[part 1 of 3: package /STLASWCs]
AUTOSAR XML (schema 4-3-0)
package /STLASWCs
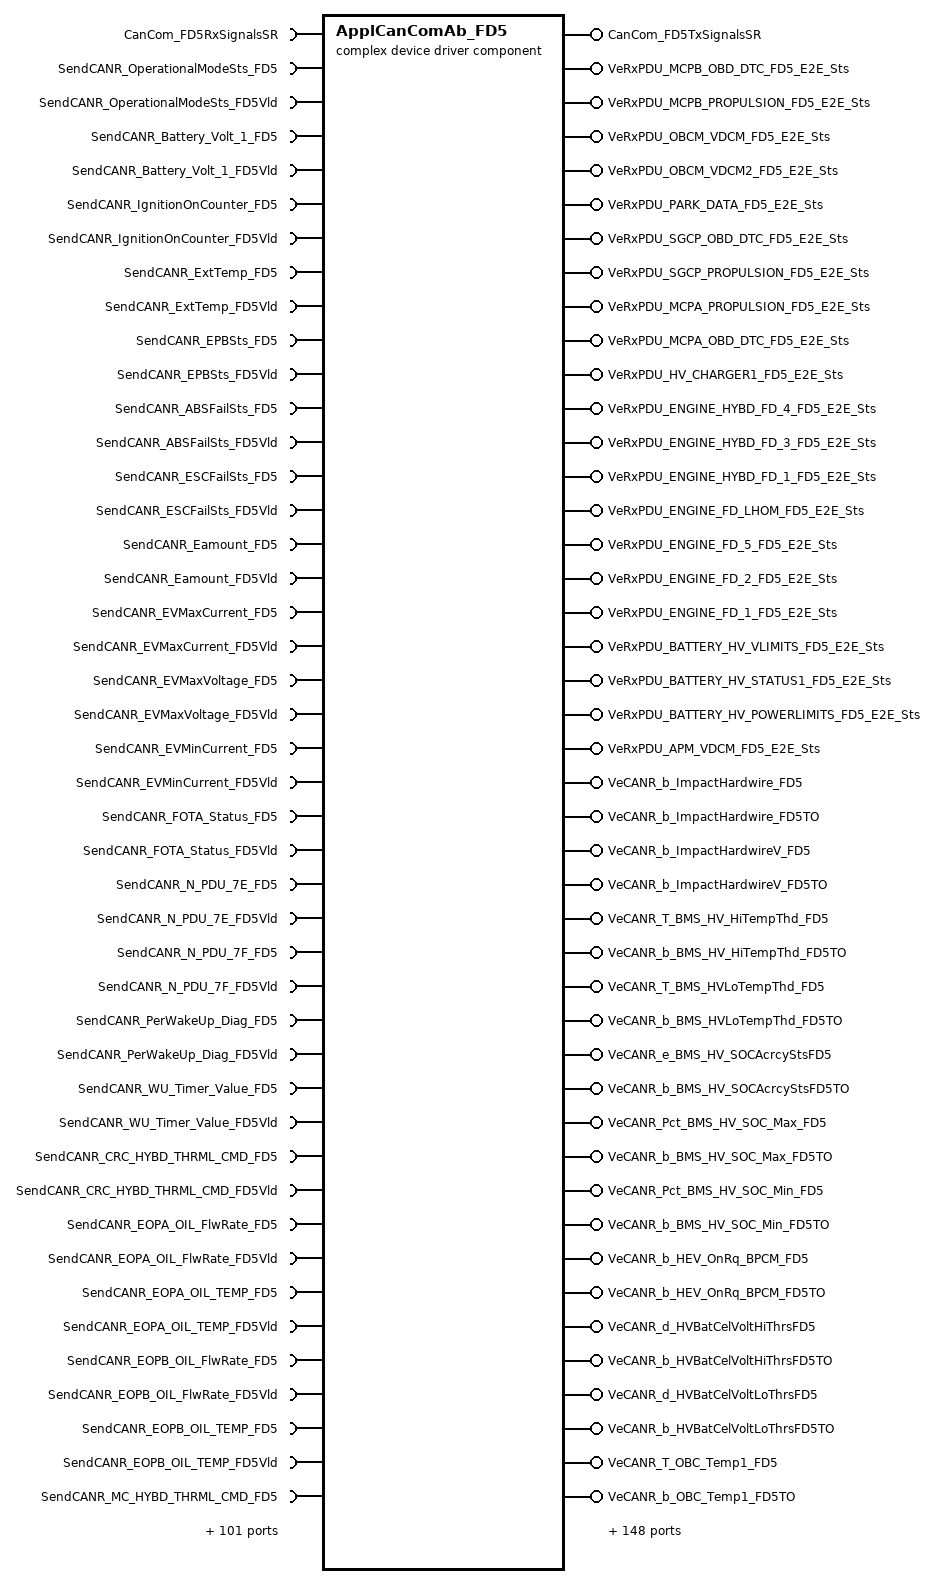
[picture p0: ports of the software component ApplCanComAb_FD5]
  complex device driver sw component type ApplCanComAb_FD5  # Application CAN Communication Abstraction Component - is responsible with receiving and sending CAN data from/to the lower BSW COM layers
    22 x provide port:
      CanCom_FD5TxSignalsSR: provided-interface=CanCom_FD5TxSignalsSR
        provided-com-specs:
          data-element=COMTX_OperationalModeSts_BCM_FD_2_FD5, init-value=constant-reference=COMTX_OperationalModeSts_BCM_FD_2_FD5_Init
          data-element=COMTX_Battery_Volt_1_BCM_FD_3_FD5, init-value=constant-reference=COMTX_Battery_Volt_1_BCM_FD_3_FD5_Init
          data-element=COMTX_IgnitionOnCounter_BCM_FD_7_FD5, init-value=constant-reference=COMTX_IgnitionOnCounter_BCM_FD_7_FD5_Init
          data-element=COMTX_ExternalTemperature_BCM_FD_9_FD5, init-value=constant-reference=COMTX_ExternalTemperature_BCM_FD_9_FD5_Init
          data-element=COMTX_EPBSts_BRAKE_FD_4_FD5, init-value=constant-reference=COMTX_EPBSts_BRAKE_FD_4_FD5_Init
          data-element=COMTX_ABSFailSts_BRAKE_FD_5_FD5, init-value=constant-reference=COMTX_ABSFailSts_BRAKE_FD_5_FD5_Init
          data-element=COMTX_ESCFailSts_BRAKE_FD_5_FD5, init-value=constant-reference=COMTX_ESCFailSts_BRAKE_FD_5_FD5_Init
          data-element=COMTX_Eamount_EVCU_ISO15118_STATUS1_FD5, init-value=constant-reference=COMTX_Eamount_EVCU_ISO15118_STATUS1_FD5_Init
          data-element=COMTX_EVMaxCurrent_EVCU_ISO15118_STATUS1_FD5, init-value=constant-reference=COMTX_EVMaxCurrent_EVCU_ISO15118_STATUS1_FD5_Init
          data-element=COMTX_EVMaxVoltage_EVCU_ISO15118_STATUS1_FD5, init-value=constant-reference=COMTX_EVMaxVoltage_EVCU_ISO15118_STATUS1_FD5_Init
          data-element=COMTX_EVMinCurrent_EVCU_ISO15118_STATUS1_FD5, init-value=constant-reference=COMTX_EVMinCurrent_EVCU_ISO15118_STATUS1_FD5_Init
          data-element=COMTX_FOTA_Status_FOTA_MASTER_FD5, init-value=constant-reference=COMTX_FOTA_Status_FOTA_MASTER_FD5_Init
          data-element=COMTX_N_PDU_7E_GLIWA_MCPA_RX_FD5, init-value=constant-reference=COMTX_N_PDU_7E_GLIWA_MCPA_RX_FD5_Init
          data-element=COMTX_N_PDU_7F_GLIWA_MCPB_RX_FD5, init-value=constant-reference=COMTX_N_PDU_7F_GLIWA_MCPB_RX_FD5_Init
          data-element=COMTX_PerWakeUp_Diag_HYBRID_SYSTEM_EPT1_FD5, init-value=constant-reference=COMTX_PerWakeUp_Diag_HYBRID_SYSTEM_EPT1_FD5_Init
          data-element=COMTX_WU_Timer_Value_HYBRID_SYSTEM_EPT1_FD5, init-value=constant-reference=COMTX_WU_Timer_Value_HYBRID_SYSTEM_EPT1_FD5_Init
          data-element=COMTX_CRC_HYBRID_THERMAL_COMMAND_HYBRID_THERMAL_COMMAND_FD5, init-value=constant-reference=COMTX_CRC_HYBRID_THERMAL_COMMAND_HYBRID_THERMAL_COMMAND_FD5_Init
          data-element=COMTX_EOPA_OIL_FlwRate_HYBRID_THERMAL_COMMAND_FD5, init-value=constant-reference=COMTX_EOPA_OIL_FlwRate_HYBRID_THERMAL_COMMAND_FD5_Init
          data-element=COMTX_EOPA_OIL_TEMP_HYBRID_THERMAL_COMMAND_FD5, init-value=constant-reference=COMTX_EOPA_OIL_TEMP_HYBRID_THERMAL_COMMAND_FD5_Init
          data-element=COMTX_EOPB_OIL_FlwRate_HYBRID_THERMAL_COMMAND_FD5, init-value=constant-reference=COMTX_EOPB_OIL_FlwRate_HYBRID_THERMAL_COMMAND_FD5_Init
          data-element=COMTX_EOPB_OIL_TEMP_HYBRID_THERMAL_COMMAND_FD5, init-value=constant-reference=COMTX_EOPB_OIL_TEMP_HYBRID_THERMAL_COMMAND_FD5_Init
          data-element=COMTX_MessageCounter_HYBRID_THERMAL_COMMAND_HYBRID_THERMAL_COMMAND_FD5, init-value=constant-reference=COMTX_MessageCounter_HYBRID_THERMAL_COMMAND_HYBRID_THERMAL_COMMAND_FD5_Init
          data-element=COMTX_SGCP_OIL_FlwRate_HYBRID_THERMAL_COMMAND_FD5, init-value=constant-reference=COMTX_SGCP_OIL_FlwRate_HYBRID_THERMAL_COMMAND_FD5_Init
          data-element=COMTX_SGCP_OIL_TEMP_HYBRID_THERMAL_COMMAND_FD5, init-value=constant-reference=COMTX_SGCP_OIL_TEMP_HYBRID_THERMAL_COMMAND_FD5_Init
          data-element=COMTX_IMPACTCommand_IMPACT_INFO_FD5, init-value=constant-reference=COMTX_IMPACTCommand_IMPACT_INFO_FD5_Init
          data-element=COMTX_IMPACTConfirm_IMPACT_INFO_FD5, init-value=constant-reference=COMTX_IMPACTConfirm_IMPACT_INFO_FD5_Init
          data-element=COMTX_TotalOdometer_IPC_FD_1_FD5, init-value=constant-reference=COMTX_TotalOdometer_IPC_FD_1_FD5_Init
          data-element=COMTX_Real_Time_Clock_REAL_TIME_CLOCK_FD5, init-value=constant-reference=COMTX_Real_Time_Clock_REAL_TIME_CLOCK_FD5_Init
          data-element=COMTX_Real_Time_Validity_REAL_TIME_CLOCK_FD5, init-value=constant-reference=COMTX_Real_Time_Validity_REAL_TIME_CLOCK_FD5_Init
          data-element=COMTX_V2H_HVCMS_EVMax_P_Limit_RPF_FD_3_FD5, init-value=constant-reference=COMTX_V2H_HVCMS_EVMax_P_Limit_RPF_FD_3_FD5_Init
          data-element=COMTX_GPS_Date_Day_TELEMATIC_FD_1_FD5, init-value=constant-reference=COMTX_GPS_Date_Day_TELEMATIC_FD_1_FD5_Init
          data-element=COMTX_GPS_Date_Month_TELEMATIC_FD_1_FD5, init-value=constant-reference=COMTX_GPS_Date_Month_TELEMATIC_FD_1_FD5_Init
          data-element=COMTX_GPS_Date_Year_TELEMATIC_FD_1_FD5, init-value=constant-reference=COMTX_GPS_Date_Year_TELEMATIC_FD_1_FD5_Init
          data-element=COMTX_GPS_UTC_Hour_TELEMATIC_FD_1_FD5, init-value=constant-reference=COMTX_GPS_UTC_Hour_TELEMATIC_FD_1_FD5_Init
          data-element=COMTX_GPS_UTC_Minute_TELEMATIC_FD_1_FD5, init-value=constant-reference=COMTX_GPS_UTC_Minute_TELEMATIC_FD_1_FD5_Init
          data-element=COMTX_GPS_UTC_Second_TELEMATIC_FD_1_FD5, init-value=constant-reference=COMTX_GPS_UTC_Second_TELEMATIC_FD_1_FD5_Init
          data-element=COMTX_HVCMS_BulkChargingComplete_VDCM_OBCM_FD5, init-value=constant-reference=COMTX_HVCMS_BulkChargingComplete_VDCM_OBCM_FD5_Init
          data-element=COMTX_HVCMS_ChargingComplete_VDCM_OBCM_FD5, init-value=constant-reference=COMTX_HVCMS_ChargingComplete_VDCM_OBCM_FD5_Init
          data-element=COMTX_HVCMS_EVEnergyCapacity_VDCM_OBCM_FD5, init-value=constant-reference=COMTX_HVCMS_EVEnergyCapacity_VDCM_OBCM_FD5_Init
          data-element=COMTX_HVCMS_EVEnergyRequest_VDCM_OBCM_FD5, init-value=constant-reference=COMTX_HVCMS_EVEnergyRequest_VDCM_OBCM_FD5_Init
          data-element=COMTX_HVCMS_EVErrorCode_VDCM_OBCM_FD5, init-value=constant-reference=COMTX_HVCMS_EVErrorCode_VDCM_OBCM_FD5_Init
          data-element=COMTX_HVCMS_EVMax_I_Limit_VDCM_OBCM_FD5, init-value=constant-reference=COMTX_HVCMS_EVMax_I_Limit_VDCM_OBCM_FD5_Init
          data-element=COMTX_HVCMS_EVMax_P_Limit_VDCM_OBCM_FD5, init-value=constant-reference=COMTX_HVCMS_EVMax_P_Limit_VDCM_OBCM_FD5_Init
          data-element=COMTX_HVCMS_EVMax_V_Limit_VDCM_OBCM_FD5, init-value=constant-reference=COMTX_HVCMS_EVMax_V_Limit_VDCM_OBCM_FD5_Init
          data-element=COMTX_HVCMS_EVReady_VDCM_OBCM_FD5, init-value=constant-reference=COMTX_HVCMS_EVReady_VDCM_OBCM_FD5_Init
          data-element=COMTX_HVCMS_EVRESS_SOC_VDCM_OBCM_FD5, init-value=constant-reference=COMTX_HVCMS_EVRESS_SOC_VDCM_OBCM_FD5_Init
          data-element=COMTX_HVCMS_EVRESSConditioning_VDCM_OBCM_FD5, init-value=constant-reference=COMTX_HVCMS_EVRESSConditioning_VDCM_OBCM_FD5_Init
          data-element=COMTX_HVCMS_EVTargetCurrent_VDCM_OBCM_FD5, init-value=constant-reference=COMTX_HVCMS_EVTargetCurrent_VDCM_OBCM_FD5_Init
          data-element=COMTX_HVCMS_EVTargetVoltage_VDCM_OBCM_FD5, init-value=constant-reference=COMTX_HVCMS_EVTargetVoltage_VDCM_OBCM_FD5_Init
          data-element=COMTX_HVCMS_Protocol_Entry{1..3}_VDCM_OBCM_FD5, init-value=constant-reference=COMTX_HVCMS_Protocol_Entry{1..3}_VDCM_OBCM_FD5_Init
          data-element=COMTX_HVCMS_ReadyToChargeState_VDCM_OBCM_FD5, init-value=constant-reference=COMTX_HVCMS_ReadyToChargeState_VDCM_OBCM_FD5_Init
          data-element=COMTX_HVCMS_RemaningTimeToBulkSOC_VDCM_OBCM_FD5, init-value=constant-reference=COMTX_HVCMS_RemaningTimeToBulkSOC_VDCM_OBCM_FD5_Init
          data-element=COMTX_HVCMS_RemaningTimeToFullSOC_VDCM_OBCM_FD5, init-value=constant-reference=COMTX_HVCMS_RemaningTimeToFullSOC_VDCM_OBCM_FD5_Init
          data-element=COMTX_HVCMS_SelectedEnergyTransferType_VDCM_OBCM_FD5, init-value=constant-reference=COMTX_HVCMS_SelectedEnergyTransferType_VDCM_OBCM_FD5_Init
          data-element=COMTX_HVCMS_SelectedPaymentOptn_VDCM_OBCM_FD5, init-value=constant-reference=COMTX_HVCMS_SelectedPaymentOptn_VDCM_OBCM_FD5_Init
          data-element=COMTX_HVCMS_SelectedServiceId_VDCM_OBCM_FD5, init-value=constant-reference=COMTX_HVCMS_SelectedServiceId_VDCM_OBCM_FD5_Init
          data-element=COMTX_HVCMS_ServiceCategory_VDCM_OBCM_FD5, init-value=constant-reference=COMTX_HVCMS_ServiceCategory_VDCM_OBCM_FD5_Init
          data-element=COMTX_HVCMS_ServiceScope_VDCM_OBCM_FD5, init-value=constant-reference=COMTX_HVCMS_ServiceScope_VDCM_OBCM_FD5_Init
          data-element=COMTX_OBCM_OutVoltageSyncTgt_VDCM_OBCM_FD5, init-value=constant-reference=COMTX_OBCM_OutVoltageSyncTgt_VDCM_OBCM_FD5_Init
          data-element=COMTX_VDCM_BattBulkSOC_VDCM_OBCM_FD5, init-value=constant-reference=COMTX_VDCM_BattBulkSOC_VDCM_OBCM_FD5_Init
          data-element=COMTX_VDCM_ContractAuthenticationID_VDCM_OBCM_FD5, init-value=constant-reference=COMTX_VDCM_ContractAuthenticationID_VDCM_OBCM_FD5_Init
          data-element=COMTX_VDCM_GenChallenge_VDCM_OBCM_FD5, init-value=constant-reference=COMTX_VDCM_GenChallenge_VDCM_OBCM_FD5_Init
          data-element=COMTX_VDCM_OBCDischCurrentLim_VDCM_OBCM_FD5, init-value=constant-reference=COMTX_VDCM_OBCDischCurrentLim_VDCM_OBCM_FD5_Init
          data-element=COMTX_VDCM_TypeCNegotiationSts_VDCM_OBCM_FD5, init-value=constant-reference=COMTX_VDCM_TypeCNegotiationSts_VDCM_OBCM_FD5_Init
          data-element=COMTX_ClrLgsDiagInfo_VDCM_PWT3_FD5, init-value=constant-reference=COMTX_ClrLgsDiagInfo_VDCM_PWT3_FD5_Init
          data-element=COMTX_T4_Sensor_Temp_VDCM_PWT3_FD5, init-value=constant-reference=COMTX_T4_Sensor_Temp_VDCM_PWT3_FD5_Init
          data-element=COMTX_T7_CoolantTempVldty_VDCM_PWT3_FD5, init-value=constant-reference=COMTX_T7_CoolantTempVldty_VDCM_PWT3_FD5_Init
          data-element=COMTX_T7_Sensor_Temp_VDCM_PWT3_FD5, init-value=constant-reference=COMTX_T7_Sensor_Temp_VDCM_PWT3_FD5_Init
          data-element=COMTX_VIN_DATA_VIN_FD5, init-value=constant-reference=COMTX_VIN_DATA_VIN_FD5_Init
          data-element=COMTX_VIN_MSG_VIN_FD5, init-value=constant-reference=COMTX_VIN_MSG_VIN_FD5_Init
      VeRxPDU_MCPB_OBD_DTC_FD5_E2E_Sts: provided-com-specs=[{data-element=E2ECheckSts, init-value=0}, {data-element=OpRetVal, init-value=0}], provided-interface=VeRxPDU_MCPB_OBD_DTC_FD5_E2E_Sts
      VeRxPDU_MCPB_PROPULSION_FD5_E2E_Sts: provided-com-specs=[{data-element=E2ECheckSts, init-value=0}, {data-element=OpRetVal, init-value=0}], provided-interface=VeRxPDU_MCPB_PROPULSION_FD5_E2E_Sts
      VeRxPDU_OBCM_VDCM_FD5_E2E_Sts: provided-com-specs=[{data-element=E2ECheckSts, init-value=0}, {data-element=OpRetVal, init-value=0}], provided-interface=VeRxPDU_OBCM_VDCM_FD5_E2E_Sts
      VeRxPDU_OBCM_VDCM2_FD5_E2E_Sts: provided-com-specs=[{data-element=E2ECheckSts, init-value=0}, {data-element=OpRetVal, init-value=0}], provided-interface=VeRxPDU_OBCM_VDCM2_FD5_E2E_Sts
      VeRxPDU_PARK_DATA_FD5_E2E_Sts: provided-com-specs=[{data-element=E2ECheckSts, init-value=0}, {data-element=OpRetVal, init-value=0}], provided-interface=VeRxPDU_PARK_DATA_FD5_E2E_Sts
      VeRxPDU_SGCP_OBD_DTC_FD5_E2E_Sts: provided-com-specs=[{data-element=E2ECheckSts, init-value=0}, {data-element=OpRetVal, init-value=0}], provided-interface=VeRxPDU_SGCP_OBD_DTC_FD5_E2E_Sts
      VeRxPDU_SGCP_PROPULSION_FD5_E2E_Sts: provided-com-specs=[{data-element=E2ECheckSts, init-value=0}, {data-element=OpRetVal, init-value=0}], provided-interface=VeRxPDU_SGCP_PROPULSION_FD5_E2E_Sts
      VeRxPDU_MCPA_PROPULSION_FD5_E2E_Sts: provided-com-specs=[{data-element=E2ECheckSts, init-value=0}, {data-element=OpRetVal, init-value=0}], provided-interface=VeRxPDU_MCPA_PROPULSION_FD5_E2E_Sts
      VeRxPDU_MCPA_OBD_DTC_FD5_E2E_Sts: provided-com-specs=[{data-element=E2ECheckSts, init-value=0}, {data-element=OpRetVal, init-value=0}], provided-interface=VeRxPDU_MCPA_OBD_DTC_FD5_E2E_Sts
      VeRxPDU_HV_CHARGER1_FD5_E2E_Sts: provided-com-specs=[{data-element=E2ECheckSts, init-value=0}, {data-element=OpRetVal, init-value=0}], provided-interface=VeRxPDU_HV_CHARGER1_FD5_E2E_Sts
      VeRxPDU_ENGINE_HYBD_FD_4_FD5_E2E_Sts: provided-com-specs=[{data-element=E2ECheckSts, init-value=0}, {data-element=OpRetVal, init-value=0}], provided-interface=VeRxPDU_ENGINE_HYBD_FD_4_FD5_E2E_Sts
      VeRxPDU_ENGINE_HYBD_FD_3_FD5_E2E_Sts: provided-com-specs=[{data-element=E2ECheckSts, init-value=0}, {data-element=OpRetVal, init-value=0}], provided-interface=VeRxPDU_ENGINE_HYBD_FD_3_FD5_E2E_Sts
      VeRxPDU_ENGINE_HYBD_FD_1_FD5_E2E_Sts: provided-com-specs=[{data-element=E2ECheckSts, init-value=0}, {data-element=OpRetVal, init-value=0}], provided-interface=VeRxPDU_ENGINE_HYBD_FD_1_FD5_E2E_Sts
      VeRxPDU_ENGINE_FD_LHOM_FD5_E2E_Sts: provided-com-specs=[{data-element=E2ECheckSts, init-value=0}, {data-element=OpRetVal, init-value=0}], provided-interface=VeRxPDU_ENGINE_FD_LHOM_FD5_E2E_Sts
      VeRxPDU_ENGINE_FD_5_FD5_E2E_Sts: provided-com-specs=[{data-element=E2ECheckSts, init-value=0}, {data-element=OpRetVal, init-value=0}], provided-interface=VeRxPDU_ENGINE_FD_5_FD5_E2E_Sts
      VeRxPDU_ENGINE_FD_2_FD5_E2E_Sts: provided-com-specs=[{data-element=E2ECheckSts, init-value=0}, {data-element=OpRetVal, init-value=0}], provided-interface=VeRxPDU_ENGINE_FD_2_FD5_E2E_Sts
      VeRxPDU_ENGINE_FD_1_FD5_E2E_Sts: provided-com-specs=[{data-element=E2ECheckSts, init-value=0}, {data-element=OpRetVal, init-value=0}], provided-interface=VeRxPDU_ENGINE_FD_1_FD5_E2E_Sts
      VeRxPDU_BATTERY_HV_VLIMITS_FD5_E2E_Sts: provided-com-specs=[{data-element=E2ECheckSts, init-value=0}, {data-element=OpRetVal, init-value=0}], provided-interface=VeRxPDU_BATTERY_HV_VLIMITS_FD5_E2E_Sts
      VeRxPDU_BATTERY_HV_STATUS1_FD5_E2E_Sts: provided-com-specs=[{data-element=E2ECheckSts, init-value=0}, {data-element=OpRetVal, init-value=0}], provided-interface=VeRxPDU_BATTERY_HV_STATUS1_FD5_E2E_Sts
      VeRxPDU_BATTERY_HV_POWERLIMITS_FD5_E2E_Sts: provided-com-specs=[{data-element=E2ECheckSts, init-value=0}, {data-element=OpRetVal, init-value=0}], provided-interface=VeRxPDU_BATTERY_HV_POWERLIMITS_FD5_E2E_Sts
      VeRxPDU_APM_VDCM_FD5_E2E_Sts: provided-com-specs=[{data-element=E2ECheckSts, init-value=0}, {data-element=OpRetVal, init-value=0}], provided-interface=VeRxPDU_APM_VDCM_FD5_E2E_Sts
    require port CanCom_FD5RxSignalsSR: required-interface=CanCom_FD5RxSignalsSR
      required-com-specs:
        data-element=COMRX_ImpactHardwire_BATTERY_HV_FD5, alive-timeout=0.1, handle-never-received=true, init-value=constant-reference=COMRX_ImpactHardwire_BATTERY_HV_FD5_Init
        data-element=COMRX_ImpactHardwireV_BATTERY_HV_FD5, alive-timeout=0.1, handle-never-received=true, init-value=constant-reference=COMRX_ImpactHardwireV_BATTERY_HV_FD5_Init
        data-element=COMRX_BMS_HV_High_Temp_Thrsh_BATTERY_HV2_FD5, alive-timeout=5, handle-never-received=true, init-value=constant-reference=COMRX_BMS_HV_High_Temp_Thrsh_BATTERY_HV2_FD5_Init
        data-element=COMRX_BMS_HV_Low_Temp_Thrsh_BATTERY_HV2_FD5, alive-timeout=5, handle-never-received=true, init-value=constant-reference=COMRX_BMS_HV_Low_Temp_Thrsh_BATTERY_HV2_FD5_Init
        data-element=COMRX_BMS_HV_SOC_AccuracySts_BATTERY_HV2_FD5, alive-timeout=5, handle-never-received=true, init-value=constant-reference=COMRX_BMS_HV_SOC_AccuracySts_BATTERY_HV2_FD5_Init
        data-element=COMRX_BMS_HV_SOC_Max_BATTERY_HV2_FD5, alive-timeout=5, handle-never-received=true, init-value=constant-reference=COMRX_BMS_HV_SOC_Max_BATTERY_HV2_FD5_Init
        data-element=COMRX_BMS_HV_SOC_Min_BATTERY_HV2_FD5, alive-timeout=5, handle-never-received=true, init-value=constant-reference=COMRX_BMS_HV_SOC_Min_BATTERY_HV2_FD5_Init
        data-element=COMRX_HEV_OnRq_BPCM_BATTERY_HV2_FD5, alive-timeout=5, handle-never-received=true, init-value=constant-reference=COMRX_HEV_OnRq_BPCM_BATTERY_HV2_FD5_Init
        data-element=COMRX_HVBatCell_Voltage_High_Thrsh_BATTERY_HV2_FD5, alive-timeout=5, handle-never-received=true, init-value=constant-reference=COMRX_HVBatCell_Voltage_High_Thrsh_BATTERY_HV2_FD5_Init
        data-element=COMRX_HVBatCell_Voltage_Low_Thrsh_BATTERY_HV2_FD5, alive-timeout=5, handle-never-received=true, init-value=constant-reference=COMRX_HVBatCell_Voltage_Low_Thrsh_BATTERY_HV2_FD5_Init
        data-element=COMRX_OBC_Temp{1..4}_DUALCHARGER_THERMAL_FD5, alive-timeout=2.5, handle-never-received=true, init-value=constant-reference=COMRX_OBC_Temp{1..4}_DUALCHARGER_THERMAL_FD5_Init
        data-element=COMRX_N_PDU_7B_GLIWA_MCPA_TX_FD5, handle-never-received=true, init-value=constant-reference=COMRX_N_PDU_7B_GLIWA_MCPA_TX_FD5_Init
        data-element=COMRX_N_PDU_7C_GLIWA_MCPB_TX_FD5, handle-never-received=true, init-value=constant-reference=COMRX_N_PDU_7C_GLIWA_MCPB_TX_FD5_Init
        data-element=COMRX_HVBatSleepTime_HVBATTERY_THERMAL_FD5, alive-timeout=1, handle-never-received=true, init-value=constant-reference=COMRX_HVBatSleepTime_HVBATTERY_THERMAL_FD5_Init
        data-element=COMRX_ACplug_PwrMax_HV_CHARGER2_FD5, alive-timeout=5, handle-never-received=true, init-value=constant-reference=COMRX_ACplug_PwrMax_HV_CHARGER2_FD5_Init
        data-element=COMRX_Charging_WHr_HV_CHARGER2_FD5, alive-timeout=5, handle-never-received=true, init-value=constant-reference=COMRX_Charging_WHr_HV_CHARGER2_FD5_Init
        data-element=COMRX_ChrgFailSts_HV_CHARGER2_FD5, alive-timeout=5, handle-never-received=true, init-value=constant-reference=COMRX_ChrgFailSts_HV_CHARGER2_FD5_Init
        data-element=COMRX_OBC_CaptureEnvironmentData_HV_CHARGER2_FD5, alive-timeout=5, handle-never-received=true, init-value=constant-reference=COMRX_OBC_CaptureEnvironmentData_HV_CHARGER2_FD5_Init
        data-element=COMRX_OBC_ChargeFailure_HV_CHARGER2_FD5, alive-timeout=5, handle-never-received=true, init-value=constant-reference=COMRX_OBC_ChargeFailure_HV_CHARGER2_FD5_Init
        data-element=COMRX_OBC_ChargeTimeMin_HV_CHARGER2_FD5, alive-timeout=5, handle-never-received=true, init-value=constant-reference=COMRX_OBC_ChargeTimeMin_HV_CHARGER2_FD5_Init
        data-element=COMRX_OBC_ChargeTimeSec_HV_CHARGER2_FD5, alive-timeout=5, handle-never-received=true, init-value=constant-reference=COMRX_OBC_ChargeTimeSec_HV_CHARGER2_FD5_Init
        data-element=COMRX_OBC_ChargingFaultSts_HV_CHARGER2_FD5, alive-timeout=5, handle-never-received=true, init-value=constant-reference=COMRX_OBC_ChargingFaultSts_HV_CHARGER2_FD5_Init
        data-element=COMRX_OBC_CurrentFailureSts_HV_CHARGER2_FD5, alive-timeout=5, handle-never-received=true, init-value=constant-reference=COMRX_OBC_CurrentFailureSts_HV_CHARGER2_FD5_Init
        data-element=COMRX_OBC_EVServiceLampFlash_HV_CHARGER2_FD5, alive-timeout=5, handle-never-received=true, init-value=constant-reference=COMRX_OBC_EVServiceLampFlash_HV_CHARGER2_FD5_Init
        data-element=COMRX_OBC_EVServiceLampOn_HV_CHARGER2_FD5, alive-timeout=5, handle-never-received=true, init-value=constant-reference=COMRX_OBC_EVServiceLampOn_HV_CHARGER2_FD5_Init
        data-element=COMRX_OBC_FaultReason_HV_CHARGER2_FD5, alive-timeout=5, handle-never-received=true, init-value=constant-reference=COMRX_OBC_FaultReason_HV_CHARGER2_FD5_Init
        data-element=COMRX_OBC_GenericFailSts_HV_CHARGER2_FD5, alive-timeout=5, handle-never-received=true, init-value=constant-reference=COMRX_OBC_GenericFailSts_HV_CHARGER2_FD5_Init
        data-element=COMRX_OBC_IdleTimeMin_HV_CHARGER2_FD5, alive-timeout=5, handle-never-received=true, init-value=constant-reference=COMRX_OBC_IdleTimeMin_HV_CHARGER2_FD5_Init
        data-element=COMRX_OBC_IdleTimeSec_HV_CHARGER2_FD5, alive-timeout=5, handle-never-received=true, init-value=constant-reference=COMRX_OBC_IdleTimeSec_HV_CHARGER2_FD5_Init
        data-element=COMRX_OBC_Pilot_HV_CHARGER2_FD5, alive-timeout=5, handle-never-received=true, init-value=constant-reference=COMRX_OBC_Pilot_HV_CHARGER2_FD5_Init
        data-element=COMRX_OBC_Prox_HV_CHARGER2_FD5, alive-timeout=5, handle-never-received=true, init-value=constant-reference=COMRX_OBC_Prox_HV_CHARGER2_FD5_Init
        data-element=COMRX_OBC_WakeReason_HV_CHARGER2_FD5, alive-timeout=5, handle-never-received=true, init-value=constant-reference=COMRX_OBC_WakeReason_HV_CHARGER2_FD5_Init
        data-element=COMRX_OBCM_PrechargeSts_HV_CHARGER2_FD5, alive-timeout=5, handle-never-received=true, init-value=constant-reference=COMRX_OBCM_PrechargeSts_HV_CHARGER2_FD5_Init
        data-element=COMRX_OnboardChargerMode_HV_CHARGER2_FD5, alive-timeout=5, handle-never-received=true, init-value=constant-reference=COMRX_OnboardChargerMode_HV_CHARGER2_FD5_Init
        data-element=COMRX_OnboardChargerReady_HV_CHARGER2_FD5, alive-timeout=5, handle-never-received=true, init-value=constant-reference=COMRX_OnboardChargerReady_HV_CHARGER2_FD5_Init
        data-element=COMRX_Contract_Certificate_Present_IDCM_ISO15118_STATUS1_FD5, alive-timeout=1, handle-never-received=true, init-value=constant-reference=COMRX_Contract_Certificate_Present_IDCM_ISO15118_STATUS1_FD5_Init
        data-element=COMRX_EVSE_Offered_AC_Single_Phase_IDCM_ISO15118_STATUS1_FD5, alive-timeout=1, handle-never-received=true, init-value=constant-reference=COMRX_EVSE_Offered_AC_Single_Phase_IDCM_ISO15118_STATUS1_FD5_Init
        data-element=COMRX_EVSE_Offered_AC_Three_Phase_IDCM_ISO15118_STATUS1_FD5, alive-timeout=1, handle-never-received=true, init-value=constant-reference=COMRX_EVSE_Offered_AC_Three_Phase_IDCM_ISO15118_STATUS1_FD5_Init
        data-element=COMRX_CLrDiagInfo_MCPA_P_MCPA_STATUS_FD5, alive-timeout=0.2, handle-never-received=true, init-value=constant-reference=COMRX_CLrDiagInfo_MCPA_P_MCPA_STATUS_FD5_Init
        data-element=COMRX_CRC_MCPA_STATUS_MCPA_STATUS_FD5, alive-timeout=0.2, handle-never-received=true, init-value=constant-reference=COMRX_CRC_MCPA_STATUS_MCPA_STATUS_FD5_Init
        data-element=COMRX_MC_MCPA_STATUS_MCPA_STATUS_FD5, alive-timeout=0.2, handle-never-received=true, init-value=constant-reference=COMRX_MC_MCPA_STATUS_MCPA_STATUS_FD5_Init
        data-element=COMRX_MCPA_Control_Board_Temperature_P_MCPA_STATUS_FD5, alive-timeout=0.2, handle-never-received=true, init-value=constant-reference=COMRX_MCPA_Control_Board_Temperature_P_MCPA_STATUS_FD5_Init
        data-element=COMRX_MCPA_CoolantTemp_P_MCPA_STATUS_FD5, alive-timeout=0.2, handle-never-received=true, init-value=constant-reference=COMRX_MCPA_CoolantTemp_P_MCPA_STATUS_FD5_Init
        data-element=COMRX_MCPA_DC_Current_P_MCPA_STATUS_FD5, alive-timeout=0.2, handle-never-received=true, init-value=constant-reference=COMRX_MCPA_DC_Current_P_MCPA_STATUS_FD5_Init
        data-element=COMRX_MCPA_DC_Current_V_P_MCPA_STATUS_FD5, alive-timeout=0.2, handle-never-received=true, init-value=constant-reference=COMRX_MCPA_DC_Current_V_P_MCPA_STATUS_FD5_Init
        data-element=COMRX_MCPA_DC_Volt_V_P_MCPA_STATUS_FD5, alive-timeout=0.2, handle-never-received=true, init-value=constant-reference=COMRX_MCPA_DC_Volt_V_P_MCPA_STATUS_FD5_Init
        data-element=COMRX_MCPA_DC_Voltage_P_MCPA_STATUS_FD5, alive-timeout=0.2, handle-never-received=true, init-value=constant-reference=COMRX_MCPA_DC_Voltage_P_MCPA_STATUS_FD5_Init
        data-element=COMRX_MCPA_DerateReason_P_MCPA_STATUS_FD5, alive-timeout=0.2, handle-never-received=true, init-value=constant-reference=COMRX_MCPA_DerateReason_P_MCPA_STATUS_FD5_Init
        data-element=COMRX_MCPA_Inverter_Temp_P_MCPA_STATUS_FD5, alive-timeout=0.2, handle-never-received=true, init-value=constant-reference=COMRX_MCPA_Inverter_Temp_P_MCPA_STATUS_FD5_Init
        data-element=COMRX_MCPA_PIM_DC_Side_Busbar_Temp_P_MCPA_STATUS_FD5, alive-timeout=0.2, handle-never-received=true, init-value=constant-reference=COMRX_MCPA_PIM_DC_Side_Busbar_Temp_P_MCPA_STATUS_FD5_Init
        data-element=COMRX_MCPA_Rotor_Temperature_P_MCPA_STATUS_FD5, alive-timeout=0.2, handle-never-received=true, init-value=constant-reference=COMRX_MCPA_Rotor_Temperature_P_MCPA_STATUS_FD5_Init
        data-element=COMRX_MCPA_Service_Lamp_Request_P_MCPA_STATUS_FD5, alive-timeout=0.2, handle-never-received=true, init-value=constant-reference=COMRX_MCPA_Service_Lamp_Request_P_MCPA_STATUS_FD5_Init
        data-element=COMRX_CLrDiagInfo_MCPB_P_MCPB_STATUS_FD5, alive-timeout=0.2, handle-never-received=true, init-value=constant-reference=COMRX_CLrDiagInfo_MCPB_P_MCPB_STATUS_FD5_Init
        data-element=COMRX_CRC_MCPB_STATUS_MCPB_STATUS_FD5, alive-timeout=0.2, handle-never-received=true, init-value=constant-reference=COMRX_CRC_MCPB_STATUS_MCPB_STATUS_FD5_Init
        data-element=COMRX_MC_MCPB_STATUS_MCPB_STATUS_FD5, alive-timeout=0.2, handle-never-received=true, init-value=constant-reference=COMRX_MC_MCPB_STATUS_MCPB_STATUS_FD5_Init
        data-element=COMRX_MCPB_Control_Board_Temperature_P_MCPB_STATUS_FD5, alive-timeout=0.2, handle-never-received=true, init-value=constant-reference=COMRX_MCPB_Control_Board_Temperature_P_MCPB_STATUS_FD5_Init
        data-element=COMRX_MCPB_CoolantTemp_P_MCPB_STATUS_FD5, alive-timeout=0.2, handle-never-received=true, init-value=constant-reference=COMRX_MCPB_CoolantTemp_P_MCPB_STATUS_FD5_Init
        data-element=COMRX_MCPB_DC_Current_P_MCPB_STATUS_FD5, alive-timeout=0.2, handle-never-received=true, init-value=constant-reference=COMRX_MCPB_DC_Current_P_MCPB_STATUS_FD5_Init
        data-element=COMRX_MCPB_DC_Current_V_P_MCPB_STATUS_FD5, alive-timeout=0.2, handle-never-received=true, init-value=constant-reference=COMRX_MCPB_DC_Current_V_P_MCPB_STATUS_FD5_Init
        data-element=COMRX_MCPB_DC_Volt_V_P_MCPB_STATUS_FD5, alive-timeout=0.2, handle-never-received=true, init-value=constant-reference=COMRX_MCPB_DC_Volt_V_P_MCPB_STATUS_FD5_Init
        data-element=COMRX_MCPB_DC_Voltage_P_MCPB_STATUS_FD5, alive-timeout=0.2, handle-never-received=true, init-value=constant-reference=COMRX_MCPB_DC_Voltage_P_MCPB_STATUS_FD5_Init
        data-element=COMRX_MCPB_DerateReason_P_MCPB_STATUS_FD5, alive-timeout=0.2, handle-never-received=true, init-value=constant-reference=COMRX_MCPB_DerateReason_P_MCPB_STATUS_FD5_Init
        data-element=COMRX_MCPB_Inverter_Temp_P_MCPB_STATUS_FD5, alive-timeout=0.2, handle-never-received=true, init-value=constant-reference=COMRX_MCPB_Inverter_Temp_P_MCPB_STATUS_FD5_Init
        data-element=COMRX_MCPB_PIM_DC_Side_Busbar_Temp_P_MCPB_STATUS_FD5, alive-timeout=0.2, handle-never-received=true, init-value=constant-reference=COMRX_MCPB_PIM_DC_Side_Busbar_Temp_P_MCPB_STATUS_FD5_Init
        data-element=COMRX_MCPB_Rotor_Temperature_P_MCPB_STATUS_FD5, alive-timeout=0.2, handle-never-received=true, init-value=constant-reference=COMRX_MCPB_Rotor_Temperature_P_MCPB_STATUS_FD5_Init
        data-element=COMRX_MCPB_Service_Lamp_Request_P_MCPB_STATUS_FD5, alive-timeout=0.2, handle-never-received=true, init-value=constant-reference=COMRX_MCPB_Service_Lamp_Request_P_MCPB_STATUS_FD5_Init
        data-element=COMRX_V2H_HVCMS_EVSEMaxPowerLimit_RPF_FD_1_FD5, alive-timeout=1, handle-never-received=true, init-value=constant-reference=COMRX_V2H_HVCMS_EVSEMaxPowerLimit_RPF_FD_1_FD5_Init
        data-element=COMRX_CLrDiagInfo_SGCP_P_SGCP_STATUS_FD5, alive-timeout=0.2, handle-never-received=true, init-value=constant-reference=COMRX_CLrDiagInfo_SGCP_P_SGCP_STATUS_FD5_Init
        data-element=COMRX_CRC_SGCP_STATUS_SGCP_STATUS_FD5, alive-timeout=0.2, handle-never-received=true, init-value=constant-reference=COMRX_CRC_SGCP_STATUS_SGCP_STATUS_FD5_Init
        data-element=COMRX_MC_SGCP_STATUS_SGCP_STATUS_FD5, alive-timeout=0.2, handle-never-received=true, init-value=constant-reference=COMRX_MC_SGCP_STATUS_SGCP_STATUS_FD5_Init
        data-element=COMRX_SGCP_Control_Board_Temperature_P_SGCP_STATUS_FD5, alive-timeout=0.2, handle-never-received=true, init-value=constant-reference=COMRX_SGCP_Control_Board_Temperature_P_SGCP_STATUS_FD5_Init
        data-element=COMRX_SGCP_CoolantTemp_P_SGCP_STATUS_FD5, alive-timeout=0.2, handle-never-received=true, init-value=constant-reference=COMRX_SGCP_CoolantTemp_P_SGCP_STATUS_FD5_Init
        data-element=COMRX_SGCP_DC_Current_P_SGCP_STATUS_FD5, alive-timeout=0.2, handle-never-received=true, init-value=constant-reference=COMRX_SGCP_DC_Current_P_SGCP_STATUS_FD5_Init
        data-element=COMRX_SGCP_DC_Current_V_P_SGCP_STATUS_FD5, alive-timeout=0.2, handle-never-received=true, init-value=constant-reference=COMRX_SGCP_DC_Current_V_P_SGCP_STATUS_FD5_Init
        data-element=COMRX_SGCP_DC_Volt_V_P_SGCP_STATUS_FD5, alive-timeout=0.2, handle-never-received=true, init-value=constant-reference=COMRX_SGCP_DC_Volt_V_P_SGCP_STATUS_FD5_Init
        data-element=COMRX_SGCP_DC_Voltage_P_SGCP_STATUS_FD5, alive-timeout=0.2, handle-never-received=true, init-value=constant-reference=COMRX_SGCP_DC_Voltage_P_SGCP_STATUS_FD5_Init
        data-element=COMRX_SGCP_DerateReason_P_SGCP_STATUS_FD5, alive-timeout=0.2, handle-never-received=true, init-value=constant-reference=COMRX_SGCP_DerateReason_P_SGCP_STATUS_FD5_Init
        data-element=COMRX_SGCP_Inverter_Temp_P_SGCP_STATUS_FD5, alive-timeout=0.2, handle-never-received=true, init-value=constant-reference=COMRX_SGCP_Inverter_Temp_P_SGCP_STATUS_FD5_Init
        data-element=COMRX_SGCP_PIM_AC_Side_Busbar_Temp_P_SGCP_STATUS_FD5, alive-timeout=0.2, handle-never-received=true, init-value=constant-reference=COMRX_SGCP_PIM_AC_Side_Busbar_Temp_P_SGCP_STATUS_FD5_Init
        data-element=COMRX_SGCP_PIM_DC_Side_Busbar_Temp_P_SGCP_STATUS_FD5, alive-timeout=0.2, handle-never-received=true, init-value=constant-reference=COMRX_SGCP_PIM_DC_Side_Busbar_Temp_P_SGCP_STATUS_FD5_Init
        data-element=COMRX_SGCP_Rotor_Temperature_P_SGCP_STATUS_FD5, alive-timeout=0.2, handle-never-received=true, init-value=constant-reference=COMRX_SGCP_Rotor_Temperature_P_SGCP_STATUS_FD5_Init
        data-element=COMRX_SGCP_Service_Lamp_Request_P_SGCP_STATUS_FD5, alive-timeout=0.2, handle-never-received=true, init-value=constant-reference=COMRX_SGCP_Service_Lamp_Request_P_SGCP_STATUS_FD5_Init
    170 x provide port:
      VeCANR_b_ImpactHardwire_FD5: nonqueued-sender-com-spec{data-element=VeCANR_b_ImpactHardwire_FD5, init-value=VeCANR_b_ImpactHardwire_FD5Value:0}, provided-interface=VeCANR_b_ImpactHardwire_FD5
      VeCANR_b_ImpactHardwire_FD5TO: nonqueued-sender-com-spec{data-element=VeCANR_b_ImpactHardwire_FD5TO, init-value=VeCANR_b_ImpactHardwire_FD5TOValue:0}, provided-interface=VeCANR_b_ImpactHardwire_FD5TO
      VeCANR_b_ImpactHardwireV_FD5: nonqueued-sender-com-spec{data-element=VeCANR_b_ImpactHardwireV_FD5, init-value=VeCANR_b_ImpactHardwireV_FD5Value:0}, provided-interface=VeCANR_b_ImpactHardwireV_FD5
      VeCANR_b_ImpactHardwireV_FD5TO: nonqueued-sender-com-spec{data-element=VeCANR_b_ImpactHardwireV_FD5TO, init-value=VeCANR_b_ImpactHardwireV_FD5TOValue:0}, provided-interface=VeCANR_b_ImpactHardwireV_FD5TO
      VeCANR_T_BMS_HV_HiTempThd_FD5: nonqueued-sender-com-spec{data-element=VeCANR_T_BMS_HV_HiTempThd_FD5, init-value=VeCANR_T_BMS_HV_HiTempThd_FD5Value:-40}, provided-interface=VeCANR_T_BMS_HV_HiTempThd_FD5
      VeCANR_b_BMS_HV_HiTempThd_FD5TO: nonqueued-sender-com-spec{data-element=VeCANR_b_BMS_HV_HiTempThd_FD5TO, init-value=VeCANR_b_BMS_HV_HiTempThd_FD5TOValue:0}, provided-interface=VeCANR_b_BMS_HV_HiTempThd_FD5TO
      VeCANR_T_BMS_HVLoTempThd_FD5: nonqueued-sender-com-spec{data-element=VeCANR_T_BMS_HVLoTempThd_FD5, init-value=VeCANR_T_BMS_HVLoTempThd_FD5Value:-40}, provided-interface=VeCANR_T_BMS_HVLoTempThd_FD5
      VeCANR_b_BMS_HVLoTempThd_FD5TO: nonqueued-sender-com-spec{data-element=VeCANR_b_BMS_HVLoTempThd_FD5TO, init-value=VeCANR_b_BMS_HVLoTempThd_FD5TOValue:0}, provided-interface=VeCANR_b_BMS_HVLoTempThd_FD5TO
      VeCANR_e_BMS_HV_SOCAcrcyStsFD5: nonqueued-sender-com-spec{data-element=VeCANR_e_BMS_HV_SOCAcrcyStsFD5, init-value=VeCANR_e_BMS_HV_SOCAcrcyStsFD5Value:0}, provided-interface=VeCANR_e_BMS_HV_SOCAcrcyStsFD5
      VeCANR_b_BMS_HV_SOCAcrcyStsFD5TO: nonqueued-sender-com-spec{data-element=VeCANR_b_BMS_HV_SOCAcrcyStsFD5TO, init-value=VeCANR_b_BMS_HV_SOCAcrcyStsFD5TOValue:0}, provided-interface=VeCANR_b_BMS_HV_SOCAcrcyStsFD5TO
      VeCANR_Pct_BMS_HV_SOC_Max_FD5: nonqueued-sender-com-spec{data-element=VeCANR_Pct_BMS_HV_SOC_Max_FD5, init-value=VeCANR_Pct_BMS_HV_SOC_Max_FD5Value:19.60785}, provided-interface=VeCANR_Pct_BMS_HV_SOC_Max_FD5
      VeCANR_b_BMS_HV_SOC_Max_FD5TO: nonqueued-sender-com-spec{data-element=VeCANR_b_BMS_HV_SOC_Max_FD5TO, init-value=VeCANR_b_BMS_HV_SOC_Max_FD5TOValue:0}, provided-interface=VeCANR_b_BMS_HV_SOC_Max_FD5TO
      VeCANR_Pct_BMS_HV_SOC_Min_FD5: nonqueued-sender-com-spec{data-element=VeCANR_Pct_BMS_HV_SOC_Min_FD5, init-value=VeCANR_Pct_BMS_HV_SOC_Min_FD5Value:19.56285}, provided-interface=VeCANR_Pct_BMS_HV_SOC_Min_FD5
      VeCANR_b_BMS_HV_SOC_Min_FD5TO: nonqueued-sender-com-spec{data-element=VeCANR_b_BMS_HV_SOC_Min_FD5TO, init-value=VeCANR_b_BMS_HV_SOC_Min_FD5TOValue:0}, provided-interface=VeCANR_b_BMS_HV_SOC_Min_FD5TO
      VeCANR_b_HEV_OnRq_BPCM_FD5: nonqueued-sender-com-spec{data-element=VeCANR_b_HEV_OnRq_BPCM_FD5, init-value=VeCANR_b_HEV_OnRq_BPCM_FD5Value:0}, provided-interface=VeCANR_b_HEV_OnRq_BPCM_FD5
      VeCANR_b_HEV_OnRq_BPCM_FD5TO: nonqueued-sender-com-spec{data-element=VeCANR_b_HEV_OnRq_BPCM_FD5TO, init-value=VeCANR_b_HEV_OnRq_BPCM_FD5TOValue:0}, provided-interface=VeCANR_b_HEV_OnRq_BPCM_FD5TO
      VeCANR_d_HVBatCelVoltHiThrsFD5: nonqueued-sender-com-spec{data-element=VeCANR_d_HVBatCelVoltHiThrsFD5, init-value=VeCANR_d_HVBatCelVoltHiThrsFD5Value:0}, provided-interface=VeCANR_d_HVBatCelVoltHiThrsFD5
      VeCANR_b_HVBatCelVoltHiThrsFD5TO: nonqueued-sender-com-spec{data-element=VeCANR_b_HVBatCelVoltHiThrsFD5TO, init-value=VeCANR_b_HVBatCelVoltHiThrsFD5TOValue:0}, provided-interface=VeCANR_b_HVBatCelVoltHiThrsFD5TO
      VeCANR_d_HVBatCelVoltLoThrsFD5: nonqueued-sender-com-spec{data-element=VeCANR_d_HVBatCelVoltLoThrsFD5, init-value=VeCANR_d_HVBatCelVoltLoThrsFD5Value:0}, provided-interface=VeCANR_d_HVBatCelVoltLoThrsFD5
      VeCANR_b_HVBatCelVoltLoThrsFD5TO: nonqueued-sender-com-spec{data-element=VeCANR_b_HVBatCelVoltLoThrsFD5TO, init-value=VeCANR_b_HVBatCelVoltLoThrsFD5TOValue:0}, provided-interface=VeCANR_b_HVBatCelVoltLoThrsFD5TO
      VeCANR_T_OBC_Temp1_FD5: nonqueued-sender-com-spec{data-element=VeCANR_T_OBC_Temp1_FD5, init-value=VeCANR_T_OBC_Temp1_FD5Value:-40}, provided-interface=VeCANR_T_OBC_Temp1_FD5
      VeCANR_b_OBC_Temp1_FD5TO: nonqueued-sender-com-spec{data-element=VeCANR_b_OBC_Temp1_FD5TO, init-value=VeCANR_b_OBC_Temp1_FD5TOValue:0}, provided-interface=VeCANR_b_OBC_Temp1_FD5TO
      VeCANR_T_OBC_Temp2_FD5: nonqueued-sender-com-spec{data-element=VeCANR_T_OBC_Temp2_FD5, init-value=VeCANR_T_OBC_Temp2_FD5Value:-40}, provided-interface=VeCANR_T_OBC_Temp2_FD5
      VeCANR_b_OBC_Temp2_FD5TO: nonqueued-sender-com-spec{data-element=VeCANR_b_OBC_Temp2_FD5TO, init-value=VeCANR_b_OBC_Temp2_FD5TOValue:0}, provided-interface=VeCANR_b_OBC_Temp2_FD5TO
      VeCANR_T_OBC_Temp3_FD5: nonqueued-sender-com-spec{data-element=VeCANR_T_OBC_Temp3_FD5, init-value=VeCANR_T_OBC_Temp3_FD5Value:-40}, provided-interface=VeCANR_T_OBC_Temp3_FD5
      VeCANR_b_OBC_Temp3_FD5TO: nonqueued-sender-com-spec{data-element=VeCANR_b_OBC_Temp3_FD5TO, init-value=VeCANR_b_OBC_Temp3_FD5TOValue:0}, provided-interface=VeCANR_b_OBC_Temp3_FD5TO
      VeCANR_T_OBC_Temp4_FD5: nonqueued-sender-com-spec{data-element=VeCANR_T_OBC_Temp4_FD5, init-value=VeCANR_T_OBC_Temp4_FD5Value:-40}, provided-interface=VeCANR_T_OBC_Temp4_FD5
      VeCANR_b_OBC_Temp4_FD5TO: nonqueued-sender-com-spec{data-element=VeCANR_b_OBC_Temp4_FD5TO, init-value=VeCANR_b_OBC_Temp4_FD5TOValue:0}, provided-interface=VeCANR_b_OBC_Temp4_FD5TO
      VeCANR_cmp_N_PDU_7B_FD5: nonqueued-sender-com-spec{data-element=VeCANR_cmp_N_PDU_7B_FD5, init-value=VeCANR_cmp_N_PDU_7B_FD5Value:0}, provided-interface=VeCANR_cmp_N_PDU_7B_FD5
      VeCANR_b_N_PDU_7B_FD5TO: nonqueued-sender-com-spec{data-element=VeCANR_b_N_PDU_7B_FD5TO, init-value=VeCANR_b_N_PDU_7B_FD5TOValue:0}, provided-interface=VeCANR_b_N_PDU_7B_FD5TO
      VeCANR_cmp_N_PDU_7C_FD5: nonqueued-sender-com-spec{data-element=VeCANR_cmp_N_PDU_7C_FD5, init-value=VeCANR_cmp_N_PDU_7C_FD5Value:0}, provided-interface=VeCANR_cmp_N_PDU_7C_FD5
      VeCANR_b_N_PDU_7C_FD5TO: nonqueued-sender-com-spec{data-element=VeCANR_b_N_PDU_7C_FD5TO, init-value=VeCANR_b_N_PDU_7C_FD5TOValue:0}, provided-interface=VeCANR_b_N_PDU_7C_FD5TO
      VeCANR_t_HVBatSleepTime_FD5: nonqueued-sender-com-spec{data-element=VeCANR_t_HVBatSleepTime_FD5, init-value=VeCANR_t_HVBatSleepTime_FD5Value:0}, provided-interface=VeCANR_t_HVBatSleepTime_FD5
      VeCANR_b_HVBatSleepTime_FD5TO: nonqueued-sender-com-spec{data-element=VeCANR_b_HVBatSleepTime_FD5TO, init-value=VeCANR_b_HVBatSleepTime_FD5TOValue:0}, provided-interface=VeCANR_b_HVBatSleepTime_FD5TO
      VeCANR_P_ACplug_PwrMax_FD5: nonqueued-sender-com-spec{data-element=VeCANR_P_ACplug_PwrMax_FD5, init-value=VeCANR_P_ACplug_PwrMax_FD5Value:-32767}, provided-interface=VeCANR_P_ACplug_PwrMax_FD5
      VeCANR_b_ACplug_PwrMax_FD5TO: nonqueued-sender-com-spec{data-element=VeCANR_b_ACplug_PwrMax_FD5TO, init-value=VeCANR_b_ACplug_PwrMax_FD5TOValue:0}, provided-interface=VeCANR_b_ACplug_PwrMax_FD5TO
      VeCANR_cmp_Charging_WHr_FD5: nonqueued-sender-com-spec{data-element=VeCANR_cmp_Charging_WHr_FD5, init-value=VeCANR_cmp_Charging_WHr_FD5Value:0}, provided-interface=VeCANR_cmp_Charging_WHr_FD5
      VeCANR_b_Charging_WHr_FD5TO: nonqueued-sender-com-spec{data-element=VeCANR_b_Charging_WHr_FD5TO, init-value=VeCANR_b_Charging_WHr_FD5TOValue:0}, provided-interface=VeCANR_b_Charging_WHr_FD5TO
      VeCANR_e_ChrgFailSts_FD5: nonqueued-sender-com-spec{data-element=VeCANR_e_ChrgFailSts_FD5, init-value=VeCANR_e_ChrgFailSts_FD5Value:0}, provided-interface=VeCANR_e_ChrgFailSts_FD5
      VeCANR_b_ChrgFailSts_FD5TO: nonqueued-sender-com-spec{data-element=VeCANR_b_ChrgFailSts_FD5TO, init-value=VeCANR_b_ChrgFailSts_FD5TOValue:0}, provided-interface=VeCANR_b_ChrgFailSts_FD5TO
      VeCANR_b_OBC_CaptureEnvDataFD5: nonqueued-sender-com-spec{data-element=VeCANR_b_OBC_CaptureEnvDataFD5, init-value=VeCANR_b_OBC_CaptureEnvDataFD5Value:0}, provided-interface=VeCANR_b_OBC_CaptureEnvDataFD5
      VeCANR_b_OBC_CaptureEnvDataFD5TO: nonqueued-sender-com-spec{data-element=VeCANR_b_OBC_CaptureEnvDataFD5TO, init-value=VeCANR_b_OBC_CaptureEnvDataFD5TOValue:0}, provided-interface=VeCANR_b_OBC_CaptureEnvDataFD5TO
      VeCANR_b_OBC_ChargeFailure_FD5: nonqueued-sender-com-spec{data-element=VeCANR_b_OBC_ChargeFailure_FD5, init-value=VeCANR_b_OBC_ChargeFailure_FD5Value:0}, provided-interface=VeCANR_b_OBC_ChargeFailure_FD5
      VeCANR_b_OBC_ChargeFailure_FD5TO: nonqueued-sender-com-spec{data-element=VeCANR_b_OBC_ChargeFailure_FD5TO, init-value=VeCANR_b_OBC_ChargeFailure_FD5TOValue:0}, provided-interface=VeCANR_b_OBC_ChargeFailure_FD5TO
      VeCANR_t_OBC_ChargeTimeMin_FD5: nonqueued-sender-com-spec{data-element=VeCANR_t_OBC_ChargeTimeMin_FD5, init-value=VeCANR_t_OBC_ChargeTimeMin_FD5Value:0}, provided-interface=VeCANR_t_OBC_ChargeTimeMin_FD5
      VeCANR_b_OBC_ChargeTimeMin_FD5TO: nonqueued-sender-com-spec{data-element=VeCANR_b_OBC_ChargeTimeMin_FD5TO, init-value=VeCANR_b_OBC_ChargeTimeMin_FD5TOValue:0}, provided-interface=VeCANR_b_OBC_ChargeTimeMin_FD5TO
      VeCANR_t_OBC_ChargeTimeSec_FD5: nonqueued-sender-com-spec{data-element=VeCANR_t_OBC_ChargeTimeSec_FD5, init-value=VeCANR_t_OBC_ChargeTimeSec_FD5Value:0}, provided-interface=VeCANR_t_OBC_ChargeTimeSec_FD5
      VeCANR_b_OBC_ChargeTimeSec_FD5TO: nonqueued-sender-com-spec{data-element=VeCANR_b_OBC_ChargeTimeSec_FD5TO, init-value=VeCANR_b_OBC_ChargeTimeSec_FD5TOValue:0}, provided-interface=VeCANR_b_OBC_ChargeTimeSec_FD5TO
      VeCANR_e_OBC_ChrgnFaultSts_FD5: nonqueued-sender-com-spec{data-element=VeCANR_e_OBC_ChrgnFaultSts_FD5, init-value=VeCANR_e_OBC_ChrgnFaultSts_FD5Value:0}, provided-interface=VeCANR_e_OBC_ChrgnFaultSts_FD5
      VeCANR_b_OBC_ChrgnFaultSts_FD5TO: nonqueued-sender-com-spec{data-element=VeCANR_b_OBC_ChrgnFaultSts_FD5TO, init-value=VeCANR_b_OBC_ChrgnFaultSts_FD5TOValue:0}, provided-interface=VeCANR_b_OBC_ChrgnFaultSts_FD5TO
      VeCANR_b_OBC_CurrFailrSts_FD5: nonqueued-sender-com-spec{data-element=VeCANR_b_OBC_CurrFailrSts_FD5, init-value=VeCANR_b_OBC_CurrFailrSts_FD5Value:0}, provided-interface=VeCANR_b_OBC_CurrFailrSts_FD5
      VeCANR_b_OBC_CurrFailrSts_FD5TO: nonqueued-sender-com-spec{data-element=VeCANR_b_OBC_CurrFailrSts_FD5TO, init-value=VeCANR_b_OBC_CurrFailrSts_FD5TOValue:0}, provided-interface=VeCANR_b_OBC_CurrFailrSts_FD5TO
      VeCANR_b_OBC_EVServLampFls_FD5: nonqueued-sender-com-spec{data-element=VeCANR_b_OBC_EVServLampFls_FD5, init-value=VeCANR_b_OBC_EVServLampFls_FD5Value:0}, provided-interface=VeCANR_b_OBC_EVServLampFls_FD5
      VeCANR_b_OBC_EVServLampFls_FD5TO: nonqueued-sender-com-spec{data-element=VeCANR_b_OBC_EVServLampFls_FD5TO, init-value=VeCANR_b_OBC_EVServLampFls_FD5TOValue:0}, provided-interface=VeCANR_b_OBC_EVServLampFls_FD5TO
      VeCANR_b_OBC_EVServLampOn_FD5: nonqueued-sender-com-spec{data-element=VeCANR_b_OBC_EVServLampOn_FD5, init-value=VeCANR_b_OBC_EVServLampOn_FD5Value:0}, provided-interface=VeCANR_b_OBC_EVServLampOn_FD5
      VeCANR_b_OBC_EVServLampOn_FD5TO: nonqueued-sender-com-spec{data-element=VeCANR_b_OBC_EVServLampOn_FD5TO, init-value=VeCANR_b_OBC_EVServLampOn_FD5TOValue:0}, provided-interface=VeCANR_b_OBC_EVServLampOn_FD5TO
      VeCANR_e_OBC_FaultReason_FD5: nonqueued-sender-com-spec{data-element=VeCANR_e_OBC_FaultReason_FD5, init-value=VeCANR_e_OBC_FaultReason_FD5Value:0}, provided-interface=VeCANR_e_OBC_FaultReason_FD5
      VeCANR_b_OBC_FaultReason_FD5TO: nonqueued-sender-com-spec{data-element=VeCANR_b_OBC_FaultReason_FD5TO, init-value=VeCANR_b_OBC_FaultReason_FD5TOValue:0}, provided-interface=VeCANR_b_OBC_FaultReason_FD5TO
      VeCANR_b_OBC_GenericFailStsFD5: nonqueued-sender-com-spec{data-element=VeCANR_b_OBC_GenericFailStsFD5, init-value=VeCANR_b_OBC_GenericFailStsFD5Value:0}, provided-interface=VeCANR_b_OBC_GenericFailStsFD5
      VeCANR_b_OBC_GenericFailStsFD5TO: nonqueued-sender-com-spec{data-element=VeCANR_b_OBC_GenericFailStsFD5TO, init-value=VeCANR_b_OBC_GenericFailStsFD5TOValue:0}, provided-interface=VeCANR_b_OBC_GenericFailStsFD5TO
      VeCANR_t_OBC_IdleTimeMin_FD5: nonqueued-sender-com-spec{data-element=VeCANR_t_OBC_IdleTimeMin_FD5, init-value=VeCANR_t_OBC_IdleTimeMin_FD5Value:0}, provided-interface=VeCANR_t_OBC_IdleTimeMin_FD5
      VeCANR_b_OBC_IdleTimeMin_FD5TO: nonqueued-sender-com-spec{data-element=VeCANR_b_OBC_IdleTimeMin_FD5TO, init-value=VeCANR_b_OBC_IdleTimeMin_FD5TOValue:0}, provided-interface=VeCANR_b_OBC_IdleTimeMin_FD5TO
      VeCANR_t_OBC_IdleTimeSec_FD5: nonqueued-sender-com-spec{data-element=VeCANR_t_OBC_IdleTimeSec_FD5, init-value=VeCANR_t_OBC_IdleTimeSec_FD5Value:0}, provided-interface=VeCANR_t_OBC_IdleTimeSec_FD5
      VeCANR_b_OBC_IdleTimeSec_FD5TO: nonqueued-sender-com-spec{data-element=VeCANR_b_OBC_IdleTimeSec_FD5TO, init-value=VeCANR_b_OBC_IdleTimeSec_FD5TOValue:0}, provided-interface=VeCANR_b_OBC_IdleTimeSec_FD5TO
      VeCANR_U_OBC_Pilot_FD5: nonqueued-sender-com-spec{data-element=VeCANR_U_OBC_Pilot_FD5, init-value=VeCANR_U_OBC_Pilot_FD5Value:0}, provided-interface=VeCANR_U_OBC_Pilot_FD5
      VeCANR_b_OBC_Pilot_FD5TO: nonqueued-sender-com-spec{data-element=VeCANR_b_OBC_Pilot_FD5TO, init-value=VeCANR_b_OBC_Pilot_FD5TOValue:0}, provided-interface=VeCANR_b_OBC_Pilot_FD5TO
      VeCANR_U_OBC_Prox_FD5: nonqueued-sender-com-spec{data-element=VeCANR_U_OBC_Prox_FD5, init-value=VeCANR_U_OBC_Prox_FD5Value:0}, provided-interface=VeCANR_U_OBC_Prox_FD5
      VeCANR_b_OBC_Prox_FD5TO: nonqueued-sender-com-spec{data-element=VeCANR_b_OBC_Prox_FD5TO, init-value=VeCANR_b_OBC_Prox_FD5TOValue:0}, provided-interface=VeCANR_b_OBC_Prox_FD5TO
      VeCANR_e_OBC_WakeReason_FD5: nonqueued-sender-com-spec{data-element=VeCANR_e_OBC_WakeReason_FD5, init-value=VeCANR_e_OBC_WakeReason_FD5Value:0}, provided-interface=VeCANR_e_OBC_WakeReason_FD5
      VeCANR_b_OBC_WakeReason_FD5TO: nonqueued-sender-com-spec{data-element=VeCANR_b_OBC_WakeReason_FD5TO, init-value=VeCANR_b_OBC_WakeReason_FD5TOValue:0}, provided-interface=VeCANR_b_OBC_WakeReason_FD5TO
      VeCANR_e_OBCM_PrechargeSts_FD5: nonqueued-sender-com-spec{data-element=VeCANR_e_OBCM_PrechargeSts_FD5, init-value=VeCANR_e_OBCM_PrechargeSts_FD5Value:0}, provided-interface=VeCANR_e_OBCM_PrechargeSts_FD5
      VeCANR_b_OBCM_PrechargeSts_FD5TO: nonqueued-sender-com-spec{data-element=VeCANR_b_OBCM_PrechargeSts_FD5TO, init-value=VeCANR_b_OBCM_PrechargeSts_FD5TOValue:0}, provided-interface=VeCANR_b_OBCM_PrechargeSts_FD5TO
      VeCANR_e_OnboardChargerModeFD5: nonqueued-sender-com-spec{data-element=VeCANR_e_OnboardChargerModeFD5, init-value=VeCANR_e_OnboardChargerModeFD5Value:0}, provided-interface=VeCANR_e_OnboardChargerModeFD5
      VeCANR_b_OnboardChargerModeFD5TO: nonqueued-sender-com-spec{data-element=VeCANR_b_OnboardChargerModeFD5TO, init-value=VeCANR_b_OnboardChargerModeFD5TOValue:0}, provided-interface=VeCANR_b_OnboardChargerModeFD5TO
      VeCANR_e_OnboardChrgrReady_FD5: nonqueued-sender-com-spec{data-element=VeCANR_e_OnboardChrgrReady_FD5, init-value=VeCANR_e_OnboardChrgrReady_FD5Value:1}, provided-interface=VeCANR_e_OnboardChrgrReady_FD5
      VeCANR_b_OnboardChrgrReady_FD5TO: nonqueued-sender-com-spec{data-element=VeCANR_b_OnboardChrgrReady_FD5TO, init-value=VeCANR_b_OnboardChrgrReady_FD5TOValue:0}, provided-interface=VeCANR_b_OnboardChrgrReady_FD5TO
      VeCANR_b_Contract_Certi_PrntFD5: nonqueued-sender-com-spec{data-element=VeCANR_b_Contract_Certi_PrntFD5, init-value=VeCANR_b_Contract_Certi_PrntFD5Value:0}, provided-interface=VeCANR_b_Contract_Certi_PrntFD5
      VeCANR_b_Contract_Certi_PrntFD5TO: nonqueued-sender-com-spec{data-element=VeCANR_b_Contract_Certi_PrntFD5TO, init-value=VeCANR_b_Contract_Certi_PrntFD5TOValue:0}, provided-interface=VeCANR_b_Contract_Certi_PrntFD5TO
      VeCANR_b_EVSE_OfdACSingPhasFD5: nonqueued-sender-com-spec{data-element=VeCANR_b_EVSE_OfdACSingPhasFD5, init-value=VeCANR_b_EVSE_OfdACSingPhasFD5Value:0}, provided-interface=VeCANR_b_EVSE_OfdACSingPhasFD5
      VeCANR_b_EVSE_OfdACSingPhasFD5TO: nonqueued-sender-com-spec{data-element=VeCANR_b_EVSE_OfdACSingPhasFD5TO, init-value=VeCANR_b_EVSE_OfdACSingPhasFD5TOValue:0}, provided-interface=VeCANR_b_EVSE_OfdACSingPhasFD5TO
      VeCANR_b_EVSEOfdACThreePhasFD5: nonqueued-sender-com-spec{data-element=VeCANR_b_EVSEOfdACThreePhasFD5, init-value=VeCANR_b_EVSEOfdACThreePhasFD5Value:0}, provided-interface=VeCANR_b_EVSEOfdACThreePhasFD5
      VeCANR_b_EVSEOfdACThreePhasFD5TO: nonqueued-sender-com-spec{data-element=VeCANR_b_EVSEOfdACThreePhasFD5TO, init-value=VeCANR_b_EVSEOfdACThreePhasFD5TOValue:0}, provided-interface=VeCANR_b_EVSEOfdACThreePhasFD5TO
      VeCANR_b_CLrDiagInfo_MCPA_P_FD5: nonqueued-sender-com-spec{data-element=VeCANR_b_CLrDiagInfo_MCPA_P_FD5, init-value=VeCANR_b_CLrDiagInfo_MCPA_P_FD5Value:0}, provided-interface=VeCANR_b_CLrDiagInfo_MCPA_P_FD5
      VeCANR_b_CLrDiagInfo_MCPA_P_FD5TO: nonqueued-sender-com-spec{data-element=VeCANR_b_CLrDiagInfo_MCPA_P_FD5TO, init-value=VeCANR_b_CLrDiagInfo_MCPA_P_FD5TOValue:0}, provided-interface=VeCANR_b_CLrDiagInfo_MCPA_P_FD5TO
      VeCANR_y_CRC_MCPA_STATUS_FD5: nonqueued-sender-com-spec{data-element=VeCANR_y_CRC_MCPA_STATUS_FD5, init-value=VeCANR_y_CRC_MCPA_STATUS_FD5Value:0}, provided-interface=VeCANR_y_CRC_MCPA_STATUS_FD5
      VeCANR_b_CRC_MCPA_STATUS_FD5TO: nonqueued-sender-com-spec{data-element=VeCANR_b_CRC_MCPA_STATUS_FD5TO, init-value=VeCANR_b_CRC_MCPA_STATUS_FD5TOValue:0}, provided-interface=VeCANR_b_CRC_MCPA_STATUS_FD5TO
      VeCANR_y_MC_MCPA_STATUS_FD5: nonqueued-sender-com-spec{data-element=VeCANR_y_MC_MCPA_STATUS_FD5, init-value=VeCANR_y_MC_MCPA_STATUS_FD5Value:0}, provided-interface=VeCANR_y_MC_MCPA_STATUS_FD5
      VeCANR_b_MC_MCPA_STATUS_FD5TO: nonqueued-sender-com-spec{data-element=VeCANR_b_MC_MCPA_STATUS_FD5TO, init-value=VeCANR_b_MC_MCPA_STATUS_FD5TOValue:0}, provided-interface=VeCANR_b_MC_MCPA_STATUS_FD5TO
      VeCANR_T_MCPACtrlBoardTempP_FD5: nonqueued-sender-com-spec{data-element=VeCANR_T_MCPACtrlBoardTempP_FD5, init-value=VeCANR_T_MCPACtrlBoardTempP_FD5Value:215}, provided-interface=VeCANR_T_MCPACtrlBoardTempP_FD5
      VeCANR_b_MCPACtrlBoardTempP_FD5TO: nonqueued-sender-com-spec{data-element=VeCANR_b_MCPACtrlBoardTempP_FD5TO, init-value=VeCANR_b_MCPACtrlBoardTempP_FD5TOValue:0}, provided-interface=VeCANR_b_MCPACtrlBoardTempP_FD5TO
      VeCANR_T_MCPA_CoolntTmp_P_FD5: nonqueued-sender-com-spec{data-element=VeCANR_T_MCPA_CoolntTmp_P_FD5, init-value=VeCANR_T_MCPA_CoolntTmp_P_FD5Value:-40}, provided-interface=VeCANR_T_MCPA_CoolntTmp_P_FD5
      VeCANR_b_MCPA_CoolntTmp_P_FD5TO: nonqueued-sender-com-spec{data-element=VeCANR_b_MCPA_CoolntTmp_P_FD5TO, init-value=VeCANR_b_MCPA_CoolntTmp_P_FD5TOValue:0}, provided-interface=VeCANR_b_MCPA_CoolntTmp_P_FD5TO
      VeCANR_I_MCPA_DC_Current_P_FD5: nonqueued-sender-com-spec{data-element=VeCANR_I_MCPA_DC_Current_P_FD5, init-value=VeCANR_I_MCPA_DC_Current_P_FD5Value:0}, provided-interface=VeCANR_I_MCPA_DC_Current_P_FD5
      VeCANR_b_MCPA_DC_Current_P_FD5TO: nonqueued-sender-com-spec{data-element=VeCANR_b_MCPA_DC_Current_P_FD5TO, init-value=VeCANR_b_MCPA_DC_Current_P_FD5TOValue:0}, provided-interface=VeCANR_b_MCPA_DC_Current_P_FD5TO
      VeCANR_b_MCPA_DC_Crrent_V_P_FD5: nonqueued-sender-com-spec{data-element=VeCANR_b_MCPA_DC_Crrent_V_P_FD5, init-value=VeCANR_b_MCPA_DC_Crrent_V_P_FD5Value:0}, provided-interface=VeCANR_b_MCPA_DC_Crrent_V_P_FD5
      VeCANR_b_MCPA_DC_Crrent_V_P_FD5TO: nonqueued-sender-com-spec{data-element=VeCANR_b_MCPA_DC_Crrent_V_P_FD5TO, init-value=VeCANR_b_MCPA_DC_Crrent_V_P_FD5TOValue:0}, provided-interface=VeCANR_b_MCPA_DC_Crrent_V_P_FD5TO
      VeCANR_b_MCPA_DC_Volt_V_P_FD5: nonqueued-sender-com-spec{data-element=VeCANR_b_MCPA_DC_Volt_V_P_FD5, init-value=VeCANR_b_MCPA_DC_Volt_V_P_FD5Value:0}, provided-interface=VeCANR_b_MCPA_DC_Volt_V_P_FD5
      VeCANR_b_MCPA_DC_Volt_V_P_FD5TO: nonqueued-sender-com-spec{data-element=VeCANR_b_MCPA_DC_Volt_V_P_FD5TO, init-value=VeCANR_b_MCPA_DC_Volt_V_P_FD5TOValue:0}, provided-interface=VeCANR_b_MCPA_DC_Volt_V_P_FD5TO
      VeCANR_U_MCPA_DC_Voltage_P_FD5: nonqueued-sender-com-spec{data-element=VeCANR_U_MCPA_DC_Voltage_P_FD5, init-value=VeCANR_U_MCPA_DC_Voltage_P_FD5Value:0}, provided-interface=VeCANR_U_MCPA_DC_Voltage_P_FD5
      VeCANR_b_MCPA_DC_Voltage_P_FD5TO: nonqueued-sender-com-spec{data-element=VeCANR_b_MCPA_DC_Voltage_P_FD5TO, init-value=VeCANR_b_MCPA_DC_Voltage_P_FD5TOValue:0}, provided-interface=VeCANR_b_MCPA_DC_Voltage_P_FD5TO
      VeCANR_e_MCPA_DrateReason_P_FD5: nonqueued-sender-com-spec{data-element=VeCANR_e_MCPA_DrateReason_P_FD5, init-value=VeCANR_e_MCPA_DrateReason_P_FD5Value:0}, provided-interface=VeCANR_e_MCPA_DrateReason_P_FD5
      VeCANR_b_MCPA_DrateReason_P_FD5TO: nonqueued-sender-com-spec{data-element=VeCANR_b_MCPA_DrateReason_P_FD5TO, init-value=VeCANR_b_MCPA_DrateReason_P_FD5TOValue:0}, provided-interface=VeCANR_b_MCPA_DrateReason_P_FD5TO
      VeCANR_T_MCPA_Invert_Temp_P_FD5: nonqueued-sender-com-spec{data-element=VeCANR_T_MCPA_Invert_Temp_P_FD5, init-value=VeCANR_T_MCPA_Invert_Temp_P_FD5Value:0}, provided-interface=VeCANR_T_MCPA_Invert_Temp_P_FD5
      VeCANR_b_MCPA_Invert_Temp_P_FD5TO: nonqueued-sender-com-spec{data-element=VeCANR_b_MCPA_Invert_Temp_P_FD5TO, init-value=VeCANR_b_MCPA_Invert_Temp_P_FD5TOValue:0}, provided-interface=VeCANR_b_MCPA_Invert_Temp_P_FD5TO
      VeCANR_T_MCPAPIMDCSdBusTempPFD5: nonqueued-sender-com-spec{data-element=VeCANR_T_MCPAPIMDCSdBusTempPFD5, init-value=VeCANR_T_MCPAPIMDCSdBusTempPFD5Value:-40}, provided-interface=VeCANR_T_MCPAPIMDCSdBusTempPFD5
      VeCANR_b_MCPAPIMDCSdBusTempPFD5TO: nonqueued-sender-com-spec{data-element=VeCANR_b_MCPAPIMDCSdBusTempPFD5TO, init-value=VeCANR_b_MCPAPIMDCSdBusTempPFD5TOValue:0}, provided-interface=VeCANR_b_MCPAPIMDCSdBusTempPFD5TO
      VeCANR_T_MCPARotorTemp_P_FD5: nonqueued-sender-com-spec{data-element=VeCANR_T_MCPARotorTemp_P_FD5, init-value=VeCANR_T_MCPARotorTemp_P_FD5Value:215}, provided-interface=VeCANR_T_MCPARotorTemp_P_FD5
      VeCANR_b_MCPARotorTemp_P_FD5TO: nonqueued-sender-com-spec{data-element=VeCANR_b_MCPARotorTemp_P_FD5TO, init-value=VeCANR_b_MCPARotorTemp_P_FD5TOValue:0}, provided-interface=VeCANR_b_MCPARotorTemp_P_FD5TO
      VeCANR_b_MCPAServLampReq_P_FD5: nonqueued-sender-com-spec{data-element=VeCANR_b_MCPAServLampReq_P_FD5, init-value=VeCANR_b_MCPAServLampReq_P_FD5Value:0}, provided-interface=VeCANR_b_MCPAServLampReq_P_FD5
      VeCANR_b_MCPAServLampReq_P_FD5TO: nonqueued-sender-com-spec{data-element=VeCANR_b_MCPAServLampReq_P_FD5TO, init-value=VeCANR_b_MCPAServLampReq_P_FD5TOValue:0}, provided-interface=VeCANR_b_MCPAServLampReq_P_FD5TO
      VeCANR_b_CLrDiagInfo_MCPB_P_FD5: nonqueued-sender-com-spec{data-element=VeCANR_b_CLrDiagInfo_MCPB_P_FD5, init-value=VeCANR_b_CLrDiagInfo_MCPB_P_FD5Value:0}, provided-interface=VeCANR_b_CLrDiagInfo_MCPB_P_FD5
      VeCANR_b_CLrDiagInfo_MCPB_P_FD5TO: nonqueued-sender-com-spec{data-element=VeCANR_b_CLrDiagInfo_MCPB_P_FD5TO, init-value=VeCANR_b_CLrDiagInfo_MCPB_P_FD5TOValue:0}, provided-interface=VeCANR_b_CLrDiagInfo_MCPB_P_FD5TO
      VeCANR_y_CRC_MCPB_STATUS_FD5: nonqueued-sender-com-spec{data-element=VeCANR_y_CRC_MCPB_STATUS_FD5, init-value=VeCANR_y_CRC_MCPB_STATUS_FD5Value:0}, provided-interface=VeCANR_y_CRC_MCPB_STATUS_FD5
      VeCANR_b_CRC_MCPB_STATUS_FD5TO: nonqueued-sender-com-spec{data-element=VeCANR_b_CRC_MCPB_STATUS_FD5TO, init-value=VeCANR_b_CRC_MCPB_STATUS_FD5TOValue:0}, provided-interface=VeCANR_b_CRC_MCPB_STATUS_FD5TO
      VeCANR_y_MC_MCPB_STATUS_FD5: nonqueued-sender-com-spec{data-element=VeCANR_y_MC_MCPB_STATUS_FD5, init-value=VeCANR_y_MC_MCPB_STATUS_FD5Value:0}, provided-interface=VeCANR_y_MC_MCPB_STATUS_FD5
      VeCANR_b_MC_MCPB_STATUS_FD5TO: nonqueued-sender-com-spec{data-element=VeCANR_b_MC_MCPB_STATUS_FD5TO, init-value=VeCANR_b_MC_MCPB_STATUS_FD5TOValue:0}, provided-interface=VeCANR_b_MC_MCPB_STATUS_FD5TO
      VeCANR_y_MCPBCtrlBoardTempP_FD5: nonqueued-sender-com-spec{data-element=VeCANR_y_MCPBCtrlBoardTempP_FD5, init-value=VeCANR_y_MCPBCtrlBoardTempP_FD5Value:-40}, provided-interface=VeCANR_y_MCPBCtrlBoardTempP_FD5
      VeCANR_b_MCPBCtrlBoardTempP_FD5TO: nonqueued-sender-com-spec{data-element=VeCANR_b_MCPBCtrlBoardTempP_FD5TO, init-value=VeCANR_b_MCPBCtrlBoardTempP_FD5TOValue:0}, provided-interface=VeCANR_b_MCPBCtrlBoardTempP_FD5TO
      VeCANR_T_MCPB_CoolantTemp_P_FD5: nonqueued-sender-com-spec{data-element=VeCANR_T_MCPB_CoolantTemp_P_FD5, init-value=VeCANR_T_MCPB_CoolantTemp_P_FD5Value:-40}, provided-interface=VeCANR_T_MCPB_CoolantTemp_P_FD5
      VeCANR_b_MCPB_CoolantTemp_P_FD5TO: nonqueued-sender-com-spec{data-element=VeCANR_b_MCPB_CoolantTemp_P_FD5TO, init-value=VeCANR_b_MCPB_CoolantTemp_P_FD5TOValue:0}, provided-interface=VeCANR_b_MCPB_CoolantTemp_P_FD5TO
      VeCANR_I_MCPB_DC_Current_P_FD5: nonqueued-sender-com-spec{data-element=VeCANR_I_MCPB_DC_Current_P_FD5, init-value=VeCANR_I_MCPB_DC_Current_P_FD5Value:0}, provided-interface=VeCANR_I_MCPB_DC_Current_P_FD5
      VeCANR_b_MCPB_DC_Current_P_FD5TO: nonqueued-sender-com-spec{data-element=VeCANR_b_MCPB_DC_Current_P_FD5TO, init-value=VeCANR_b_MCPB_DC_Current_P_FD5TOValue:0}, provided-interface=VeCANR_b_MCPB_DC_Current_P_FD5TO
      VeCANR_b_MCPB_DC_Crrent_V_P_FD5: nonqueued-sender-com-spec{data-element=VeCANR_b_MCPB_DC_Crrent_V_P_FD5, init-value=VeCANR_b_MCPB_DC_Crrent_V_P_FD5Value:0}, provided-interface=VeCANR_b_MCPB_DC_Crrent_V_P_FD5
      VeCANR_b_MCPB_DC_Crrent_V_P_FD5TO: nonqueued-sender-com-spec{data-element=VeCANR_b_MCPB_DC_Crrent_V_P_FD5TO, init-value=VeCANR_b_MCPB_DC_Crrent_V_P_FD5TOValue:0}, provided-interface=VeCANR_b_MCPB_DC_Crrent_V_P_FD5TO
      VeCANR_b_MCPB_DC_Volt_V_P_FD5: nonqueued-sender-com-spec{data-element=VeCANR_b_MCPB_DC_Volt_V_P_FD5, init-value=VeCANR_b_MCPB_DC_Volt_V_P_FD5Value:0}, provided-interface=VeCANR_b_MCPB_DC_Volt_V_P_FD5
      VeCANR_b_MCPB_DC_Volt_V_P_FD5TO: nonqueued-sender-com-spec{data-element=VeCANR_b_MCPB_DC_Volt_V_P_FD5TO, init-value=VeCANR_b_MCPB_DC_Volt_V_P_FD5TOValue:0}, provided-interface=VeCANR_b_MCPB_DC_Volt_V_P_FD5TO
      VeCANR_U_MCPB_DC_Voltage_P_FD5: nonqueued-sender-com-spec{data-element=VeCANR_U_MCPB_DC_Voltage_P_FD5, init-value=VeCANR_U_MCPB_DC_Voltage_P_FD5Value:0}, provided-interface=VeCANR_U_MCPB_DC_Voltage_P_FD5
      VeCANR_b_MCPB_DC_Voltage_P_FD5TO: nonqueued-sender-com-spec{data-element=VeCANR_b_MCPB_DC_Voltage_P_FD5TO, init-value=VeCANR_b_MCPB_DC_Voltage_P_FD5TOValue:0}, provided-interface=VeCANR_b_MCPB_DC_Voltage_P_FD5TO
      VeCANR_e_MCPB_DrateReason_P_FD5: nonqueued-sender-com-spec{data-element=VeCANR_e_MCPB_DrateReason_P_FD5, init-value=VeCANR_e_MCPB_DrateReason_P_FD5Value:0}, provided-interface=VeCANR_e_MCPB_DrateReason_P_FD5
      VeCANR_b_MCPB_DrateReason_P_FD5TO: nonqueued-sender-com-spec{data-element=VeCANR_b_MCPB_DrateReason_P_FD5TO, init-value=VeCANR_b_MCPB_DrateReason_P_FD5TOValue:0}, provided-interface=VeCANR_b_MCPB_DrateReason_P_FD5TO
      VeCANR_T_MCPB_Invert_Temp_P_FD5: nonqueued-sender-com-spec{data-element=VeCANR_T_MCPB_Invert_Temp_P_FD5, init-value=VeCANR_T_MCPB_Invert_Temp_P_FD5Value:0}, provided-interface=VeCANR_T_MCPB_Invert_Temp_P_FD5
      VeCANR_b_MCPB_Invert_Temp_P_FD5TO: nonqueued-sender-com-spec{data-element=VeCANR_b_MCPB_Invert_Temp_P_FD5TO, init-value=VeCANR_b_MCPB_Invert_Temp_P_FD5TOValue:0}, provided-interface=VeCANR_b_MCPB_Invert_Temp_P_FD5TO
      VeCANR_T_MCPBIMDCSdBusTempPFD5: nonqueued-sender-com-spec{data-element=VeCANR_T_MCPBIMDCSdBusTempPFD5, init-value=VeCANR_T_MCPBIMDCSdBusTempPFD5Value:-40}, provided-interface=VeCANR_T_MCPBIMDCSdBusTempPFD5
      VeCANR_b_MCPBIMDCSdBusTempPFD5TO: nonqueued-sender-com-spec{data-element=VeCANR_b_MCPBIMDCSdBusTempPFD5TO, init-value=VeCANR_b_MCPBIMDCSdBusTempPFD5TOValue:0}, provided-interface=VeCANR_b_MCPBIMDCSdBusTempPFD5TO
      VeCANR_T_MCPBRotorTemp_P_FD5: nonqueued-sender-com-spec{data-element=VeCANR_T_MCPBRotorTemp_P_FD5, init-value=VeCANR_T_MCPBRotorTemp_P_FD5Value:215}, provided-interface=VeCANR_T_MCPBRotorTemp_P_FD5
      VeCANR_b_MCPBRotorTemp_P_FD5TO: nonqueued-sender-com-spec{data-element=VeCANR_b_MCPBRotorTemp_P_FD5TO, init-value=VeCANR_b_MCPBRotorTemp_P_FD5TOValue:0}, provided-interface=VeCANR_b_MCPBRotorTemp_P_FD5TO
      VeCANR_b_MCPBServLampReq_P_FD5: nonqueued-sender-com-spec{data-element=VeCANR_b_MCPBServLampReq_P_FD5, init-value=VeCANR_b_MCPBServLampReq_P_FD5Value:0}, provided-interface=VeCANR_b_MCPBServLampReq_P_FD5
      VeCANR_b_MCPBServLampReq_P_FD5TO: nonqueued-sender-com-spec{data-element=VeCANR_b_MCPBServLampReq_P_FD5TO, init-value=VeCANR_b_MCPBServLampReq_P_FD5TOValue:0}, provided-interface=VeCANR_b_MCPBServLampReq_P_FD5TO
      VeCANR_P_V2H_HVCMS_EVSEMxPLtFD5: nonqueued-sender-com-spec{data-element=VeCANR_P_V2H_HVCMS_EVSEMxPLtFD5, init-value=VeCANR_P_V2H_HVCMS_EVSEMxPLtFD5Value:-819.1}, provided-interface=VeCANR_P_V2H_HVCMS_EVSEMxPLtFD5
      VeCANR_b_V2H_HVCMS_EVSEMxPLtFD5TO: nonqueued-sender-com-spec{data-element=VeCANR_b_V2H_HVCMS_EVSEMxPLtFD5TO, init-value=VeCANR_b_V2H_HVCMS_EVSEMxPLtFD5TOValue:0}, provided-interface=VeCANR_b_V2H_HVCMS_EVSEMxPLtFD5TO
      VeCANR_b_CLrDiagInfo_SGCP_P_FD5: nonqueued-sender-com-spec{data-element=VeCANR_b_CLrDiagInfo_SGCP_P_FD5, init-value=VeCANR_b_CLrDiagInfo_SGCP_P_FD5Value:0}, provided-interface=VeCANR_b_CLrDiagInfo_SGCP_P_FD5
      VeCANR_b_CLrDiagInfo_SGCP_P_FD5TO: nonqueued-sender-com-spec{data-element=VeCANR_b_CLrDiagInfo_SGCP_P_FD5TO, init-value=VeCANR_b_CLrDiagInfo_SGCP_P_FD5TOValue:0}, provided-interface=VeCANR_b_CLrDiagInfo_SGCP_P_FD5TO
      VeCANR_y_CRC_SGCP_STATUS_FD5: nonqueued-sender-com-spec{data-element=VeCANR_y_CRC_SGCP_STATUS_FD5, init-value=VeCANR_y_CRC_SGCP_STATUS_FD5Value:0}, provided-interface=VeCANR_y_CRC_SGCP_STATUS_FD5
      VeCANR_b_CRC_SGCP_STATUS_FD5TO: nonqueued-sender-com-spec{data-element=VeCANR_b_CRC_SGCP_STATUS_FD5TO, init-value=VeCANR_b_CRC_SGCP_STATUS_FD5TOValue:0}, provided-interface=VeCANR_b_CRC_SGCP_STATUS_FD5TO
      VeCANR_y_MC_SGCP_STATUS_FD5: nonqueued-sender-com-spec{data-element=VeCANR_y_MC_SGCP_STATUS_FD5, init-value=VeCANR_y_MC_SGCP_STATUS_FD5Value:0}, provided-interface=VeCANR_y_MC_SGCP_STATUS_FD5
      VeCANR_b_MC_SGCP_STATUS_FD5TO: nonqueued-sender-com-spec{data-element=VeCANR_b_MC_SGCP_STATUS_FD5TO, init-value=VeCANR_b_MC_SGCP_STATUS_FD5TOValue:0}, provided-interface=VeCANR_b_MC_SGCP_STATUS_FD5TO
      VeCANR_T_SGCPCtrlBoardTempP_FD5: nonqueued-sender-com-spec{data-element=VeCANR_T_SGCPCtrlBoardTempP_FD5, init-value=VeCANR_T_SGCPCtrlBoardTempP_FD5Value:215}, provided-interface=VeCANR_T_SGCPCtrlBoardTempP_FD5
      VeCANR_b_SGCPCtrlBoardTempP_FD5TO: nonqueued-sender-com-spec{data-element=VeCANR_b_SGCPCtrlBoardTempP_FD5TO, init-value=VeCANR_b_SGCPCtrlBoardTempP_FD5TOValue:0}, provided-interface=VeCANR_b_SGCPCtrlBoardTempP_FD5TO
      VeCANR_T_SGCP_CoolantTemp_P_FD5: nonqueued-sender-com-spec{data-element=VeCANR_T_SGCP_CoolantTemp_P_FD5, init-value=VeCANR_T_SGCP_CoolantTemp_P_FD5Value:-40}, provided-interface=VeCANR_T_SGCP_CoolantTemp_P_FD5
      VeCANR_b_SGCP_CoolantTemp_P_FD5TO: nonqueued-sender-com-spec{data-element=VeCANR_b_SGCP_CoolantTemp_P_FD5TO, init-value=VeCANR_b_SGCP_CoolantTemp_P_FD5TOValue:0}, provided-interface=VeCANR_b_SGCP_CoolantTemp_P_FD5TO
      VeCANR_I_SGCP_DC_Current_P_FD5: nonqueued-sender-com-spec{data-element=VeCANR_I_SGCP_DC_Current_P_FD5, init-value=VeCANR_I_SGCP_DC_Current_P_FD5Value:0}, provided-interface=VeCANR_I_SGCP_DC_Current_P_FD5
      VeCANR_b_SGCP_DC_Current_P_FD5TO: nonqueued-sender-com-spec{data-element=VeCANR_b_SGCP_DC_Current_P_FD5TO, init-value=VeCANR_b_SGCP_DC_Current_P_FD5TOValue:0}, provided-interface=VeCANR_b_SGCP_DC_Current_P_FD5TO
      VeCANR_b_SGCP_DC_Crrent_V_P_FD5: nonqueued-sender-com-spec{data-element=VeCANR_b_SGCP_DC_Crrent_V_P_FD5, init-value=VeCANR_b_SGCP_DC_Crrent_V_P_FD5Value:0}, provided-interface=VeCANR_b_SGCP_DC_Crrent_V_P_FD5
      VeCANR_b_SGCP_DC_Crrent_V_P_FD5TO: nonqueued-sender-com-spec{data-element=VeCANR_b_SGCP_DC_Crrent_V_P_FD5TO, init-value=VeCANR_b_SGCP_DC_Crrent_V_P_FD5TOValue:0}, provided-interface=VeCANR_b_SGCP_DC_Crrent_V_P_FD5TO
      VeCANR_b_SGCP_DC_Volt_V_P_FD5: nonqueued-sender-com-spec{data-element=VeCANR_b_SGCP_DC_Volt_V_P_FD5, init-value=VeCANR_b_SGCP_DC_Volt_V_P_FD5Value:0}, provided-interface=VeCANR_b_SGCP_DC_Volt_V_P_FD5
      VeCANR_b_SGCP_DC_Volt_V_P_FD5TO: nonqueued-sender-com-spec{data-element=VeCANR_b_SGCP_DC_Volt_V_P_FD5TO, init-value=VeCANR_b_SGCP_DC_Volt_V_P_FD5TOValue:0}, provided-interface=VeCANR_b_SGCP_DC_Volt_V_P_FD5TO
      VeCANR_U_SGCP_DC_Voltage_P_FD5: nonqueued-sender-com-spec{data-element=VeCANR_U_SGCP_DC_Voltage_P_FD5, init-value=VeCANR_U_SGCP_DC_Voltage_P_FD5Value:0}, provided-interface=VeCANR_U_SGCP_DC_Voltage_P_FD5
      VeCANR_b_SGCP_DC_Voltage_P_FD5TO: nonqueued-sender-com-spec{data-element=VeCANR_b_SGCP_DC_Voltage_P_FD5TO, init-value=VeCANR_b_SGCP_DC_Voltage_P_FD5TOValue:0}, provided-interface=VeCANR_b_SGCP_DC_Voltage_P_FD5TO
      VeCANR_e_SGCP_DrateReason_P_FD5: nonqueued-sender-com-spec{data-element=VeCANR_e_SGCP_DrateReason_P_FD5, init-value=VeCANR_e_SGCP_DrateReason_P_FD5Value:0}, provided-interface=VeCANR_e_SGCP_DrateReason_P_FD5
      VeCANR_b_SGCP_DrateReason_P_FD5TO: nonqueued-sender-com-spec{data-element=VeCANR_b_SGCP_DrateReason_P_FD5TO, init-value=VeCANR_b_SGCP_DrateReason_P_FD5TOValue:0}, provided-interface=VeCANR_b_SGCP_DrateReason_P_FD5TO
      VeCANR_T_SGCP_Invert_Temp_P_FD5: nonqueued-sender-com-spec{data-element=VeCANR_T_SGCP_Invert_Temp_P_FD5, init-value=VeCANR_T_SGCP_Invert_Temp_P_FD5Value:0}, provided-interface=VeCANR_T_SGCP_Invert_Temp_P_FD5
      VeCANR_b_SGCP_Invert_Temp_P_FD5TO: nonqueued-sender-com-spec{data-element=VeCANR_b_SGCP_Invert_Temp_P_FD5TO, init-value=VeCANR_b_SGCP_Invert_Temp_P_FD5TOValue:0}, provided-interface=VeCANR_b_SGCP_Invert_Temp_P_FD5TO
      VeCANR_y_SGCPPIMACSdBusTempPFD5: nonqueued-sender-com-spec{data-element=VeCANR_y_SGCPPIMACSdBusTempPFD5, init-value=VeCANR_y_SGCPPIMACSdBusTempPFD5Value:-40}, provided-interface=VeCANR_y_SGCPPIMACSdBusTempPFD5
      VeCANR_b_SGCPPIMACSdBusTempPFD5TO: nonqueued-sender-com-spec{data-element=VeCANR_b_SGCPPIMACSdBusTempPFD5TO, init-value=VeCANR_b_SGCPPIMACSdBusTempPFD5TOValue:0}, provided-interface=VeCANR_b_SGCPPIMACSdBusTempPFD5TO
      VeCANR_T_SGCPPIMDCSdBusTempPFD5: nonqueued-sender-com-spec{data-element=VeCANR_T_SGCPPIMDCSdBusTempPFD5, init-value=VeCANR_T_SGCPPIMDCSdBusTempPFD5Value:-40}, provided-interface=VeCANR_T_SGCPPIMDCSdBusTempPFD5
      VeCANR_b_SGCPPIMDCSdBusTempPFD5TO: nonqueued-sender-com-spec{data-element=VeCANR_b_SGCPPIMDCSdBusTempPFD5TO, init-value=VeCANR_b_SGCPPIMDCSdBusTempPFD5TOValue:0}, provided-interface=VeCANR_b_SGCPPIMDCSdBusTempPFD5TO
      VeCANR_T_SGCPRotorTemp_P_FD5: nonqueued-sender-com-spec{data-element=VeCANR_T_SGCPRotorTemp_P_FD5, init-value=VeCANR_T_SGCPRotorTemp_P_FD5Value:215}, provided-interface=VeCANR_T_SGCPRotorTemp_P_FD5
      VeCANR_b_SGCPRotorTemp_P_FD5TO: nonqueued-sender-com-spec{data-element=VeCANR_b_SGCPRotorTemp_P_FD5TO, init-value=VeCANR_b_SGCPRotorTemp_P_FD5TOValue:0}, provided-interface=VeCANR_b_SGCPRotorTemp_P_FD5TO
      VeCANR_b_SGCPServLampReq_P_FD5: nonqueued-sender-com-spec{data-element=VeCANR_b_SGCPServLampReq_P_FD5, init-value=VeCANR_b_SGCPServLampReq_P_FD5Value:0}, provided-interface=VeCANR_b_SGCPServLampReq_P_FD5
      VeCANR_b_SGCPServLampReq_P_FD5TO: nonqueued-sender-com-spec{data-element=VeCANR_b_SGCPServLampReq_P_FD5TO, init-value=VeCANR_b_SGCPServLampReq_P_FD5TOValue:0}, provided-interface=VeCANR_b_SGCPServLampReq_P_FD5TO
    144 x require port:
      SendCANR_OperationalModeSts_FD5: nonqueued-receiver-com-spec{data-element=SendCANR_OperationalModeSts_FD5, init-value=SendCANR_OperationalModeSts_FD5Value:0}, required-interface=SendCANR_OperationalModeSts_FD5
      SendCANR_OperationalModeSts_FD5Vld: nonqueued-receiver-com-spec{data-element=SendCANR_OperationalModeSts_FD5Vld, init-value=SendCANR_OperationalModeSts_FD5VldValue:1}, required-interface=SendCANR_OperationalModeSts_FD5Vld
      SendCANR_Battery_Volt_1_FD5: nonqueued-receiver-com-spec{data-element=SendCANR_Battery_Volt_1_FD5, init-value=SendCANR_Battery_Volt_1_FD5Value:5}, required-interface=SendCANR_Battery_Volt_1_FD5
      SendCANR_Battery_Volt_1_FD5Vld: nonqueued-receiver-com-spec{data-element=SendCANR_Battery_Volt_1_FD5Vld, init-value=SendCANR_Battery_Volt_1_FD5VldValue:1}, required-interface=SendCANR_Battery_Volt_1_FD5Vld
      SendCANR_IgnitionOnCounter_FD5: nonqueued-receiver-com-spec{data-element=SendCANR_IgnitionOnCounter_FD5, init-value=SendCANR_IgnitionOnCounter_FD5Value:0}, required-interface=SendCANR_IgnitionOnCounter_FD5
      SendCANR_IgnitionOnCounter_FD5Vld: nonqueued-receiver-com-spec{data-element=SendCANR_IgnitionOnCounter_FD5Vld, init-value=SendCANR_IgnitionOnCounter_FD5VldValue:1}, required-interface=SendCANR_IgnitionOnCounter_FD5Vld
      SendCANR_ExtTemp_FD5: nonqueued-receiver-com-spec{data-element=SendCANR_ExtTemp_FD5, init-value=SendCANR_ExtTemp_FD5Value:-85}, required-interface=SendCANR_ExtTemp_FD5
      SendCANR_ExtTemp_FD5Vld: nonqueued-receiver-com-spec{data-element=SendCANR_ExtTemp_FD5Vld, init-value=SendCANR_ExtTemp_FD5VldValue:1}, required-interface=SendCANR_ExtTemp_FD5Vld
      SendCANR_EPBSts_FD5: nonqueued-receiver-com-spec{data-element=SendCANR_EPBSts_FD5, init-value=SendCANR_EPBSts_FD5Value:0}, required-interface=SendCANR_EPBSts_FD5
      SendCANR_EPBSts_FD5Vld: nonqueued-receiver-com-spec{data-element=SendCANR_EPBSts_FD5Vld, init-value=SendCANR_EPBSts_FD5VldValue:1}, required-interface=SendCANR_EPBSts_FD5Vld
      SendCANR_ABSFailSts_FD5: nonqueued-receiver-com-spec{data-element=SendCANR_ABSFailSts_FD5, init-value=SendCANR_ABSFailSts_FD5Value:0}, required-interface=SendCANR_ABSFailSts_FD5
      SendCANR_ABSFailSts_FD5Vld: nonqueued-receiver-com-spec{data-element=SendCANR_ABSFailSts_FD5Vld, init-value=SendCANR_ABSFailSts_FD5VldValue:1}, required-interface=SendCANR_ABSFailSts_FD5Vld
      SendCANR_ESCFailSts_FD5: nonqueued-receiver-com-spec{data-element=SendCANR_ESCFailSts_FD5, init-value=SendCANR_ESCFailSts_FD5Value:0}, required-interface=SendCANR_ESCFailSts_FD5
      SendCANR_ESCFailSts_FD5Vld: nonqueued-receiver-com-spec{data-element=SendCANR_ESCFailSts_FD5Vld, init-value=SendCANR_ESCFailSts_FD5VldValue:1}, required-interface=SendCANR_ESCFailSts_FD5Vld
      SendCANR_Eamount_FD5: nonqueued-receiver-com-spec{data-element=SendCANR_Eamount_FD5, init-value=SendCANR_Eamount_FD5Value:0}, required-interface=SendCANR_Eamount_FD5
      SendCANR_Eamount_FD5Vld: nonqueued-receiver-com-spec{data-element=SendCANR_Eamount_FD5Vld, init-value=SendCANR_Eamount_FD5VldValue:1}, required-interface=SendCANR_Eamount_FD5Vld
      SendCANR_EVMaxCurrent_FD5: nonqueued-receiver-com-spec{data-element=SendCANR_EVMaxCurrent_FD5, init-value=SendCANR_EVMaxCurrent_FD5Value:0}, required-interface=SendCANR_EVMaxCurrent_FD5
      SendCANR_EVMaxCurrent_FD5Vld: nonqueued-receiver-com-spec{data-element=SendCANR_EVMaxCurrent_FD5Vld, init-value=SendCANR_EVMaxCurrent_FD5VldValue:1}, required-interface=SendCANR_EVMaxCurrent_FD5Vld
      SendCANR_EVMaxVoltage_FD5: nonqueued-receiver-com-spec{data-element=SendCANR_EVMaxVoltage_FD5, init-value=SendCANR_EVMaxVoltage_FD5Value:0}, required-interface=SendCANR_EVMaxVoltage_FD5
      SendCANR_EVMaxVoltage_FD5Vld: nonqueued-receiver-com-spec{data-element=SendCANR_EVMaxVoltage_FD5Vld, init-value=SendCANR_EVMaxVoltage_FD5VldValue:1}, required-interface=SendCANR_EVMaxVoltage_FD5Vld
      SendCANR_EVMinCurrent_FD5: nonqueued-receiver-com-spec{data-element=SendCANR_EVMinCurrent_FD5, init-value=SendCANR_EVMinCurrent_FD5Value:0}, required-interface=SendCANR_EVMinCurrent_FD5
      SendCANR_EVMinCurrent_FD5Vld: nonqueued-receiver-com-spec{data-element=SendCANR_EVMinCurrent_FD5Vld, init-value=SendCANR_EVMinCurrent_FD5VldValue:1}, required-interface=SendCANR_EVMinCurrent_FD5Vld
      SendCANR_FOTA_Status_FD5: nonqueued-receiver-com-spec{data-element=SendCANR_FOTA_Status_FD5, init-value=SendCANR_FOTA_Status_FD5Value:0}, required-interface=SendCANR_FOTA_Status_FD5
      SendCANR_FOTA_Status_FD5Vld: nonqueued-receiver-com-spec{data-element=SendCANR_FOTA_Status_FD5Vld, init-value=SendCANR_FOTA_Status_FD5VldValue:1}, required-interface=SendCANR_FOTA_Status_FD5Vld
      SendCANR_N_PDU_7E_FD5: nonqueued-receiver-com-spec{data-element=SendCANR_N_PDU_7E_FD5, init-value=SendCANR_N_PDU_7E_FD5Value:0}, required-interface=SendCANR_N_PDU_7E_FD5
      SendCANR_N_PDU_7E_FD5Vld: nonqueued-receiver-com-spec{data-element=SendCANR_N_PDU_7E_FD5Vld, init-value=SendCANR_N_PDU_7E_FD5VldValue:1}, required-interface=SendCANR_N_PDU_7E_FD5Vld
      SendCANR_N_PDU_7F_FD5: nonqueued-receiver-com-spec{data-element=SendCANR_N_PDU_7F_FD5, init-value=SendCANR_N_PDU_7F_FD5Value:0}, required-interface=SendCANR_N_PDU_7F_FD5
      SendCANR_N_PDU_7F_FD5Vld: nonqueued-receiver-com-spec{data-element=SendCANR_N_PDU_7F_FD5Vld, init-value=SendCANR_N_PDU_7F_FD5VldValue:1}, required-interface=SendCANR_N_PDU_7F_FD5Vld
      SendCANR_PerWakeUp_Diag_FD5: nonqueued-receiver-com-spec{data-element=SendCANR_PerWakeUp_Diag_FD5, init-value=SendCANR_PerWakeUp_Diag_FD5Value:0}, required-interface=SendCANR_PerWakeUp_Diag_FD5
      SendCANR_PerWakeUp_Diag_FD5Vld: nonqueued-receiver-com-spec{data-element=SendCANR_PerWakeUp_Diag_FD5Vld, init-value=SendCANR_PerWakeUp_Diag_FD5VldValue:1}, required-interface=SendCANR_PerWakeUp_Diag_FD5Vld
      SendCANR_WU_Timer_Value_FD5: nonqueued-receiver-com-spec{data-element=SendCANR_WU_Timer_Value_FD5, init-value=SendCANR_WU_Timer_Value_FD5Value:0}, required-interface=SendCANR_WU_Timer_Value_FD5
      SendCANR_WU_Timer_Value_FD5Vld: nonqueued-receiver-com-spec{data-element=SendCANR_WU_Timer_Value_FD5Vld, init-value=SendCANR_WU_Timer_Value_FD5VldValue:1}, required-interface=SendCANR_WU_Timer_Value_FD5Vld
      SendCANR_CRC_HYBD_THRML_CMD_FD5: nonqueued-receiver-com-spec{data-element=SendCANR_CRC_HYBD_THRML_CMD_FD5, init-value=SendCANR_CRC_HYBD_THRML_CMD_FD5Value:0}, required-interface=SendCANR_CRC_HYBD_THRML_CMD_FD5
      SendCANR_CRC_HYBD_THRML_CMD_FD5Vld: nonqueued-receiver-com-spec{data-element=SendCANR_CRC_HYBD_THRML_CMD_FD5Vld, init-value=SendCANR_CRC_HYBD_THRML_CMD_FD5VldValue:1}, required-interface=SendCANR_CRC_HYBD_THRML_CMD_FD5Vld
      SendCANR_EOPA_OIL_FlwRate_FD5: nonqueued-receiver-com-spec{data-element=SendCANR_EOPA_OIL_FlwRate_FD5, init-value=SendCANR_EOPA_OIL_FlwRate_FD5Value:0}, required-interface=SendCANR_EOPA_OIL_FlwRate_FD5
      SendCANR_EOPA_OIL_FlwRate_FD5Vld: nonqueued-receiver-com-spec{data-element=SendCANR_EOPA_OIL_FlwRate_FD5Vld, init-value=SendCANR_EOPA_OIL_FlwRate_FD5VldValue:1}, required-interface=SendCANR_EOPA_OIL_FlwRate_FD5Vld
      SendCANR_EOPA_OIL_TEMP_FD5: nonqueued-receiver-com-spec{data-element=SendCANR_EOPA_OIL_TEMP_FD5, init-value=SendCANR_EOPA_OIL_TEMP_FD5Value:-50}, required-interface=SendCANR_EOPA_OIL_TEMP_FD5
      SendCANR_EOPA_OIL_TEMP_FD5Vld: nonqueued-receiver-com-spec{data-element=SendCANR_EOPA_OIL_TEMP_FD5Vld, init-value=SendCANR_EOPA_OIL_TEMP_FD5VldValue:1}, required-interface=SendCANR_EOPA_OIL_TEMP_FD5Vld
      SendCANR_EOPB_OIL_FlwRate_FD5: nonqueued-receiver-com-spec{data-element=SendCANR_EOPB_OIL_FlwRate_FD5, init-value=SendCANR_EOPB_OIL_FlwRate_FD5Value:0}, required-interface=SendCANR_EOPB_OIL_FlwRate_FD5
      SendCANR_EOPB_OIL_FlwRate_FD5Vld: nonqueued-receiver-com-spec{data-element=SendCANR_EOPB_OIL_FlwRate_FD5Vld, init-value=SendCANR_EOPB_OIL_FlwRate_FD5VldValue:1}, required-interface=SendCANR_EOPB_OIL_FlwRate_FD5Vld
      SendCANR_EOPB_OIL_TEMP_FD5: nonqueued-receiver-com-spec{data-element=SendCANR_EOPB_OIL_TEMP_FD5, init-value=SendCANR_EOPB_OIL_TEMP_FD5Value:-50}, required-interface=SendCANR_EOPB_OIL_TEMP_FD5
      SendCANR_EOPB_OIL_TEMP_FD5Vld: nonqueued-receiver-com-spec{data-element=SendCANR_EOPB_OIL_TEMP_FD5Vld, init-value=SendCANR_EOPB_OIL_TEMP_FD5VldValue:1}, required-interface=SendCANR_EOPB_OIL_TEMP_FD5Vld
      SendCANR_MC_HYBD_THRML_CMD_FD5: nonqueued-receiver-com-spec{data-element=SendCANR_MC_HYBD_THRML_CMD_FD5, init-value=SendCANR_MC_HYBD_THRML_CMD_FD5Value:0}, required-interface=SendCANR_MC_HYBD_THRML_CMD_FD5
      SendCANR_MC_HYBD_THRML_CMD_FD5Vld: nonqueued-receiver-com-spec{data-element=SendCANR_MC_HYBD_THRML_CMD_FD5Vld, init-value=SendCANR_MC_HYBD_THRML_CMD_FD5VldValue:1}, required-interface=SendCANR_MC_HYBD_THRML_CMD_FD5Vld
      SendCANR_SGCP_OIL_FlwRate_FD5: nonqueued-receiver-com-spec{data-element=SendCANR_SGCP_OIL_FlwRate_FD5, init-value=SendCANR_SGCP_OIL_FlwRate_FD5Value:0}, required-interface=SendCANR_SGCP_OIL_FlwRate_FD5
      SendCANR_SGCP_OIL_FlwRate_FD5Vld: nonqueued-receiver-com-spec{data-element=SendCANR_SGCP_OIL_FlwRate_FD5Vld, init-value=SendCANR_SGCP_OIL_FlwRate_FD5VldValue:1}, required-interface=SendCANR_SGCP_OIL_FlwRate_FD5Vld
      SendCANR_SGCP_OIL_TEMP_FD5: nonqueued-receiver-com-spec{data-element=SendCANR_SGCP_OIL_TEMP_FD5, init-value=SendCANR_SGCP_OIL_TEMP_FD5Value:-50}, required-interface=SendCANR_SGCP_OIL_TEMP_FD5
      SendCANR_SGCP_OIL_TEMP_FD5Vld: nonqueued-receiver-com-spec{data-element=SendCANR_SGCP_OIL_TEMP_FD5Vld, init-value=SendCANR_SGCP_OIL_TEMP_FD5VldValue:1}, required-interface=SendCANR_SGCP_OIL_TEMP_FD5Vld
      SendCANR_IMPACTCommand_FD5: nonqueued-receiver-com-spec{data-element=SendCANR_IMPACTCommand_FD5, init-value=SendCANR_IMPACTCommand_FD5Value:0}, required-interface=SendCANR_IMPACTCommand_FD5
      SendCANR_IMPACTCommand_FD5Vld: nonqueued-receiver-com-spec{data-element=SendCANR_IMPACTCommand_FD5Vld, init-value=SendCANR_IMPACTCommand_FD5VldValue:1}, required-interface=SendCANR_IMPACTCommand_FD5Vld
      SendCANR_IMPACTConfirm_FD5: nonqueued-receiver-com-spec{data-element=SendCANR_IMPACTConfirm_FD5, init-value=SendCANR_IMPACTConfirm_FD5Value:1}, required-interface=SendCANR_IMPACTConfirm_FD5
      SendCANR_IMPACTConfirm_FD5Vld: nonqueued-receiver-com-spec{data-element=SendCANR_IMPACTConfirm_FD5Vld, init-value=SendCANR_IMPACTConfirm_FD5VldValue:1}, required-interface=SendCANR_IMPACTConfirm_FD5Vld
      SendCANR_TotalOdometer_FD5: nonqueued-receiver-com-spec{data-element=SendCANR_TotalOdometer_FD5, init-value=SendCANR_TotalOdometer_FD5Value:0}, required-interface=SendCANR_TotalOdometer_FD5
      SendCANR_TotalOdometer_FD5Vld: nonqueued-receiver-com-spec{data-element=SendCANR_TotalOdometer_FD5Vld, init-value=SendCANR_TotalOdometer_FD5VldValue:1}, required-interface=SendCANR_TotalOdometer_FD5Vld
      SendCANR_Real_Time_Clock_FD5: nonqueued-receiver-com-spec{data-element=SendCANR_Real_Time_Clock_FD5, init-value=SendCANR_Real_Time_Clock_FD5Value:0}, required-interface=SendCANR_Real_Time_Clock_FD5
      SendCANR_Real_Time_Clock_FD5Vld: nonqueued-receiver-com-spec{data-element=SendCANR_Real_Time_Clock_FD5Vld, init-value=SendCANR_Real_Time_Clock_FD5VldValue:1}, required-interface=SendCANR_Real_Time_Clock_FD5Vld
      SendCANR_Real_Time_Validity_FD5: nonqueued-receiver-com-spec{data-element=SendCANR_Real_Time_Validity_FD5, init-value=SendCANR_Real_Time_Validity_FD5Value:0}, required-interface=SendCANR_Real_Time_Validity_FD5
      SendCANR_Real_Time_Validity_FD5Vld: nonqueued-receiver-com-spec{data-element=SendCANR_Real_Time_Validity_FD5Vld, init-value=SendCANR_Real_Time_Validity_FD5VldValue:1}, required-interface=SendCANR_Real_Time_Validity_FD5Vld
      SendCANR_V2H_HVCMS_EVMaxP_LtFD5: nonqueued-receiver-com-spec{data-element=SendCANR_V2H_HVCMS_EVMaxP_LtFD5, init-value=SendCANR_V2H_HVCMS_EVMaxP_LtFD5Value:-819.1}, required-interface=SendCANR_V2H_HVCMS_EVMaxP_LtFD5
      SendCANR_V2H_HVCMS_EVMaxP_LtFD5Vld: nonqueued-receiver-com-spec{data-element=SendCANR_V2H_HVCMS_EVMaxP_LtFD5Vld, init-value=SendCANR_V2H_HVCMS_EVMaxP_LtFD5VldValue:1}, required-interface=SendCANR_V2H_HVCMS_EVMaxP_LtFD5Vld
      SendCANR_GPS_Date_Day_FD5: nonqueued-receiver-com-spec{data-element=SendCANR_GPS_Date_Day_FD5, init-value=SendCANR_GPS_Date_Day_FD5Value:255}, required-interface=SendCANR_GPS_Date_Day_FD5
      SendCANR_GPS_Date_Day_FD5Vld: nonqueued-receiver-com-spec{data-element=SendCANR_GPS_Date_Day_FD5Vld, init-value=SendCANR_GPS_Date_Day_FD5VldValue:1}, required-interface=SendCANR_GPS_Date_Day_FD5Vld
      SendCANR_GPS_Date_Month_FD5: nonqueued-receiver-com-spec{data-element=SendCANR_GPS_Date_Month_FD5, init-value=SendCANR_GPS_Date_Month_FD5Value:255}, required-interface=SendCANR_GPS_Date_Month_FD5
      SendCANR_GPS_Date_Month_FD5Vld: nonqueued-receiver-com-spec{data-element=SendCANR_GPS_Date_Month_FD5Vld, init-value=SendCANR_GPS_Date_Month_FD5VldValue:1}, required-interface=SendCANR_GPS_Date_Month_FD5Vld
      SendCANR_GPS_Date_Year_FD5: nonqueued-receiver-com-spec{data-element=SendCANR_GPS_Date_Year_FD5, init-value=SendCANR_GPS_Date_Year_FD5Value:65535}, required-interface=SendCANR_GPS_Date_Year_FD5
      SendCANR_GPS_Date_Year_FD5Vld: nonqueued-receiver-com-spec{data-element=SendCANR_GPS_Date_Year_FD5Vld, init-value=SendCANR_GPS_Date_Year_FD5VldValue:1}, required-interface=SendCANR_GPS_Date_Year_FD5Vld
      SendCANR_GPS_UTC_Hour_FD5: nonqueued-receiver-com-spec{data-element=SendCANR_GPS_UTC_Hour_FD5, init-value=SendCANR_GPS_UTC_Hour_FD5Value:255}, required-interface=SendCANR_GPS_UTC_Hour_FD5
      SendCANR_GPS_UTC_Hour_FD5Vld: nonqueued-receiver-com-spec{data-element=SendCANR_GPS_UTC_Hour_FD5Vld, init-value=SendCANR_GPS_UTC_Hour_FD5VldValue:1}, required-interface=SendCANR_GPS_UTC_Hour_FD5Vld
      SendCANR_GPS_UTC_Minute_FD5: nonqueued-receiver-com-spec{data-element=SendCANR_GPS_UTC_Minute_FD5, init-value=SendCANR_GPS_UTC_Minute_FD5Value:255}, required-interface=SendCANR_GPS_UTC_Minute_FD5
      SendCANR_GPS_UTC_Minute_FD5Vld: nonqueued-receiver-com-spec{data-element=SendCANR_GPS_UTC_Minute_FD5Vld, init-value=SendCANR_GPS_UTC_Minute_FD5VldValue:1}, required-interface=SendCANR_GPS_UTC_Minute_FD5Vld
      SendCANR_GPS_UTC_Second_FD5: nonqueued-receiver-com-spec{data-element=SendCANR_GPS_UTC_Second_FD5, init-value=SendCANR_GPS_UTC_Second_FD5Value:655.35}, required-interface=SendCANR_GPS_UTC_Second_FD5
      SendCANR_GPS_UTC_Second_FD5Vld: nonqueued-receiver-com-spec{data-element=SendCANR_GPS_UTC_Second_FD5Vld, init-value=SendCANR_GPS_UTC_Second_FD5VldValue:1}, required-interface=SendCANR_GPS_UTC_Second_FD5Vld
      SendCANR_HVCMSBlkChrgnCmpltFD5: nonqueued-receiver-com-spec{data-element=SendCANR_HVCMSBlkChrgnCmpltFD5, init-value=SendCANR_HVCMSBlkChrgnCmpltFD5Value:0}, required-interface=SendCANR_HVCMSBlkChrgnCmpltFD5
      SendCANR_HVCMSBlkChrgnCmpltFD5Vld: nonqueued-receiver-com-spec{data-element=SendCANR_HVCMSBlkChrgnCmpltFD5Vld, init-value=SendCANR_HVCMSBlkChrgnCmpltFD5VldValue:1}, required-interface=SendCANR_HVCMSBlkChrgnCmpltFD5Vld
      SendCANR_HVCMS_ChrgnCompltFD5: nonqueued-receiver-com-spec{data-element=SendCANR_HVCMS_ChrgnCompltFD5, init-value=SendCANR_HVCMS_ChrgnCompltFD5Value:0}, required-interface=SendCANR_HVCMS_ChrgnCompltFD5
      SendCANR_HVCMS_ChrgnCompltFD5Vld: nonqueued-receiver-com-spec{data-element=SendCANR_HVCMS_ChrgnCompltFD5Vld, init-value=SendCANR_HVCMS_ChrgnCompltFD5VldValue:1}, required-interface=SendCANR_HVCMS_ChrgnCompltFD5Vld
      SendCANR_HVCMS_EVEnrgCapctFD5: nonqueued-receiver-com-spec{data-element=SendCANR_HVCMS_EVEnrgCapctFD5, init-value=SendCANR_HVCMS_EVEnrgCapctFD5Value:0}, required-interface=SendCANR_HVCMS_EVEnrgCapctFD5
      SendCANR_HVCMS_EVEnrgCapctFD5Vld: nonqueued-receiver-com-spec{data-element=SendCANR_HVCMS_EVEnrgCapctFD5Vld, init-value=SendCANR_HVCMS_EVEnrgCapctFD5VldValue:1}, required-interface=SendCANR_HVCMS_EVEnrgCapctFD5Vld
      SendCANR_HVCMS_EVEnergRquestFD5: nonqueued-receiver-com-spec{data-element=SendCANR_HVCMS_EVEnergRquestFD5, init-value=SendCANR_HVCMS_EVEnergRquestFD5Value:131071}, required-interface=SendCANR_HVCMS_EVEnergRquestFD5
      SendCANR_HVCMS_EVEnergRquestFD5Vld: nonqueued-receiver-com-spec{data-element=SendCANR_HVCMS_EVEnergRquestFD5Vld, init-value=SendCANR_HVCMS_EVEnergRquestFD5VldValue:1}, required-interface=SendCANR_HVCMS_EVEnergRquestFD5Vld
      SendCANR_HVCMS_EVErrorCode_FD5: nonqueued-receiver-com-spec{data-element=SendCANR_HVCMS_EVErrorCode_FD5, init-value=SendCANR_HVCMS_EVErrorCode_FD5Value:0}, required-interface=SendCANR_HVCMS_EVErrorCode_FD5
      SendCANR_HVCMS_EVErrorCode_FD5Vld: nonqueued-receiver-com-spec{data-element=SendCANR_HVCMS_EVErrorCode_FD5Vld, init-value=SendCANR_HVCMS_EVErrorCode_FD5VldValue:1}, required-interface=SendCANR_HVCMS_EVErrorCode_FD5Vld
      SendCANR_HVCMS_EVMax_I_LimitFD5: nonqueued-receiver-com-spec{data-element=SendCANR_HVCMS_EVMax_I_LimitFD5, init-value=SendCANR_HVCMS_EVMax_I_LimitFD5Value:-500}, required-interface=SendCANR_HVCMS_EVMax_I_LimitFD5
      SendCANR_HVCMS_EVMax_I_LimitFD5Vld: nonqueued-receiver-com-spec{data-element=SendCANR_HVCMS_EVMax_I_LimitFD5Vld, init-value=SendCANR_HVCMS_EVMax_I_LimitFD5VldValue:1}, required-interface=SendCANR_HVCMS_EVMax_I_LimitFD5Vld
      SendCANR_HVCMS_EVMax_P_LimitFD5: nonqueued-receiver-com-spec{data-element=SendCANR_HVCMS_EVMax_P_LimitFD5, init-value=SendCANR_HVCMS_EVMax_P_LimitFD5Value:0}, required-interface=SendCANR_HVCMS_EVMax_P_LimitFD5
      SendCANR_HVCMS_EVMax_P_LimitFD5Vld: nonqueued-receiver-com-spec{data-element=SendCANR_HVCMS_EVMax_P_LimitFD5Vld, init-value=SendCANR_HVCMS_EVMax_P_LimitFD5VldValue:1}, required-interface=SendCANR_HVCMS_EVMax_P_LimitFD5Vld
      SendCANR_HVCMS_EVMax_V_LimitFD5: nonqueued-receiver-com-spec{data-element=SendCANR_HVCMS_EVMax_V_LimitFD5, init-value=SendCANR_HVCMS_EVMax_V_LimitFD5Value:0}, required-interface=SendCANR_HVCMS_EVMax_V_LimitFD5
      SendCANR_HVCMS_EVMax_V_LimitFD5Vld: nonqueued-receiver-com-spec{data-element=SendCANR_HVCMS_EVMax_V_LimitFD5Vld, init-value=SendCANR_HVCMS_EVMax_V_LimitFD5VldValue:1}, required-interface=SendCANR_HVCMS_EVMax_V_LimitFD5Vld
      SendCANR_HVCMS_EVReady_FD5: nonqueued-receiver-com-spec{data-element=SendCANR_HVCMS_EVReady_FD5, init-value=SendCANR_HVCMS_EVReady_FD5Value:0}, required-interface=SendCANR_HVCMS_EVReady_FD5
      SendCANR_HVCMS_EVReady_FD5Vld: nonqueued-receiver-com-spec{data-element=SendCANR_HVCMS_EVReady_FD5Vld, init-value=SendCANR_HVCMS_EVReady_FD5VldValue:1}, required-interface=SendCANR_HVCMS_EVReady_FD5Vld
      SendCANR_HVCMS_EVRESS_SOC_FD5: nonqueued-receiver-com-spec{data-element=SendCANR_HVCMS_EVRESS_SOC_FD5, init-value=SendCANR_HVCMS_EVRESS_SOC_FD5Value:0}, required-interface=SendCANR_HVCMS_EVRESS_SOC_FD5
      SendCANR_HVCMS_EVRESS_SOC_FD5Vld: nonqueued-receiver-com-spec{data-element=SendCANR_HVCMS_EVRESS_SOC_FD5Vld, init-value=SendCANR_HVCMS_EVRESS_SOC_FD5VldValue:1}, required-interface=SendCANR_HVCMS_EVRESS_SOC_FD5Vld
      SendCANR_HVCMS_EVRESSCndtninFD5: nonqueued-receiver-com-spec{data-element=SendCANR_HVCMS_EVRESSCndtninFD5, init-value=SendCANR_HVCMS_EVRESSCndtninFD5Value:0}, required-interface=SendCANR_HVCMS_EVRESSCndtninFD5
      SendCANR_HVCMS_EVRESSCndtninFD5Vld: nonqueued-receiver-com-spec{data-element=SendCANR_HVCMS_EVRESSCndtninFD5Vld, init-value=SendCANR_HVCMS_EVRESSCndtninFD5VldValue:1}, required-interface=SendCANR_HVCMS_EVRESSCndtninFD5Vld
      SendCANR_HVCMS_EVTargetCurntFD5: nonqueued-receiver-com-spec{data-element=SendCANR_HVCMS_EVTargetCurntFD5, init-value=SendCANR_HVCMS_EVTargetCurntFD5Value:-500}, required-interface=SendCANR_HVCMS_EVTargetCurntFD5
      SendCANR_HVCMS_EVTargetCurntFD5Vld: nonqueued-receiver-com-spec{data-element=SendCANR_HVCMS_EVTargetCurntFD5Vld, init-value=SendCANR_HVCMS_EVTargetCurntFD5VldValue:1}, required-interface=SendCANR_HVCMS_EVTargetCurntFD5Vld
      SendCANR_HVCMS_EVTargetVoltFD5: nonqueued-receiver-com-spec{data-element=SendCANR_HVCMS_EVTargetVoltFD5, init-value=SendCANR_HVCMS_EVTargetVoltFD5Value:0}, required-interface=SendCANR_HVCMS_EVTargetVoltFD5
      SendCANR_HVCMS_EVTargetVoltFD5Vld: nonqueued-receiver-com-spec{data-element=SendCANR_HVCMS_EVTargetVoltFD5Vld, init-value=SendCANR_HVCMS_EVTargetVoltFD5VldValue:1}, required-interface=SendCANR_HVCMS_EVTargetVoltFD5Vld
      SendCANR_HVCMSProtocolEntry1FD5: nonqueued-receiver-com-spec{data-element=SendCANR_HVCMSProtocolEntry1FD5, init-value=SendCANR_HVCMSProtocolEntry1FD5Value:0}, required-interface=SendCANR_HVCMSProtocolEntry1FD5
      SendCANR_HVCMSProtocolEntry1FD5Vld: nonqueued-receiver-com-spec{data-element=SendCANR_HVCMSProtocolEntry1FD5Vld, init-value=SendCANR_HVCMSProtocolEntry1FD5VldValue:1}, required-interface=SendCANR_HVCMSProtocolEntry1FD5Vld
      SendCANR_HVCMSProtocolEntry2FD5: nonqueued-receiver-com-spec{data-element=SendCANR_HVCMSProtocolEntry2FD5, init-value=SendCANR_HVCMSProtocolEntry2FD5Value:0}, required-interface=SendCANR_HVCMSProtocolEntry2FD5
      SendCANR_HVCMSProtocolEntry2FD5Vld: nonqueued-receiver-com-spec{data-element=SendCANR_HVCMSProtocolEntry2FD5Vld, init-value=SendCANR_HVCMSProtocolEntry2FD5VldValue:1}, required-interface=SendCANR_HVCMSProtocolEntry2FD5Vld
      SendCANR_HVCMSProtocolEntry3FD5: nonqueued-receiver-com-spec{data-element=SendCANR_HVCMSProtocolEntry3FD5, init-value=SendCANR_HVCMSProtocolEntry3FD5Value:0}, required-interface=SendCANR_HVCMSProtocolEntry3FD5
      SendCANR_HVCMSProtocolEntry3FD5Vld: nonqueued-receiver-com-spec{data-element=SendCANR_HVCMSProtocolEntry3FD5Vld, init-value=SendCANR_HVCMSProtocolEntry3FD5VldValue:1}, required-interface=SendCANR_HVCMSProtocolEntry3FD5Vld
      SendCANR_HVCMSReadyToChgStatFD5: nonqueued-receiver-com-spec{data-element=SendCANR_HVCMSReadyToChgStatFD5, init-value=SendCANR_HVCMSReadyToChgStatFD5Value:0}, required-interface=SendCANR_HVCMSReadyToChgStatFD5
      SendCANR_HVCMSReadyToChgStatFD5Vld: nonqueued-receiver-com-spec{data-element=SendCANR_HVCMSReadyToChgStatFD5Vld, init-value=SendCANR_HVCMSReadyToChgStatFD5VldValue:1}, required-interface=SendCANR_HVCMSReadyToChgStatFD5Vld
      SendCANR_HVCMSRemTimToBlkSOCFD5: nonqueued-receiver-com-spec{data-element=SendCANR_HVCMSRemTimToBlkSOCFD5, init-value=SendCANR_HVCMSRemTimToBlkSOCFD5Value:0}, required-interface=SendCANR_HVCMSRemTimToBlkSOCFD5
      SendCANR_HVCMSRemTimToBlkSOCFD5Vld: nonqueued-receiver-com-spec{data-element=SendCANR_HVCMSRemTimToBlkSOCFD5Vld, init-value=SendCANR_HVCMSRemTimToBlkSOCFD5VldValue:1}, required-interface=SendCANR_HVCMSRemTimToBlkSOCFD5Vld
      SendCANR_HVCMSRemTimToFulSOCFD5: nonqueued-receiver-com-spec{data-element=SendCANR_HVCMSRemTimToFulSOCFD5, init-value=SendCANR_HVCMSRemTimToFulSOCFD5Value:0}, required-interface=SendCANR_HVCMSRemTimToFulSOCFD5
      SendCANR_HVCMSRemTimToFulSOCFD5Vld: nonqueued-receiver-com-spec{data-element=SendCANR_HVCMSRemTimToFulSOCFD5Vld, init-value=SendCANR_HVCMSRemTimToFulSOCFD5VldValue:1}, required-interface=SendCANR_HVCMSRemTimToFulSOCFD5Vld
      SendCANR_HVCMSSlfEnrgTrnfTypFD5: nonqueued-receiver-com-spec{data-element=SendCANR_HVCMSSlfEnrgTrnfTypFD5, init-value=SendCANR_HVCMSSlfEnrgTrnfTypFD5Value:0}, required-interface=SendCANR_HVCMSSlfEnrgTrnfTypFD5
      SendCANR_HVCMSSlfEnrgTrnfTypFD5Vld: nonqueued-receiver-com-spec{data-element=SendCANR_HVCMSSlfEnrgTrnfTypFD5Vld, init-value=SendCANR_HVCMSSlfEnrgTrnfTypFD5VldValue:1}, required-interface=SendCANR_HVCMSSlfEnrgTrnfTypFD5Vld
      SendCANR_HVCMS_SeldPymntOptnFD5: nonqueued-receiver-com-spec{data-element=SendCANR_HVCMS_SeldPymntOptnFD5, init-value=SendCANR_HVCMS_SeldPymntOptnFD5Value:0}, required-interface=SendCANR_HVCMS_SeldPymntOptnFD5
      SendCANR_HVCMS_SeldPymntOptnFD5Vld: nonqueued-receiver-com-spec{data-element=SendCANR_HVCMS_SeldPymntOptnFD5Vld, init-value=SendCANR_HVCMS_SeldPymntOptnFD5VldValue:1}, required-interface=SendCANR_HVCMS_SeldPymntOptnFD5Vld
      SendCANR_HVCMSSelectedServIdFD5: nonqueued-receiver-com-spec{data-element=SendCANR_HVCMSSelectedServIdFD5, init-value=SendCANR_HVCMSSelectedServIdFD5Value:0}, required-interface=SendCANR_HVCMSSelectedServIdFD5
      SendCANR_HVCMSSelectedServIdFD5Vld: nonqueued-receiver-com-spec{data-element=SendCANR_HVCMSSelectedServIdFD5Vld, init-value=SendCANR_HVCMSSelectedServIdFD5VldValue:1}, required-interface=SendCANR_HVCMSSelectedServIdFD5Vld
      SendCANR_HVCMSServiceCatgoryFD5: nonqueued-receiver-com-spec{data-element=SendCANR_HVCMSServiceCatgoryFD5, init-value=SendCANR_HVCMSServiceCatgoryFD5Value:0}, required-interface=SendCANR_HVCMSServiceCatgoryFD5
      SendCANR_HVCMSServiceCatgoryFD5Vld: nonqueued-receiver-com-spec{data-element=SendCANR_HVCMSServiceCatgoryFD5Vld, init-value=SendCANR_HVCMSServiceCatgoryFD5VldValue:1}, required-interface=SendCANR_HVCMSServiceCatgoryFD5Vld
      SendCANR_HVCMS_ServiceScope_FD5: nonqueued-receiver-com-spec{data-element=SendCANR_HVCMS_ServiceScope_FD5, init-value=SendCANR_HVCMS_ServiceScope_FD5Value:0}, required-interface=SendCANR_HVCMS_ServiceScope_FD5
      SendCANR_HVCMS_ServiceScope_FD5Vld: nonqueued-receiver-com-spec{data-element=SendCANR_HVCMS_ServiceScope_FD5Vld, init-value=SendCANR_HVCMS_ServiceScope_FD5VldValue:1}, required-interface=SendCANR_HVCMS_ServiceScope_FD5Vld
      SendCANR_OBCMOutVoltSyncTgtFD15: nonqueued-receiver-com-spec{data-element=SendCANR_OBCMOutVoltSyncTgtFD15, init-value=SendCANR_OBCMOutVoltSyncTgtFD15Value:0}, required-interface=SendCANR_OBCMOutVoltSyncTgtFD15
      SendCANR_OBCMOutVoltSyncTgtFD15Vld: nonqueued-receiver-com-spec{data-element=SendCANR_OBCMOutVoltSyncTgtFD15Vld, init-value=SendCANR_OBCMOutVoltSyncTgtFD15VldValue:1}, required-interface=SendCANR_OBCMOutVoltSyncTgtFD15Vld
      SendCANR_VDCM_BattBulkSOC_FD5: nonqueued-receiver-com-spec{data-element=SendCANR_VDCM_BattBulkSOC_FD5, init-value=SendCANR_VDCM_BattBulkSOC_FD5Value:0}, required-interface=SendCANR_VDCM_BattBulkSOC_FD5
      SendCANR_VDCM_BattBulkSOC_FD5Vld: nonqueued-receiver-com-spec{data-element=SendCANR_VDCM_BattBulkSOC_FD5Vld, init-value=SendCANR_VDCM_BattBulkSOC_FD5VldValue:1}, required-interface=SendCANR_VDCM_BattBulkSOC_FD5Vld
      SendCANR_VDCM_CntrctAuthIDFD5: nonqueued-receiver-com-spec{data-element=SendCANR_VDCM_CntrctAuthIDFD5, init-value=SendCANR_VDCM_CntrctAuthIDFD5Value:0}, required-interface=SendCANR_VDCM_CntrctAuthIDFD5
      SendCANR_VDCM_CntrctAuthIDFD5Vld: nonqueued-receiver-com-spec{data-element=SendCANR_VDCM_CntrctAuthIDFD5Vld, init-value=SendCANR_VDCM_CntrctAuthIDFD5VldValue:1}, required-interface=SendCANR_VDCM_CntrctAuthIDFD5Vld
      SendCANR_VDCM_GenChallenge_FD5: nonqueued-receiver-com-spec{data-element=SendCANR_VDCM_GenChallenge_FD5, init-value=SendCANR_VDCM_GenChallenge_FD5Value:0}, required-interface=SendCANR_VDCM_GenChallenge_FD5
      SendCANR_VDCM_GenChallenge_FD5Vld: nonqueued-receiver-com-spec{data-element=SendCANR_VDCM_GenChallenge_FD5Vld, init-value=SendCANR_VDCM_GenChallenge_FD5VldValue:1}, required-interface=SendCANR_VDCM_GenChallenge_FD5Vld
      SendCANR_VDCMOBCDchaCurrLimFD5: nonqueued-receiver-com-spec{data-element=SendCANR_VDCMOBCDchaCurrLimFD5, init-value=SendCANR_VDCMOBCDchaCurrLimFD5Value:-733.5}, required-interface=SendCANR_VDCMOBCDchaCurrLimFD5
      SendCANR_VDCMOBCDchaCurrLimFD5Vld: nonqueued-receiver-com-spec{data-element=SendCANR_VDCMOBCDchaCurrLimFD5Vld, init-value=SendCANR_VDCMOBCDchaCurrLimFD5VldValue:1}, required-interface=SendCANR_VDCMOBCDchaCurrLimFD5Vld
      SendCANR_VDCMTypeCNegotnStsFD5: nonqueued-receiver-com-spec{data-element=SendCANR_VDCMTypeCNegotnStsFD5, init-value=SendCANR_VDCMTypeCNegotnStsFD5Value:0}, required-interface=SendCANR_VDCMTypeCNegotnStsFD5
      SendCANR_VDCMTypeCNegotnStsFD5Vld: nonqueued-receiver-com-spec{data-element=SendCANR_VDCMTypeCNegotnStsFD5Vld, init-value=SendCANR_VDCMTypeCNegotnStsFD5VldValue:1}, required-interface=SendCANR_VDCMTypeCNegotnStsFD5Vld
      SendCANR_ClrLgsDiagInfo_FD5: nonqueued-receiver-com-spec{data-element=SendCANR_ClrLgsDiagInfo_FD5, init-value=SendCANR_ClrLgsDiagInfo_FD5Value:0}, required-interface=SendCANR_ClrLgsDiagInfo_FD5
      SendCANR_ClrLgsDiagInfo_FD5Vld: nonqueued-receiver-com-spec{data-element=SendCANR_ClrLgsDiagInfo_FD5Vld, init-value=SendCANR_ClrLgsDiagInfo_FD5VldValue:1}, required-interface=SendCANR_ClrLgsDiagInfo_FD5Vld
      SendCANR_T4_Sensor_Temp_FD5: nonqueued-receiver-com-spec{data-element=SendCANR_T4_Sensor_Temp_FD5, init-value=SendCANR_T4_Sensor_Temp_FD5Value:-40}, required-interface=SendCANR_T4_Sensor_Temp_FD5
      SendCANR_T4_Sensor_Temp_FD5Vld: nonqueued-receiver-com-spec{data-element=SendCANR_T4_Sensor_Temp_FD5Vld, init-value=SendCANR_T4_Sensor_Temp_FD5VldValue:1}, required-interface=SendCANR_T4_Sensor_Temp_FD5Vld
      SendCANR_T7_CoolantTmpVldty_FD5: nonqueued-receiver-com-spec{data-element=SendCANR_T7_CoolantTmpVldty_FD5, init-value=SendCANR_T7_CoolantTmpVldty_FD5Value:0}, required-interface=SendCANR_T7_CoolantTmpVldty_FD5
      SendCANR_T7_CoolantTmpVldty_FD5Vld: nonqueued-receiver-com-spec{data-element=SendCANR_T7_CoolantTmpVldty_FD5Vld, init-value=SendCANR_T7_CoolantTmpVldty_FD5VldValue:1}, required-interface=SendCANR_T7_CoolantTmpVldty_FD5Vld
      SendCANR_T7_Sensor_Temp_FD5: nonqueued-receiver-com-spec{data-element=SendCANR_T7_Sensor_Temp_FD5, init-value=SendCANR_T7_Sensor_Temp_FD5Value:-40}, required-interface=SendCANR_T7_Sensor_Temp_FD5
      SendCANR_T7_Sensor_Temp_FD5Vld: nonqueued-receiver-com-spec{data-element=SendCANR_T7_Sensor_Temp_FD5Vld, init-value=SendCANR_T7_Sensor_Temp_FD5VldValue:1}, required-interface=SendCANR_T7_Sensor_Temp_FD5Vld
      SendCANR_VIN_DATA_FD5: nonqueued-receiver-com-spec{data-element=SendCANR_VIN_DATA_FD5, init-value=SendCANR_VIN_DATA_FD5Value:0}, required-interface=SendCANR_VIN_DATA_FD5
      SendCANR_VIN_DATA_FD5Vld: nonqueued-receiver-com-spec{data-element=SendCANR_VIN_DATA_FD5Vld, init-value=SendCANR_VIN_DATA_FD5VldValue:1}, required-interface=SendCANR_VIN_DATA_FD5Vld
      SendCANR_VIN_MSG_FD5: nonqueued-receiver-com-spec{data-element=SendCANR_VIN_MSG_FD5, init-value=SendCANR_VIN_MSG_FD5Value:3}, required-interface=SendCANR_VIN_MSG_FD5
      SendCANR_VIN_MSG_FD5Vld: nonqueued-receiver-com-spec{data-element=SendCANR_VIN_MSG_FD5Vld, init-value=SendCANR_VIN_MSG_FD5VldValue:1}, required-interface=SendCANR_VIN_MSG_FD5Vld
    behavior IBApplCanComAb_FD5: data-type-mapping=ADTtoIDTMapping, handle-termination-and-restart=NO-SUPPORT
      init event IninEve: start-on-event=ApplCanComAb_FD5Inin
      data received event DRECOMRX_ImpactHardwire_BATTERY_HV_FD5: start-on-event=COMRX_ImpactHardwire_BATTERY_HV_FD5_Received, data=CanCom_FD5RxSignalsSR.COMRX_ImpactHardwire_BATTERY_HV_FD5
      data receive error event DEECOMRX_ImpactHardwire_BATTERY_HV_FD5: start-on-event=COMRX_ImpactHardwire_BATTERY_HV_FD5_Error, data=CanCom_FD5RxSignalsSR.COMRX_ImpactHardwire_BATTERY_HV_FD5
      data received event DRECOMRX_ImpactHardwireV_BATTERY_HV_FD5: start-on-event=COMRX_ImpactHardwireV_BATTERY_HV_FD5_Received, data=CanCom_FD5RxSignalsSR.COMRX_ImpactHardwireV_BATTERY_HV_FD5
      data receive error event DEECOMRX_ImpactHardwireV_BATTERY_HV_FD5: start-on-event=COMRX_ImpactHardwireV_BATTERY_HV_FD5_Error, data=CanCom_FD5RxSignalsSR.COMRX_ImpactHardwireV_BATTERY_HV_FD5
      data received event DRECOMRX_BMS_HV_High_Temp_Thrsh_BATTERY_HV2_FD5: start-on-event=COMRX_BMS_HV_High_Temp_Thrsh_BATTERY_HV2_FD5_Received, data=CanCom_FD5RxSignalsSR.COMRX_BMS_HV_High_Temp_Thrsh_BATTERY_HV2_FD5
      data receive error event DEECOMRX_BMS_HV_High_Temp_Thrsh_BATTERY_HV2_FD5: start-on-event=COMRX_BMS_HV_High_Temp_Thrsh_BATTERY_HV2_FD5_Error, data=CanCom_FD5RxSignalsSR.COMRX_BMS_HV_High_Temp_Thrsh_BATTERY_HV2_FD5
      data received event DRECOMRX_BMS_HV_Low_Temp_Thrsh_BATTERY_HV2_FD5: start-on-event=COMRX_BMS_HV_Low_Temp_Thrsh_BATTERY_HV2_FD5_Received, data=CanCom_FD5RxSignalsSR.COMRX_BMS_HV_Low_Temp_Thrsh_BATTERY_HV2_FD5
      data receive error event DEECOMRX_BMS_HV_Low_Temp_Thrsh_BATTERY_HV2_FD5: start-on-event=COMRX_BMS_HV_Low_Temp_Thrsh_BATTERY_HV2_FD5_Error, data=CanCom_FD5RxSignalsSR.COMRX_BMS_HV_Low_Temp_Thrsh_BATTERY_HV2_FD5
      data received event DRECOMRX_BMS_HV_SOC_AccuracySts_BATTERY_HV2_FD5: start-on-event=COMRX_BMS_HV_SOC_AccuracySts_BATTERY_HV2_FD5_Received, data=CanCom_FD5RxSignalsSR.COMRX_BMS_HV_SOC_AccuracySts_BATTERY_HV2_FD5
      data receive error event DEECOMRX_BMS_HV_SOC_AccuracySts_BATTERY_HV2_FD5: start-on-event=COMRX_BMS_HV_SOC_AccuracySts_BATTERY_HV2_FD5_Error, data=CanCom_FD5RxSignalsSR.COMRX_BMS_HV_SOC_AccuracySts_BATTERY_HV2_FD5
      data received event DRECOMRX_BMS_HV_SOC_Max_BATTERY_HV2_FD5: start-on-event=COMRX_BMS_HV_SOC_Max_BATTERY_HV2_FD5_Received, data=CanCom_FD5RxSignalsSR.COMRX_BMS_HV_SOC_Max_BATTERY_HV2_FD5
      data receive error event DEECOMRX_BMS_HV_SOC_Max_BATTERY_HV2_FD5: start-on-event=COMRX_BMS_HV_SOC_Max_BATTERY_HV2_FD5_Error, data=CanCom_FD5RxSignalsSR.COMRX_BMS_HV_SOC_Max_BATTERY_HV2_FD5
      data received event DRECOMRX_BMS_HV_SOC_Min_BATTERY_HV2_FD5: start-on-event=COMRX_BMS_HV_SOC_Min_BATTERY_HV2_FD5_Received, data=CanCom_FD5RxSignalsSR.COMRX_BMS_HV_SOC_Min_BATTERY_HV2_FD5
      data receive error event DEECOMRX_BMS_HV_SOC_Min_BATTERY_HV2_FD5: start-on-event=COMRX_BMS_HV_SOC_Min_BATTERY_HV2_FD5_Error, data=CanCom_FD5RxSignalsSR.COMRX_BMS_HV_SOC_Min_BATTERY_HV2_FD5
      data received event DRECOMRX_HEV_OnRq_BPCM_BATTERY_HV2_FD5: start-on-event=COMRX_HEV_OnRq_BPCM_BATTERY_HV2_FD5_Received, data=CanCom_FD5RxSignalsSR.COMRX_HEV_OnRq_BPCM_BATTERY_HV2_FD5
      data receive error event DEECOMRX_HEV_OnRq_BPCM_BATTERY_HV2_FD5: start-on-event=COMRX_HEV_OnRq_BPCM_BATTERY_HV2_FD5_Error, data=CanCom_FD5RxSignalsSR.COMRX_HEV_OnRq_BPCM_BATTERY_HV2_FD5
      data received event DRECOMRX_HVBatCell_Voltage_High_Thrsh_BATTERY_HV2_FD5: start-on-event=COMRX_HVBatCell_Voltage_High_Thrsh_BATTERY_HV2_FD5_Received, data=CanCom_FD5RxSignalsSR.COMRX_HVBatCell_Voltage_High_Thrsh_BATTERY_HV2_FD5
      data receive error event DEECOMRX_HVBatCell_Voltage_High_Thrsh_BATTERY_HV2_FD5: start-on-event=COMRX_HVBatCell_Voltage_High_Thrsh_BATTERY_HV2_FD5_Error, data=CanCom_FD5RxSignalsSR.COMRX_HVBatCell_Voltage_High_Thrsh_BATTERY_HV2_FD5
      data received event DRECOMRX_HVBatCell_Voltage_Low_Thrsh_BATTERY_HV2_FD5: start-on-event=COMRX_HVBatCell_Voltage_Low_Thrsh_BATTERY_HV2_FD5_Received, data=CanCom_FD5RxSignalsSR.COMRX_HVBatCell_Voltage_Low_Thrsh_BATTERY_HV2_FD5
      data receive error event DEECOMRX_HVBatCell_Voltage_Low_Thrsh_BATTERY_HV2_FD5: start-on-event=COMRX_HVBatCell_Voltage_Low_Thrsh_BATTERY_HV2_FD5_Error, data=CanCom_FD5RxSignalsSR.COMRX_HVBatCell_Voltage_Low_Thrsh_BATTERY_HV2_FD5
      data received event DRECOMRX_OBC_Temp1_DUALCHARGER_THERMAL_FD5: start-on-event=COMRX_OBC_Temp1_DUALCHARGER_THERMAL_FD5_Received, data=CanCom_FD5RxSignalsSR.COMRX_OBC_Temp1_DUALCHARGER_THERMAL_FD5
      data receive error event DEECOMRX_OBC_Temp1_DUALCHARGER_THERMAL_FD5: start-on-event=COMRX_OBC_Temp1_DUALCHARGER_THERMAL_FD5_Error, data=CanCom_FD5RxSignalsSR.COMRX_OBC_Temp1_DUALCHARGER_THERMAL_FD5
      data received event DRECOMRX_OBC_Temp2_DUALCHARGER_THERMAL_FD5: start-on-event=COMRX_OBC_Temp2_DUALCHARGER_THERMAL_FD5_Received, data=CanCom_FD5RxSignalsSR.COMRX_OBC_Temp2_DUALCHARGER_THERMAL_FD5
      data receive error event DEECOMRX_OBC_Temp2_DUALCHARGER_THERMAL_FD5: start-on-event=COMRX_OBC_Temp2_DUALCHARGER_THERMAL_FD5_Error, data=CanCom_FD5RxSignalsSR.COMRX_OBC_Temp2_DUALCHARGER_THERMAL_FD5
      data received event DRECOMRX_OBC_Temp3_DUALCHARGER_THERMAL_FD5: start-on-event=COMRX_OBC_Temp3_DUALCHARGER_THERMAL_FD5_Received, data=CanCom_FD5RxSignalsSR.COMRX_OBC_Temp3_DUALCHARGER_THERMAL_FD5
      data receive error event DEECOMRX_OBC_Temp3_DUALCHARGER_THERMAL_FD5: start-on-event=COMRX_OBC_Temp3_DUALCHARGER_THERMAL_FD5_Error, data=CanCom_FD5RxSignalsSR.COMRX_OBC_Temp3_DUALCHARGER_THERMAL_FD5
      data received event DRECOMRX_OBC_Temp4_DUALCHARGER_THERMAL_FD5: start-on-event=COMRX_OBC_Temp4_DUALCHARGER_THERMAL_FD5_Received, data=CanCom_FD5RxSignalsSR.COMRX_OBC_Temp4_DUALCHARGER_THERMAL_FD5
      data receive error event DEECOMRX_OBC_Temp4_DUALCHARGER_THERMAL_FD5: start-on-event=COMRX_OBC_Temp4_DUALCHARGER_THERMAL_FD5_Error, data=CanCom_FD5RxSignalsSR.COMRX_OBC_Temp4_DUALCHARGER_THERMAL_FD5
      data received event DRECOMRX_N_PDU_7B_GLIWA_MCPA_TX_FD5: start-on-event=COMRX_N_PDU_7B_GLIWA_MCPA_TX_FD5_Received, data=CanCom_FD5RxSignalsSR.COMRX_N_PDU_7B_GLIWA_MCPA_TX_FD5
      data receive error event DEECOMRX_N_PDU_7B_GLIWA_MCPA_TX_FD5: start-on-event=COMRX_N_PDU_7B_GLIWA_MCPA_TX_FD5_Error, data=CanCom_FD5RxSignalsSR.COMRX_N_PDU_7B_GLIWA_MCPA_TX_FD5
      data received event DRECOMRX_N_PDU_7C_GLIWA_MCPB_TX_FD5: start-on-event=COMRX_N_PDU_7C_GLIWA_MCPB_TX_FD5_Received, data=CanCom_FD5RxSignalsSR.COMRX_N_PDU_7C_GLIWA_MCPB_TX_FD5
      data receive error event DEECOMRX_N_PDU_7C_GLIWA_MCPB_TX_FD5: start-on-event=COMRX_N_PDU_7C_GLIWA_MCPB_TX_FD5_Error, data=CanCom_FD5RxSignalsSR.COMRX_N_PDU_7C_GLIWA_MCPB_TX_FD5
      data received event DRECOMRX_HVBatSleepTime_HVBATTERY_THERMAL_FD5: start-on-event=COMRX_HVBatSleepTime_HVBATTERY_THERMAL_FD5_Received, data=CanCom_FD5RxSignalsSR.COMRX_HVBatSleepTime_HVBATTERY_THERMAL_FD5
      data receive error event DEECOMRX_HVBatSleepTime_HVBATTERY_THERMAL_FD5: start-on-event=COMRX_HVBatSleepTime_HVBATTERY_THERMAL_FD5_Error, data=CanCom_FD5RxSignalsSR.COMRX_HVBatSleepTime_HVBATTERY_THERMAL_FD5
      data received event DRECOMRX_ACplug_PwrMax_HV_CHARGER2_FD5: start-on-event=COMRX_ACplug_PwrMax_HV_CHARGER2_FD5_Received, data=CanCom_FD5RxSignalsSR.COMRX_ACplug_PwrMax_HV_CHARGER2_FD5
      data receive error event DEECOMRX_ACplug_PwrMax_HV_CHARGER2_FD5: start-on-event=COMRX_ACplug_PwrMax_HV_CHARGER2_FD5_Error, data=CanCom_FD5RxSignalsSR.COMRX_ACplug_PwrMax_HV_CHARGER2_FD5
      data received event DRECOMRX_Charging_WHr_HV_CHARGER2_FD5: start-on-event=COMRX_Charging_WHr_HV_CHARGER2_FD5_Received, data=CanCom_FD5RxSignalsSR.COMRX_Charging_WHr_HV_CHARGER2_FD5
      data receive error event DEECOMRX_Charging_WHr_HV_CHARGER2_FD5: start-on-event=COMRX_Charging_WHr_HV_CHARGER2_FD5_Error, data=CanCom_FD5RxSignalsSR.COMRX_Charging_WHr_HV_CHARGER2_FD5
      data received event DRECOMRX_ChrgFailSts_HV_CHARGER2_FD5: start-on-event=COMRX_ChrgFailSts_HV_CHARGER2_FD5_Received, data=CanCom_FD5RxSignalsSR.COMRX_ChrgFailSts_HV_CHARGER2_FD5
      data receive error event DEECOMRX_ChrgFailSts_HV_CHARGER2_FD5: start-on-event=COMRX_ChrgFailSts_HV_CHARGER2_FD5_Error, data=CanCom_FD5RxSignalsSR.COMRX_ChrgFailSts_HV_CHARGER2_FD5
      data received event DRECOMRX_OBC_CaptureEnvironmentData_HV_CHARGER2_FD5: start-on-event=COMRX_OBC_CaptureEnvironmentData_HV_CHARGER2_FD5_Received, data=CanCom_FD5RxSignalsSR.COMRX_OBC_CaptureEnvironmentData_HV_CHARGER2_FD5
      data receive error event DEECOMRX_OBC_CaptureEnvironmentData_HV_CHARGER2_FD5: start-on-event=COMRX_OBC_CaptureEnvironmentData_HV_CHARGER2_FD5_Error, data=CanCom_FD5RxSignalsSR.COMRX_OBC_CaptureEnvironmentData_HV_CHARGER2_FD5
      data received event DRECOMRX_OBC_ChargeFailure_HV_CHARGER2_FD5: start-on-event=COMRX_OBC_ChargeFailure_HV_CHARGER2_FD5_Received, data=CanCom_FD5RxSignalsSR.COMRX_OBC_ChargeFailure_HV_CHARGER2_FD5
      data receive error event DEECOMRX_OBC_ChargeFailure_HV_CHARGER2_FD5: start-on-event=COMRX_OBC_ChargeFailure_HV_CHARGER2_FD5_Error, data=CanCom_FD5RxSignalsSR.COMRX_OBC_ChargeFailure_HV_CHARGER2_FD5
      data received event DRECOMRX_OBC_ChargeTimeMin_HV_CHARGER2_FD5: start-on-event=COMRX_OBC_ChargeTimeMin_HV_CHARGER2_FD5_Received, data=CanCom_FD5RxSignalsSR.COMRX_OBC_ChargeTimeMin_HV_CHARGER2_FD5
      data receive error event DEECOMRX_OBC_ChargeTimeMin_HV_CHARGER2_FD5: start-on-event=COMRX_OBC_ChargeTimeMin_HV_CHARGER2_FD5_Error, data=CanCom_FD5RxSignalsSR.COMRX_OBC_ChargeTimeMin_HV_CHARGER2_FD5
      data received event DRECOMRX_OBC_ChargeTimeSec_HV_CHARGER2_FD5: start-on-event=COMRX_OBC_ChargeTimeSec_HV_CHARGER2_FD5_Received, data=CanCom_FD5RxSignalsSR.COMRX_OBC_ChargeTimeSec_HV_CHARGER2_FD5
      data receive error event DEECOMRX_OBC_ChargeTimeSec_HV_CHARGER2_FD5: start-on-event=COMRX_OBC_ChargeTimeSec_HV_CHARGER2_FD5_Error, data=CanCom_FD5RxSignalsSR.COMRX_OBC_ChargeTimeSec_HV_CHARGER2_FD5
      data received event DRECOMRX_OBC_ChargingFaultSts_HV_CHARGER2_FD5: start-on-event=COMRX_OBC_ChargingFaultSts_HV_CHARGER2_FD5_Received, data=CanCom_FD5RxSignalsSR.COMRX_OBC_ChargingFaultSts_HV_CHARGER2_FD5
      data receive error event DEECOMRX_OBC_ChargingFaultSts_HV_CHARGER2_FD5: start-on-event=COMRX_OBC_ChargingFaultSts_HV_CHARGER2_FD5_Error, data=CanCom_FD5RxSignalsSR.COMRX_OBC_ChargingFaultSts_HV_CHARGER2_FD5
      data received event DRECOMRX_OBC_CurrentFailureSts_HV_CHARGER2_FD5: start-on-event=COMRX_OBC_CurrentFailureSts_HV_CHARGER2_FD5_Received, data=CanCom_FD5RxSignalsSR.COMRX_OBC_CurrentFailureSts_HV_CHARGER2_FD5
      data receive error event DEECOMRX_OBC_CurrentFailureSts_HV_CHARGER2_FD5: start-on-event=COMRX_OBC_CurrentFailureSts_HV_CHARGER2_FD5_Error, data=CanCom_FD5RxSignalsSR.COMRX_OBC_CurrentFailureSts_HV_CHARGER2_FD5
      data received event DRECOMRX_OBC_EVServiceLampFlash_HV_CHARGER2_FD5: start-on-event=COMRX_OBC_EVServiceLampFlash_HV_CHARGER2_FD5_Received, data=CanCom_FD5RxSignalsSR.COMRX_OBC_EVServiceLampFlash_HV_CHARGER2_FD5
      data receive error event DEECOMRX_OBC_EVServiceLampFlash_HV_CHARGER2_FD5: start-on-event=COMRX_OBC_EVServiceLampFlash_HV_CHARGER2_FD5_Error, data=CanCom_FD5RxSignalsSR.COMRX_OBC_EVServiceLampFlash_HV_CHARGER2_FD5
      data received event DRECOMRX_OBC_EVServiceLampOn_HV_CHARGER2_FD5: start-on-event=COMRX_OBC_EVServiceLampOn_HV_CHARGER2_FD5_Received, data=CanCom_FD5RxSignalsSR.COMRX_OBC_EVServiceLampOn_HV_CHARGER2_FD5
      data receive error event DEECOMRX_OBC_EVServiceLampOn_HV_CHARGER2_FD5: start-on-event=COMRX_OBC_EVServiceLampOn_HV_CHARGER2_FD5_Error, data=CanCom_FD5RxSignalsSR.COMRX_OBC_EVServiceLampOn_HV_CHARGER2_FD5
      data received event DRECOMRX_OBC_FaultReason_HV_CHARGER2_FD5: start-on-event=COMRX_OBC_FaultReason_HV_CHARGER2_FD5_Received, data=CanCom_FD5RxSignalsSR.COMRX_OBC_FaultReason_HV_CHARGER2_FD5
      data receive error event DEECOMRX_OBC_FaultReason_HV_CHARGER2_FD5: start-on-event=COMRX_OBC_FaultReason_HV_CHARGER2_FD5_Error, data=CanCom_FD5RxSignalsSR.COMRX_OBC_FaultReason_HV_CHARGER2_FD5
      data received event DRECOMRX_OBC_GenericFailSts_HV_CHARGER2_FD5: start-on-event=COMRX_OBC_GenericFailSts_HV_CHARGER2_FD5_Received, data=CanCom_FD5RxSignalsSR.COMRX_OBC_GenericFailSts_HV_CHARGER2_FD5
      data receive error event DEECOMRX_OBC_GenericFailSts_HV_CHARGER2_FD5: start-on-event=COMRX_OBC_GenericFailSts_HV_CHARGER2_FD5_Error, data=CanCom_FD5RxSignalsSR.COMRX_OBC_GenericFailSts_HV_CHARGER2_FD5
      data received event DRECOMRX_OBC_IdleTimeMin_HV_CHARGER2_FD5: start-on-event=COMRX_OBC_IdleTimeMin_HV_CHARGER2_FD5_Received, data=CanCom_FD5RxSignalsSR.COMRX_OBC_IdleTimeMin_HV_CHARGER2_FD5
      data receive error event DEECOMRX_OBC_IdleTimeMin_HV_CHARGER2_FD5: start-on-event=COMRX_OBC_IdleTimeMin_HV_CHARGER2_FD5_Error, data=CanCom_FD5RxSignalsSR.COMRX_OBC_IdleTimeMin_HV_CHARGER2_FD5
      data received event DRECOMRX_OBC_IdleTimeSec_HV_CHARGER2_FD5: start-on-event=COMRX_OBC_IdleTimeSec_HV_CHARGER2_FD5_Received, data=CanCom_FD5RxSignalsSR.COMRX_OBC_IdleTimeSec_HV_CHARGER2_FD5
      data receive error event DEECOMRX_OBC_IdleTimeSec_HV_CHARGER2_FD5: start-on-event=COMRX_OBC_IdleTimeSec_HV_CHARGER2_FD5_Error, data=CanCom_FD5RxSignalsSR.COMRX_OBC_IdleTimeSec_HV_CHARGER2_FD5
      data received event DRECOMRX_OBC_Pilot_HV_CHARGER2_FD5: start-on-event=COMRX_OBC_Pilot_HV_CHARGER2_FD5_Received, data=CanCom_FD5RxSignalsSR.COMRX_OBC_Pilot_HV_CHARGER2_FD5
      data receive error event DEECOMRX_OBC_Pilot_HV_CHARGER2_FD5: start-on-event=COMRX_OBC_Pilot_HV_CHARGER2_FD5_Error, data=CanCom_FD5RxSignalsSR.COMRX_OBC_Pilot_HV_CHARGER2_FD5
      data received event DRECOMRX_OBC_Prox_HV_CHARGER2_FD5: start-on-event=COMRX_OBC_Prox_HV_CHARGER2_FD5_Received, data=CanCom_FD5RxSignalsSR.COMRX_OBC_Prox_HV_CHARGER2_FD5
      data receive error event DEECOMRX_OBC_Prox_HV_CHARGER2_FD5: start-on-event=COMRX_OBC_Prox_HV_CHARGER2_FD5_Error, data=CanCom_FD5RxSignalsSR.COMRX_OBC_Prox_HV_CHARGER2_FD5
      data received event DRECOMRX_OBC_WakeReason_HV_CHARGER2_FD5: start-on-event=COMRX_OBC_WakeReason_HV_CHARGER2_FD5_Received, data=CanCom_FD5RxSignalsSR.COMRX_OBC_WakeReason_HV_CHARGER2_FD5
      data receive error event DEECOMRX_OBC_WakeReason_HV_CHARGER2_FD5: start-on-event=COMRX_OBC_WakeReason_HV_CHARGER2_FD5_Error, data=CanCom_FD5RxSignalsSR.COMRX_OBC_WakeReason_HV_CHARGER2_FD5
      data received event DRECOMRX_OBCM_PrechargeSts_HV_CHARGER2_FD5: start-on-event=COMRX_OBCM_PrechargeSts_HV_CHARGER2_FD5_Received, data=CanCom_FD5RxSignalsSR.COMRX_OBCM_PrechargeSts_HV_CHARGER2_FD5
      data receive error event DEECOMRX_OBCM_PrechargeSts_HV_CHARGER2_FD5: start-on-event=COMRX_OBCM_PrechargeSts_HV_CHARGER2_FD5_Error, data=CanCom_FD5RxSignalsSR.COMRX_OBCM_PrechargeSts_HV_CHARGER2_FD5
      data received event DRECOMRX_OnboardChargerMode_HV_CHARGER2_FD5: start-on-event=COMRX_OnboardChargerMode_HV_CHARGER2_FD5_Received, data=CanCom_FD5RxSignalsSR.COMRX_OnboardChargerMode_HV_CHARGER2_FD5
      data receive error event DEECOMRX_OnboardChargerMode_HV_CHARGER2_FD5: start-on-event=COMRX_OnboardChargerMode_HV_CHARGER2_FD5_Error, data=CanCom_FD5RxSignalsSR.COMRX_OnboardChargerMode_HV_CHARGER2_FD5
      data received event DRECOMRX_OnboardChargerReady_HV_CHARGER2_FD5: start-on-event=COMRX_OnboardChargerReady_HV_CHARGER2_FD5_Received, data=CanCom_FD5RxSignalsSR.COMRX_OnboardChargerReady_HV_CHARGER2_FD5
      data receive error event DEECOMRX_OnboardChargerReady_HV_CHARGER2_FD5: start-on-event=COMRX_OnboardChargerReady_HV_CHARGER2_FD5_Error, data=CanCom_FD5RxSignalsSR.COMRX_OnboardChargerReady_HV_CHARGER2_FD5
      data received event DRECOMRX_Contract_Certificate_Present_IDCM_ISO15118_STATUS1_FD5: start-on-event=COMRX_Contract_Certificate_Present_IDCM_ISO15118_STATUS1_FD5_Received, data=CanCom_FD5RxSignalsSR.COMRX_Contract_Certificate_Present_IDCM_ISO15118_STATUS1_FD5
      data receive error event DEECOMRX_Contract_Certificate_Present_IDCM_ISO15118_STATUS1_FD5: start-on-event=COMRX_Contract_Certificate_Present_IDCM_ISO15118_STATUS1_FD5_Error, data=CanCom_FD5RxSignalsSR.COMRX_Contract_Certificate_Present_IDCM_ISO15118_STATUS1_FD5
      data received event DRECOMRX_EVSE_Offered_AC_Single_Phase_IDCM_ISO15118_STATUS1_FD5: start-on-event=COMRX_EVSE_Offered_AC_Single_Phase_IDCM_ISO15118_STATUS1_FD5_Received, data=CanCom_FD5RxSignalsSR.COMRX_EVSE_Offered_AC_Single_Phase_IDCM_ISO15118_STATUS1_FD5
      data receive error event DEECOMRX_EVSE_Offered_AC_Single_Phase_IDCM_ISO15118_STATUS1_FD5: start-on-event=COMRX_EVSE_Offered_AC_Single_Phase_IDCM_ISO15118_STATUS1_FD5_Error, data=CanCom_FD5RxSignalsSR.COMRX_EVSE_Offered_AC_Single_Phase_IDCM_ISO15118_STATUS1_FD5
      data received event DRECOMRX_EVSE_Offered_AC_Three_Phase_IDCM_ISO15118_STATUS1_FD5: start-on-event=COMRX_EVSE_Offered_AC_Three_Phase_IDCM_ISO15118_STATUS1_FD5_Received, data=CanCom_FD5RxSignalsSR.COMRX_EVSE_Offered_AC_Three_Phase_IDCM_ISO15118_STATUS1_FD5
      data receive error event DEECOMRX_EVSE_Offered_AC_Three_Phase_IDCM_ISO15118_STATUS1_FD5: start-on-event=COMRX_EVSE_Offered_AC_Three_Phase_IDCM_ISO15118_STATUS1_FD5_Error, data=CanCom_FD5RxSignalsSR.COMRX_EVSE_Offered_AC_Three_Phase_IDCM_ISO15118_STATUS1_FD5
      data received event DRECOMRX_CLrDiagInfo_MCPA_P_MCPA_STATUS_FD5: start-on-event=COMRX_CLrDiagInfo_MCPA_P_MCPA_STATUS_FD5_Received, data=CanCom_FD5RxSignalsSR.COMRX_CLrDiagInfo_MCPA_P_MCPA_STATUS_FD5
      data receive error event DEECOMRX_CLrDiagInfo_MCPA_P_MCPA_STATUS_FD5: start-on-event=COMRX_CLrDiagInfo_MCPA_P_MCPA_STATUS_FD5_Error, data=CanCom_FD5RxSignalsSR.COMRX_CLrDiagInfo_MCPA_P_MCPA_STATUS_FD5
      data received event DRECOMRX_CRC_MCPA_STATUS_MCPA_STATUS_FD5: start-on-event=COMRX_CRC_MCPA_STATUS_MCPA_STATUS_FD5_Received, data=CanCom_FD5RxSignalsSR.COMRX_CRC_MCPA_STATUS_MCPA_STATUS_FD5
      data receive error event DEECOMRX_CRC_MCPA_STATUS_MCPA_STATUS_FD5: start-on-event=COMRX_CRC_MCPA_STATUS_MCPA_STATUS_FD5_Error, data=CanCom_FD5RxSignalsSR.COMRX_CRC_MCPA_STATUS_MCPA_STATUS_FD5
      data received event DRECOMRX_MC_MCPA_STATUS_MCPA_STATUS_FD5: start-on-event=COMRX_MC_MCPA_STATUS_MCPA_STATUS_FD5_Received, data=CanCom_FD5RxSignalsSR.COMRX_MC_MCPA_STATUS_MCPA_STATUS_FD5
      data receive error event DEECOMRX_MC_MCPA_STATUS_MCPA_STATUS_FD5: start-on-event=COMRX_MC_MCPA_STATUS_MCPA_STATUS_FD5_Error, data=CanCom_FD5RxSignalsSR.COMRX_MC_MCPA_STATUS_MCPA_STATUS_FD5
      data received event DRECOMRX_MCPA_Control_Board_Temperature_P_MCPA_STATUS_FD5: start-on-event=COMRX_MCPA_Control_Board_Temperature_P_MCPA_STATUS_FD5_Received, data=CanCom_FD5RxSignalsSR.COMRX_MCPA_Control_Board_Temperature_P_MCPA_STATUS_FD5
      data receive error event DEECOMRX_MCPA_Control_Board_Temperature_P_MCPA_STATUS_FD5: start-on-event=COMRX_MCPA_Control_Board_Temperature_P_MCPA_STATUS_FD5_Error, data=CanCom_FD5RxSignalsSR.COMRX_MCPA_Control_Board_Temperature_P_MCPA_STATUS_FD5
      data received event DRECOMRX_MCPA_CoolantTemp_P_MCPA_STATUS_FD5: start-on-event=COMRX_MCPA_CoolantTemp_P_MCPA_STATUS_FD5_Received, data=CanCom_FD5RxSignalsSR.COMRX_MCPA_CoolantTemp_P_MCPA_STATUS_FD5
      data receive error event DEECOMRX_MCPA_CoolantTemp_P_MCPA_STATUS_FD5: start-on-event=COMRX_MCPA_CoolantTemp_P_MCPA_STATUS_FD5_Error, data=CanCom_FD5RxSignalsSR.COMRX_MCPA_CoolantTemp_P_MCPA_STATUS_FD5
      data received event DRECOMRX_MCPA_DC_Current_P_MCPA_STATUS_FD5: start-on-event=COMRX_MCPA_DC_Current_P_MCPA_STATUS_FD5_Received, data=CanCom_FD5RxSignalsSR.COMRX_MCPA_DC_Current_P_MCPA_STATUS_FD5
      data receive error event DEECOMRX_MCPA_DC_Current_P_MCPA_STATUS_FD5: start-on-event=COMRX_MCPA_DC_Current_P_MCPA_STATUS_FD5_Error, data=CanCom_FD5RxSignalsSR.COMRX_MCPA_DC_Current_P_MCPA_STATUS_FD5
      data received event DRECOMRX_MCPA_DC_Current_V_P_MCPA_STATUS_FD5: start-on-event=COMRX_MCPA_DC_Current_V_P_MCPA_STATUS_FD5_Received, data=CanCom_FD5RxSignalsSR.COMRX_MCPA_DC_Current_V_P_MCPA_STATUS_FD5
      data receive error event DEECOMRX_MCPA_DC_Current_V_P_MCPA_STATUS_FD5: start-on-event=COMRX_MCPA_DC_Current_V_P_MCPA_STATUS_FD5_Error, data=CanCom_FD5RxSignalsSR.COMRX_MCPA_DC_Current_V_P_MCPA_STATUS_FD5
      data received event DRECOMRX_MCPA_DC_Volt_V_P_MCPA_STATUS_FD5: start-on-event=COMRX_MCPA_DC_Volt_V_P_MCPA_STATUS_FD5_Received, data=CanCom_FD5RxSignalsSR.COMRX_MCPA_DC_Volt_V_P_MCPA_STATUS_FD5
      data receive error event DEECOMRX_MCPA_DC_Volt_V_P_MCPA_STATUS_FD5: start-on-event=COMRX_MCPA_DC_Volt_V_P_MCPA_STATUS_FD5_Error, data=CanCom_FD5RxSignalsSR.COMRX_MCPA_DC_Volt_V_P_MCPA_STATUS_FD5
      data received event DRECOMRX_MCPA_DC_Voltage_P_MCPA_STATUS_FD5: start-on-event=COMRX_MCPA_DC_Voltage_P_MCPA_STATUS_FD5_Received, data=CanCom_FD5RxSignalsSR.COMRX_MCPA_DC_Voltage_P_MCPA_STATUS_FD5
      data receive error event DEECOMRX_MCPA_DC_Voltage_P_MCPA_STATUS_FD5: start-on-event=COMRX_MCPA_DC_Voltage_P_MCPA_STATUS_FD5_Error, data=CanCom_FD5RxSignalsSR.COMRX_MCPA_DC_Voltage_P_MCPA_STATUS_FD5
      data received event DRECOMRX_MCPA_DerateReason_P_MCPA_STATUS_FD5: start-on-event=COMRX_MCPA_DerateReason_P_MCPA_STATUS_FD5_Received, data=CanCom_FD5RxSignalsSR.COMRX_MCPA_DerateReason_P_MCPA_STATUS_FD5
      data receive error event DEECOMRX_MCPA_DerateReason_P_MCPA_STATUS_FD5: start-on-event=COMRX_MCPA_DerateReason_P_MCPA_STATUS_FD5_Error, data=CanCom_FD5RxSignalsSR.COMRX_MCPA_DerateReason_P_MCPA_STATUS_FD5
      data received event DRECOMRX_MCPA_Inverter_Temp_P_MCPA_STATUS_FD5: start-on-event=COMRX_MCPA_Inverter_Temp_P_MCPA_STATUS_FD5_Received, data=CanCom_FD5RxSignalsSR.COMRX_MCPA_Inverter_Temp_P_MCPA_STATUS_FD5
      data receive error event DEECOMRX_MCPA_Inverter_Temp_P_MCPA_STATUS_FD5: start-on-event=COMRX_MCPA_Inverter_Temp_P_MCPA_STATUS_FD5_Error, data=CanCom_FD5RxSignalsSR.COMRX_MCPA_Inverter_Temp_P_MCPA_STATUS_FD5
      data received event DRECOMRX_MCPA_PIM_DC_Side_Busbar_Temp_P_MCPA_STATUS_FD5: start-on-event=COMRX_MCPA_PIM_DC_Side_Busbar_Temp_P_MCPA_STATUS_FD5_Received, data=CanCom_FD5RxSignalsSR.COMRX_MCPA_PIM_DC_Side_Busbar_Temp_P_MCPA_STATUS_FD5
      data receive error event DEECOMRX_MCPA_PIM_DC_Side_Busbar_Temp_P_MCPA_STATUS_FD5: start-on-event=COMRX_MCPA_PIM_DC_Side_Busbar_Temp_P_MCPA_STATUS_FD5_Error, data=CanCom_FD5RxSignalsSR.COMRX_MCPA_PIM_DC_Side_Busbar_Temp_P_MCPA_STATUS_FD5
      data received event DRECOMRX_MCPA_Rotor_Temperature_P_MCPA_STATUS_FD5: start-on-event=COMRX_MCPA_Rotor_Temperature_P_MCPA_STATUS_FD5_Received, data=CanCom_FD5RxSignalsSR.COMRX_MCPA_Rotor_Temperature_P_MCPA_STATUS_FD5
      data receive error event DEECOMRX_MCPA_Rotor_Temperature_P_MCPA_STATUS_FD5: start-on-event=COMRX_MCPA_Rotor_Temperature_P_MCPA_STATUS_FD5_Error, data=CanCom_FD5RxSignalsSR.COMRX_MCPA_Rotor_Temperature_P_MCPA_STATUS_FD5
      data received event DRECOMRX_MCPA_Service_Lamp_Request_P_MCPA_STATUS_FD5: start-on-event=COMRX_MCPA_Service_Lamp_Request_P_MCPA_STATUS_FD5_Received, data=CanCom_FD5RxSignalsSR.COMRX_MCPA_Service_Lamp_Request_P_MCPA_STATUS_FD5
      data receive error event DEECOMRX_MCPA_Service_Lamp_Request_P_MCPA_STATUS_FD5: start-on-event=COMRX_MCPA_Service_Lamp_Request_P_MCPA_STATUS_FD5_Error, data=CanCom_FD5RxSignalsSR.COMRX_MCPA_Service_Lamp_Request_P_MCPA_STATUS_FD5
      data received event DRECOMRX_CLrDiagInfo_MCPB_P_MCPB_STATUS_FD5: start-on-event=COMRX_CLrDiagInfo_MCPB_P_MCPB_STATUS_FD5_Received, data=CanCom_FD5RxSignalsSR.COMRX_CLrDiagInfo_MCPB_P_MCPB_STATUS_FD5
      data receive error event DEECOMRX_CLrDiagInfo_MCPB_P_MCPB_STATUS_FD5: start-on-event=COMRX_CLrDiagInfo_MCPB_P_MCPB_STATUS_FD5_Error, data=CanCom_FD5RxSignalsSR.COMRX_CLrDiagInfo_MCPB_P_MCPB_STATUS_FD5
      data received event DRECOMRX_CRC_MCPB_STATUS_MCPB_STATUS_FD5: start-on-event=COMRX_CRC_MCPB_STATUS_MCPB_STATUS_FD5_Received, data=CanCom_FD5RxSignalsSR.COMRX_CRC_MCPB_STATUS_MCPB_STATUS_FD5
      data receive error event DEECOMRX_CRC_MCPB_STATUS_MCPB_STATUS_FD5: start-on-event=COMRX_CRC_MCPB_STATUS_MCPB_STATUS_FD5_Error, data=CanCom_FD5RxSignalsSR.COMRX_CRC_MCPB_STATUS_MCPB_STATUS_FD5
      data received event DRECOMRX_MC_MCPB_STATUS_MCPB_STATUS_FD5: start-on-event=COMRX_MC_MCPB_STATUS_MCPB_STATUS_FD5_Received, data=CanCom_FD5RxSignalsSR.COMRX_MC_MCPB_STATUS_MCPB_STATUS_FD5
      data receive error event DEECOMRX_MC_MCPB_STATUS_MCPB_STATUS_FD5: start-on-event=COMRX_MC_MCPB_STATUS_MCPB_STATUS_FD5_Error, data=CanCom_FD5RxSignalsSR.COMRX_MC_MCPB_STATUS_MCPB_STATUS_FD5
      data received event DRECOMRX_MCPB_Control_Board_Temperature_P_MCPB_STATUS_FD5: start-on-event=COMRX_MCPB_Control_Board_Temperature_P_MCPB_STATUS_FD5_Received, data=CanCom_FD5RxSignalsSR.COMRX_MCPB_Control_Board_Temperature_P_MCPB_STATUS_FD5
      data receive error event DEECOMRX_MCPB_Control_Board_Temperature_P_MCPB_STATUS_FD5: start-on-event=COMRX_MCPB_Control_Board_Temperature_P_MCPB_STATUS_FD5_Error, data=CanCom_FD5RxSignalsSR.COMRX_MCPB_Control_Board_Temperature_P_MCPB_STATUS_FD5
      data received event DRECOMRX_MCPB_CoolantTemp_P_MCPB_STATUS_FD5: start-on-event=COMRX_MCPB_CoolantTemp_P_MCPB_STATUS_FD5_Received, data=CanCom_FD5RxSignalsSR.COMRX_MCPB_CoolantTemp_P_MCPB_STATUS_FD5
      data receive error event DEECOMRX_MCPB_CoolantTemp_P_MCPB_STATUS_FD5: start-on-event=COMRX_MCPB_CoolantTemp_P_MCPB_STATUS_FD5_Error, data=CanCom_FD5RxSignalsSR.COMRX_MCPB_CoolantTemp_P_MCPB_STATUS_FD5
      data received event DRECOMRX_MCPB_DC_Current_P_MCPB_STATUS_FD5: start-on-event=COMRX_MCPB_DC_Current_P_MCPB_STATUS_FD5_Received, data=CanCom_FD5RxSignalsSR.COMRX_MCPB_DC_Current_P_MCPB_STATUS_FD5
      data receive error event DEECOMRX_MCPB_DC_Current_P_MCPB_STATUS_FD5: start-on-event=COMRX_MCPB_DC_Current_P_MCPB_STATUS_FD5_Error, data=CanCom_FD5RxSignalsSR.COMRX_MCPB_DC_Current_P_MCPB_STATUS_FD5
      data received event DRECOMRX_MCPB_DC_Current_V_P_MCPB_STATUS_FD5: start-on-event=COMRX_MCPB_DC_Current_V_P_MCPB_STATUS_FD5_Received, data=CanCom_FD5RxSignalsSR.COMRX_MCPB_DC_Current_V_P_MCPB_STATUS_FD5
      data receive error event DEECOMRX_MCPB_DC_Current_V_P_MCPB_STATUS_FD5: start-on-event=COMRX_MCPB_DC_Current_V_P_MCPB_STATUS_FD5_Error, data=CanCom_FD5RxSignalsSR.COMRX_MCPB_DC_Current_V_P_MCPB_STATUS_FD5
      data received event DRECOMRX_MCPB_DC_Volt_V_P_MCPB_STATUS_FD5: start-on-event=COMRX_MCPB_DC_Volt_V_P_MCPB_STATUS_FD5_Received, data=CanCom_FD5RxSignalsSR.COMRX_MCPB_DC_Volt_V_P_MCPB_STATUS_FD5
      data receive error event DEECOMRX_MCPB_DC_Volt_V_P_MCPB_STATUS_FD5: start-on-event=COMRX_MCPB_DC_Volt_V_P_MCPB_STATUS_FD5_Error, data=CanCom_FD5RxSignalsSR.COMRX_MCPB_DC_Volt_V_P_MCPB_STATUS_FD5
      data received event DRECOMRX_MCPB_DC_Voltage_P_MCPB_STATUS_FD5: start-on-event=COMRX_MCPB_DC_Voltage_P_MCPB_STATUS_FD5_Received, data=CanCom_FD5RxSignalsSR.COMRX_MCPB_DC_Voltage_P_MCPB_STATUS_FD5
      data receive error event DEECOMRX_MCPB_DC_Voltage_P_MCPB_STATUS_FD5: start-on-event=COMRX_MCPB_DC_Voltage_P_MCPB_STATUS_FD5_Error, data=CanCom_FD5RxSignalsSR.COMRX_MCPB_DC_Voltage_P_MCPB_STATUS_FD5
      data received event DRECOMRX_MCPB_DerateReason_P_MCPB_STATUS_FD5: start-on-event=COMRX_MCPB_DerateReason_P_MCPB_STATUS_FD5_Received, data=CanCom_FD5RxSignalsSR.COMRX_MCPB_DerateReason_P_MCPB_STATUS_FD5
      data receive error event DEECOMRX_MCPB_DerateReason_P_MCPB_STATUS_FD5: start-on-event=COMRX_MCPB_DerateReason_P_MCPB_STATUS_FD5_Error, data=CanCom_FD5RxSignalsSR.COMRX_MCPB_DerateReason_P_MCPB_STATUS_FD5
      data received event DRECOMRX_MCPB_Inverter_Temp_P_MCPB_STATUS_FD5: start-on-event=COMRX_MCPB_Inverter_Temp_P_MCPB_STATUS_FD5_Received, data=CanCom_FD5RxSignalsSR.COMRX_MCPB_Inverter_Temp_P_MCPB_STATUS_FD5
      data receive error event DEECOMRX_MCPB_Inverter_Temp_P_MCPB_STATUS_FD5: start-on-event=COMRX_MCPB_Inverter_Temp_P_MCPB_STATUS_FD5_Error, data=CanCom_FD5RxSignalsSR.COMRX_MCPB_Inverter_Temp_P_MCPB_STATUS_FD5
      data received event DRECOMRX_MCPB_PIM_DC_Side_Busbar_Temp_P_MCPB_STATUS_FD5: start-on-event=COMRX_MCPB_PIM_DC_Side_Busbar_Temp_P_MCPB_STATUS_FD5_Received, data=CanCom_FD5RxSignalsSR.COMRX_MCPB_PIM_DC_Side_Busbar_Temp_P_MCPB_STATUS_FD5
      data receive error event DEECOMRX_MCPB_PIM_DC_Side_Busbar_Temp_P_MCPB_STATUS_FD5: start-on-event=COMRX_MCPB_PIM_DC_Side_Busbar_Temp_P_MCPB_STATUS_FD5_Error, data=CanCom_FD5RxSignalsSR.COMRX_MCPB_PIM_DC_Side_Busbar_Temp_P_MCPB_STATUS_FD5
      data received event DRECOMRX_MCPB_Rotor_Temperature_P_MCPB_STATUS_FD5: start-on-event=COMRX_MCPB_Rotor_Temperature_P_MCPB_STATUS_FD5_Received, data=CanCom_FD5RxSignalsSR.COMRX_MCPB_Rotor_Temperature_P_MCPB_STATUS_FD5
      data receive error event DEECOMRX_MCPB_Rotor_Temperature_P_MCPB_STATUS_FD5: start-on-event=COMRX_MCPB_Rotor_Temperature_P_MCPB_STATUS_FD5_Error, data=CanCom_FD5RxSignalsSR.COMRX_MCPB_Rotor_Temperature_P_MCPB_STATUS_FD5
      data received event DRECOMRX_MCPB_Service_Lamp_Request_P_MCPB_STATUS_FD5: start-on-event=COMRX_MCPB_Service_Lamp_Request_P_MCPB_STATUS_FD5_Received, data=CanCom_FD5RxSignalsSR.COMRX_MCPB_Service_Lamp_Request_P_MCPB_STATUS_FD5
      data receive error event DEECOMRX_MCPB_Service_Lamp_Request_P_MCPB_STATUS_FD5: start-on-event=COMRX_MCPB_Service_Lamp_Request_P_MCPB_STATUS_FD5_Error, data=CanCom_FD5RxSignalsSR.COMRX_MCPB_Service_Lamp_Request_P_MCPB_STATUS_FD5
      data received event DRECOMRX_V2H_HVCMS_EVSEMaxPowerLimit_RPF_FD_1_FD5: start-on-event=COMRX_V2H_HVCMS_EVSEMaxPowerLimit_RPF_FD_1_FD5_Received, data=CanCom_FD5RxSignalsSR.COMRX_V2H_HVCMS_EVSEMaxPowerLimit_RPF_FD_1_FD5
      data receive error event DEECOMRX_V2H_HVCMS_EVSEMaxPowerLimit_RPF_FD_1_FD5: start-on-event=COMRX_V2H_HVCMS_EVSEMaxPowerLimit_RPF_FD_1_FD5_Error, data=CanCom_FD5RxSignalsSR.COMRX_V2H_HVCMS_EVSEMaxPowerLimit_RPF_FD_1_FD5
      data received event DRECOMRX_CLrDiagInfo_SGCP_P_SGCP_STATUS_FD5: start-on-event=COMRX_CLrDiagInfo_SGCP_P_SGCP_STATUS_FD5_Received, data=CanCom_FD5RxSignalsSR.COMRX_CLrDiagInfo_SGCP_P_SGCP_STATUS_FD5
      data receive error event DEECOMRX_CLrDiagInfo_SGCP_P_SGCP_STATUS_FD5: start-on-event=COMRX_CLrDiagInfo_SGCP_P_SGCP_STATUS_FD5_Error, data=CanCom_FD5RxSignalsSR.COMRX_CLrDiagInfo_SGCP_P_SGCP_STATUS_FD5
      data received event DRECOMRX_CRC_SGCP_STATUS_SGCP_STATUS_FD5: start-on-event=COMRX_CRC_SGCP_STATUS_SGCP_STATUS_FD5_Received, data=CanCom_FD5RxSignalsSR.COMRX_CRC_SGCP_STATUS_SGCP_STATUS_FD5
      data receive error event DEECOMRX_CRC_SGCP_STATUS_SGCP_STATUS_FD5: start-on-event=COMRX_CRC_SGCP_STATUS_SGCP_STATUS_FD5_Error, data=CanCom_FD5RxSignalsSR.COMRX_CRC_SGCP_STATUS_SGCP_STATUS_FD5
      data received event DRECOMRX_MC_SGCP_STATUS_SGCP_STATUS_FD5: start-on-event=COMRX_MC_SGCP_STATUS_SGCP_STATUS_FD5_Received, data=CanCom_FD5RxSignalsSR.COMRX_MC_SGCP_STATUS_SGCP_STATUS_FD5
      data receive error event DEECOMRX_MC_SGCP_STATUS_SGCP_STATUS_FD5: start-on-event=COMRX_MC_SGCP_STATUS_SGCP_STATUS_FD5_Error, data=CanCom_FD5RxSignalsSR.COMRX_MC_SGCP_STATUS_SGCP_STATUS_FD5
      data received event DRECOMRX_SGCP_Control_Board_Temperature_P_SGCP_STATUS_FD5: start-on-event=COMRX_SGCP_Control_Board_Temperature_P_SGCP_STATUS_FD5_Received, data=CanCom_FD5RxSignalsSR.COMRX_SGCP_Control_Board_Temperature_P_SGCP_STATUS_FD5
      data receive error event DEECOMRX_SGCP_Control_Board_Temperature_P_SGCP_STATUS_FD5: start-on-event=COMRX_SGCP_Control_Board_Temperature_P_SGCP_STATUS_FD5_Error, data=CanCom_FD5RxSignalsSR.COMRX_SGCP_Control_Board_Temperature_P_SGCP_STATUS_FD5
      data received event DRECOMRX_SGCP_CoolantTemp_P_SGCP_STATUS_FD5: start-on-event=COMRX_SGCP_CoolantTemp_P_SGCP_STATUS_FD5_Received, data=CanCom_FD5RxSignalsSR.COMRX_SGCP_CoolantTemp_P_SGCP_STATUS_FD5
      data receive error event DEECOMRX_SGCP_CoolantTemp_P_SGCP_STATUS_FD5: start-on-event=COMRX_SGCP_CoolantTemp_P_SGCP_STATUS_FD5_Error, data=CanCom_FD5RxSignalsSR.COMRX_SGCP_CoolantTemp_P_SGCP_STATUS_FD5
      data received event DRECOMRX_SGCP_DC_Current_P_SGCP_STATUS_FD5: start-on-event=COMRX_SGCP_DC_Current_P_SGCP_STATUS_FD5_Received, data=CanCom_FD5RxSignalsSR.COMRX_SGCP_DC_Current_P_SGCP_STATUS_FD5
      data receive error event DEECOMRX_SGCP_DC_Current_P_SGCP_STATUS_FD5: start-on-event=COMRX_SGCP_DC_Current_P_SGCP_STATUS_FD5_Error, data=CanCom_FD5RxSignalsSR.COMRX_SGCP_DC_Current_P_SGCP_STATUS_FD5
      data received event DRECOMRX_SGCP_DC_Current_V_P_SGCP_STATUS_FD5: start-on-event=COMRX_SGCP_DC_Current_V_P_SGCP_STATUS_FD5_Received, data=CanCom_FD5RxSignalsSR.COMRX_SGCP_DC_Current_V_P_SGCP_STATUS_FD5
      data receive error event DEECOMRX_SGCP_DC_Current_V_P_SGCP_STATUS_FD5: start-on-event=COMRX_SGCP_DC_Current_V_P_SGCP_STATUS_FD5_Error, data=CanCom_FD5RxSignalsSR.COMRX_SGCP_DC_Current_V_P_SGCP_STATUS_FD5
      data received event DRECOMRX_SGCP_DC_Volt_V_P_SGCP_STATUS_FD5: start-on-event=COMRX_SGCP_DC_Volt_V_P_SGCP_STATUS_FD5_Received, data=CanCom_FD5RxSignalsSR.COMRX_SGCP_DC_Volt_V_P_SGCP_STATUS_FD5
      data receive error event DEECOMRX_SGCP_DC_Volt_V_P_SGCP_STATUS_FD5: start-on-event=COMRX_SGCP_DC_Volt_V_P_SGCP_STATUS_FD5_Error, data=CanCom_FD5RxSignalsSR.COMRX_SGCP_DC_Volt_V_P_SGCP_STATUS_FD5
      data received event DRECOMRX_SGCP_DC_Voltage_P_SGCP_STATUS_FD5: start-on-event=COMRX_SGCP_DC_Voltage_P_SGCP_STATUS_FD5_Received, data=CanCom_FD5RxSignalsSR.COMRX_SGCP_DC_Voltage_P_SGCP_STATUS_FD5
      data receive error event DEECOMRX_SGCP_DC_Voltage_P_SGCP_STATUS_FD5: start-on-event=COMRX_SGCP_DC_Voltage_P_SGCP_STATUS_FD5_Error, data=CanCom_FD5RxSignalsSR.COMRX_SGCP_DC_Voltage_P_SGCP_STATUS_FD5
      data received event DRECOMRX_SGCP_DerateReason_P_SGCP_STATUS_FD5: start-on-event=COMRX_SGCP_DerateReason_P_SGCP_STATUS_FD5_Received, data=CanCom_FD5RxSignalsSR.COMRX_SGCP_DerateReason_P_SGCP_STATUS_FD5
      data receive error event DEECOMRX_SGCP_DerateReason_P_SGCP_STATUS_FD5: start-on-event=COMRX_SGCP_DerateReason_P_SGCP_STATUS_FD5_Error, data=CanCom_FD5RxSignalsSR.COMRX_SGCP_DerateReason_P_SGCP_STATUS_FD5
      data received event DRECOMRX_SGCP_Inverter_Temp_P_SGCP_STATUS_FD5: start-on-event=COMRX_SGCP_Inverter_Temp_P_SGCP_STATUS_FD5_Received, data=CanCom_FD5RxSignalsSR.COMRX_SGCP_Inverter_Temp_P_SGCP_STATUS_FD5
      data receive error event DEECOMRX_SGCP_Inverter_Temp_P_SGCP_STATUS_FD5: start-on-event=COMRX_SGCP_Inverter_Temp_P_SGCP_STATUS_FD5_Error, data=CanCom_FD5RxSignalsSR.COMRX_SGCP_Inverter_Temp_P_SGCP_STATUS_FD5
      data received event DRECOMRX_SGCP_PIM_AC_Side_Busbar_Temp_P_SGCP_STATUS_FD5: start-on-event=COMRX_SGCP_PIM_AC_Side_Busbar_Temp_P_SGCP_STATUS_FD5_Received, data=CanCom_FD5RxSignalsSR.COMRX_SGCP_PIM_AC_Side_Busbar_Temp_P_SGCP_STATUS_FD5
      data receive error event DEECOMRX_SGCP_PIM_AC_Side_Busbar_Temp_P_SGCP_STATUS_FD5: start-on-event=COMRX_SGCP_PIM_AC_Side_Busbar_Temp_P_SGCP_STATUS_FD5_Error, data=CanCom_FD5RxSignalsSR.COMRX_SGCP_PIM_AC_Side_Busbar_Temp_P_SGCP_STATUS_FD5
      data received event DRECOMRX_SGCP_PIM_DC_Side_Busbar_Temp_P_SGCP_STATUS_FD5: start-on-event=COMRX_SGCP_PIM_DC_Side_Busbar_Temp_P_SGCP_STATUS_FD5_Received, data=CanCom_FD5RxSignalsSR.COMRX_SGCP_PIM_DC_Side_Busbar_Temp_P_SGCP_STATUS_FD5
      data receive error event DEECOMRX_SGCP_PIM_DC_Side_Busbar_Temp_P_SGCP_STATUS_FD5: start-on-event=COMRX_SGCP_PIM_DC_Side_Busbar_Temp_P_SGCP_STATUS_FD5_Error, data=CanCom_FD5RxSignalsSR.COMRX_SGCP_PIM_DC_Side_Busbar_Temp_P_SGCP_STATUS_FD5
      data received event DRECOMRX_SGCP_Rotor_Temperature_P_SGCP_STATUS_FD5: start-on-event=COMRX_SGCP_Rotor_Temperature_P_SGCP_STATUS_FD5_Received, data=CanCom_FD5RxSignalsSR.COMRX_SGCP_Rotor_Temperature_P_SGCP_STATUS_FD5
      data receive error event DEECOMRX_SGCP_Rotor_Temperature_P_SGCP_STATUS_FD5: start-on-event=COMRX_SGCP_Rotor_Temperature_P_SGCP_STATUS_FD5_Error, data=CanCom_FD5RxSignalsSR.COMRX_SGCP_Rotor_Temperature_P_SGCP_STATUS_FD5
      data received event DRECOMRX_SGCP_Service_Lamp_Request_P_SGCP_STATUS_FD5: start-on-event=COMRX_SGCP_Service_Lamp_Request_P_SGCP_STATUS_FD5_Received, data=CanCom_FD5RxSignalsSR.COMRX_SGCP_Service_Lamp_Request_P_SGCP_STATUS_FD5
      data receive error event DEECOMRX_SGCP_Service_Lamp_Request_P_SGCP_STATUS_FD5: start-on-event=COMRX_SGCP_Service_Lamp_Request_P_SGCP_STATUS_FD5_Error, data=CanCom_FD5RxSignalsSR.COMRX_SGCP_Service_Lamp_Request_P_SGCP_STATUS_FD5
      72 x data received event:
        DRESendCANR_OperationalModeSts_FD5: start-on-event=SendCANR_OperationalModeSts_FD5, data=SendCANR_OperationalModeSts_FD5.SendCANR_OperationalModeSts_FD5
        DRESendCANR_Battery_Volt_1_FD5: start-on-event=SendCANR_Battery_Volt_1_FD5, data=SendCANR_Battery_Volt_1_FD5.SendCANR_Battery_Volt_1_FD5
        DRESendCANR_IgnitionOnCounter_FD5: start-on-event=SendCANR_IgnitionOnCounter_FD5, data=SendCANR_IgnitionOnCounter_FD5.SendCANR_IgnitionOnCounter_FD5
        DRESendCANR_ExtTemp_FD5: start-on-event=SendCANR_ExtTemp_FD5, data=SendCANR_ExtTemp_FD5.SendCANR_ExtTemp_FD5
        DRESendCANR_EPBSts_FD5: start-on-event=SendCANR_EPBSts_FD5, data=SendCANR_EPBSts_FD5.SendCANR_EPBSts_FD5
        DRESendCANR_ABSFailSts_FD5: start-on-event=SendCANR_ABSFailSts_FD5, data=SendCANR_ABSFailSts_FD5.SendCANR_ABSFailSts_FD5
        DRESendCANR_ESCFailSts_FD5: start-on-event=SendCANR_ESCFailSts_FD5, data=SendCANR_ESCFailSts_FD5.SendCANR_ESCFailSts_FD5
        DRESendCANR_Eamount_FD5: start-on-event=SendCANR_Eamount_FD5, data=SendCANR_Eamount_FD5.SendCANR_Eamount_FD5
        DRESendCANR_EVMaxCurrent_FD5: start-on-event=SendCANR_EVMaxCurrent_FD5, data=SendCANR_EVMaxCurrent_FD5.SendCANR_EVMaxCurrent_FD5
        DRESendCANR_EVMaxVoltage_FD5: start-on-event=SendCANR_EVMaxVoltage_FD5, data=SendCANR_EVMaxVoltage_FD5.SendCANR_EVMaxVoltage_FD5
        DRESendCANR_EVMinCurrent_FD5: start-on-event=SendCANR_EVMinCurrent_FD5, data=SendCANR_EVMinCurrent_FD5.SendCANR_EVMinCurrent_FD5
        DRESendCANR_FOTA_Status_FD5: start-on-event=SendCANR_FOTA_Status_FD5, data=SendCANR_FOTA_Status_FD5.SendCANR_FOTA_Status_FD5
        DRESendCANR_N_PDU_7E_FD5: start-on-event=SendCANR_N_PDU_7E_FD5, data=SendCANR_N_PDU_7E_FD5.SendCANR_N_PDU_7E_FD5
        DRESendCANR_N_PDU_7F_FD5: start-on-event=SendCANR_N_PDU_7F_FD5, data=SendCANR_N_PDU_7F_FD5.SendCANR_N_PDU_7F_FD5
        DRESendCANR_PerWakeUp_Diag_FD5: start-on-event=SendCANR_PerWakeUp_Diag_FD5, data=SendCANR_PerWakeUp_Diag_FD5.SendCANR_PerWakeUp_Diag_FD5
        DRESendCANR_WU_Timer_Value_FD5: start-on-event=SendCANR_WU_Timer_Value_FD5, data=SendCANR_WU_Timer_Value_FD5.SendCANR_WU_Timer_Value_FD5
        DRESendCANR_CRC_HYBD_THRML_CMD_FD5: start-on-event=SendCANR_CRC_HYBD_THRML_CMD_FD5, data=SendCANR_CRC_HYBD_THRML_CMD_FD5.SendCANR_CRC_HYBD_THRML_CMD_FD5
        DRESendCANR_EOPA_OIL_FlwRate_FD5: start-on-event=SendCANR_EOPA_OIL_FlwRate_FD5, data=SendCANR_EOPA_OIL_FlwRate_FD5.SendCANR_EOPA_OIL_FlwRate_FD5
        DRESendCANR_EOPA_OIL_TEMP_FD5: start-on-event=SendCANR_EOPA_OIL_TEMP_FD5, data=SendCANR_EOPA_OIL_TEMP_FD5.SendCANR_EOPA_OIL_TEMP_FD5
        DRESendCANR_EOPB_OIL_FlwRate_FD5: start-on-event=SendCANR_EOPB_OIL_FlwRate_FD5, data=SendCANR_EOPB_OIL_FlwRate_FD5.SendCANR_EOPB_OIL_FlwRate_FD5
        DRESendCANR_EOPB_OIL_TEMP_FD5: start-on-event=SendCANR_EOPB_OIL_TEMP_FD5, data=SendCANR_EOPB_OIL_TEMP_FD5.SendCANR_EOPB_OIL_TEMP_FD5
        DRESendCANR_MC_HYBD_THRML_CMD_FD5: start-on-event=SendCANR_MC_HYBD_THRML_CMD_FD5, data=SendCANR_MC_HYBD_THRML_CMD_FD5.SendCANR_MC_HYBD_THRML_CMD_FD5
        DRESendCANR_SGCP_OIL_FlwRate_FD5: start-on-event=SendCANR_SGCP_OIL_FlwRate_FD5, data=SendCANR_SGCP_OIL_FlwRate_FD5.SendCANR_SGCP_OIL_FlwRate_FD5
        DRESendCANR_SGCP_OIL_TEMP_FD5: start-on-event=SendCANR_SGCP_OIL_TEMP_FD5, data=SendCANR_SGCP_OIL_TEMP_FD5.SendCANR_SGCP_OIL_TEMP_FD5
        DRESendCANR_IMPACTCommand_FD5: start-on-event=SendCANR_IMPACTCommand_FD5, data=SendCANR_IMPACTCommand_FD5.SendCANR_IMPACTCommand_FD5
        DRESendCANR_IMPACTConfirm_FD5: start-on-event=SendCANR_IMPACTConfirm_FD5, data=SendCANR_IMPACTConfirm_FD5.SendCANR_IMPACTConfirm_FD5
        DRESendCANR_TotalOdometer_FD5: start-on-event=SendCANR_TotalOdometer_FD5, data=SendCANR_TotalOdometer_FD5.SendCANR_TotalOdometer_FD5
        DRESendCANR_Real_Time_Clock_FD5: start-on-event=SendCANR_Real_Time_Clock_FD5, data=SendCANR_Real_Time_Clock_FD5.SendCANR_Real_Time_Clock_FD5
        DRESendCANR_Real_Time_Validity_FD5: start-on-event=SendCANR_Real_Time_Validity_FD5, data=SendCANR_Real_Time_Validity_FD5.SendCANR_Real_Time_Validity_FD5
        DRESendCANR_V2H_HVCMS_EVMaxP_LtFD5: start-on-event=SendCANR_V2H_HVCMS_EVMaxP_LtFD5, data=SendCANR_V2H_HVCMS_EVMaxP_LtFD5.SendCANR_V2H_HVCMS_EVMaxP_LtFD5
        DRESendCANR_GPS_Date_Day_FD5: start-on-event=SendCANR_GPS_Date_Day_FD5, data=SendCANR_GPS_Date_Day_FD5.SendCANR_GPS_Date_Day_FD5
        DRESendCANR_GPS_Date_Month_FD5: start-on-event=SendCANR_GPS_Date_Month_FD5, data=SendCANR_GPS_Date_Month_FD5.SendCANR_GPS_Date_Month_FD5
        DRESendCANR_GPS_Date_Year_FD5: start-on-event=SendCANR_GPS_Date_Year_FD5, data=SendCANR_GPS_Date_Year_FD5.SendCANR_GPS_Date_Year_FD5
        DRESendCANR_GPS_UTC_Hour_FD5: start-on-event=SendCANR_GPS_UTC_Hour_FD5, data=SendCANR_GPS_UTC_Hour_FD5.SendCANR_GPS_UTC_Hour_FD5
        DRESendCANR_GPS_UTC_Minute_FD5: start-on-event=SendCANR_GPS_UTC_Minute_FD5, data=SendCANR_GPS_UTC_Minute_FD5.SendCANR_GPS_UTC_Minute_FD5
        DRESendCANR_GPS_UTC_Second_FD5: start-on-event=SendCANR_GPS_UTC_Second_FD5, data=SendCANR_GPS_UTC_Second_FD5.SendCANR_GPS_UTC_Second_FD5
        DRESendCANR_HVCMSBlkChrgnCmpltFD5: start-on-event=SendCANR_HVCMSBlkChrgnCmpltFD5, data=SendCANR_HVCMSBlkChrgnCmpltFD5.SendCANR_HVCMSBlkChrgnCmpltFD5
        DRESendCANR_HVCMS_ChrgnCompltFD5: start-on-event=SendCANR_HVCMS_ChrgnCompltFD5, data=SendCANR_HVCMS_ChrgnCompltFD5.SendCANR_HVCMS_ChrgnCompltFD5
        DRESendCANR_HVCMS_EVEnrgCapctFD5: start-on-event=SendCANR_HVCMS_EVEnrgCapctFD5, data=SendCANR_HVCMS_EVEnrgCapctFD5.SendCANR_HVCMS_EVEnrgCapctFD5
        DRESendCANR_HVCMS_EVEnergRquestFD5: start-on-event=SendCANR_HVCMS_EVEnergRquestFD5, data=SendCANR_HVCMS_EVEnergRquestFD5.SendCANR_HVCMS_EVEnergRquestFD5
        DRESendCANR_HVCMS_EVErrorCode_FD5: start-on-event=SendCANR_HVCMS_EVErrorCode_FD5, data=SendCANR_HVCMS_EVErrorCode_FD5.SendCANR_HVCMS_EVErrorCode_FD5
        DRESendCANR_HVCMS_EVMax_I_LimitFD5: start-on-event=SendCANR_HVCMS_EVMax_I_LimitFD5, data=SendCANR_HVCMS_EVMax_I_LimitFD5.SendCANR_HVCMS_EVMax_I_LimitFD5
        DRESendCANR_HVCMS_EVMax_P_LimitFD5: start-on-event=SendCANR_HVCMS_EVMax_P_LimitFD5, data=SendCANR_HVCMS_EVMax_P_LimitFD5.SendCANR_HVCMS_EVMax_P_LimitFD5
        DRESendCANR_HVCMS_EVMax_V_LimitFD5: start-on-event=SendCANR_HVCMS_EVMax_V_LimitFD5, data=SendCANR_HVCMS_EVMax_V_LimitFD5.SendCANR_HVCMS_EVMax_V_LimitFD5
        DRESendCANR_HVCMS_EVReady_FD5: start-on-event=SendCANR_HVCMS_EVReady_FD5, data=SendCANR_HVCMS_EVReady_FD5.SendCANR_HVCMS_EVReady_FD5
        DRESendCANR_HVCMS_EVRESS_SOC_FD5: start-on-event=SendCANR_HVCMS_EVRESS_SOC_FD5, data=SendCANR_HVCMS_EVRESS_SOC_FD5.SendCANR_HVCMS_EVRESS_SOC_FD5
        DRESendCANR_HVCMS_EVRESSCndtninFD5: start-on-event=SendCANR_HVCMS_EVRESSCndtninFD5, data=SendCANR_HVCMS_EVRESSCndtninFD5.SendCANR_HVCMS_EVRESSCndtninFD5
        DRESendCANR_HVCMS_EVTargetCurntFD5: start-on-event=SendCANR_HVCMS_EVTargetCurntFD5, data=SendCANR_HVCMS_EVTargetCurntFD5.SendCANR_HVCMS_EVTargetCurntFD5
        DRESendCANR_HVCMS_EVTargetVoltFD5: start-on-event=SendCANR_HVCMS_EVTargetVoltFD5, data=SendCANR_HVCMS_EVTargetVoltFD5.SendCANR_HVCMS_EVTargetVoltFD5
        DRESendCANR_HVCMSProtocolEntry{1..3}FD5: start-on-event=SendCANR_HVCMSProtocolEntry{1..3}FD5, data=SendCANR_HVCMSProtocolEntry{1..3}FD5.SendCANR_HVCMSProtocolEntry{1..3}FD5
        DRESendCANR_HVCMSReadyToChgStatFD5: start-on-event=SendCANR_HVCMSReadyToChgStatFD5, data=SendCANR_HVCMSReadyToChgStatFD5.SendCANR_HVCMSReadyToChgStatFD5
        DRESendCANR_HVCMSRemTimToBlkSOCFD5: start-on-event=SendCANR_HVCMSRemTimToBlkSOCFD5, data=SendCANR_HVCMSRemTimToBlkSOCFD5.SendCANR_HVCMSRemTimToBlkSOCFD5
        DRESendCANR_HVCMSRemTimToFulSOCFD5: start-on-event=SendCANR_HVCMSRemTimToFulSOCFD5, data=SendCANR_HVCMSRemTimToFulSOCFD5.SendCANR_HVCMSRemTimToFulSOCFD5
        DRESendCANR_HVCMSSlfEnrgTrnfTypFD5: start-on-event=SendCANR_HVCMSSlfEnrgTrnfTypFD5, data=SendCANR_HVCMSSlfEnrgTrnfTypFD5.SendCANR_HVCMSSlfEnrgTrnfTypFD5
        DRESendCANR_HVCMS_SeldPymntOptnFD5: start-on-event=SendCANR_HVCMS_SeldPymntOptnFD5, data=SendCANR_HVCMS_SeldPymntOptnFD5.SendCANR_HVCMS_SeldPymntOptnFD5
        DRESendCANR_HVCMSSelectedServIdFD5: start-on-event=SendCANR_HVCMSSelectedServIdFD5, data=SendCANR_HVCMSSelectedServIdFD5.SendCANR_HVCMSSelectedServIdFD5
        DRESendCANR_HVCMSServiceCatgoryFD5: start-on-event=SendCANR_HVCMSServiceCatgoryFD5, data=SendCANR_HVCMSServiceCatgoryFD5.SendCANR_HVCMSServiceCatgoryFD5
        DRESendCANR_HVCMS_ServiceScope_FD5: start-on-event=SendCANR_HVCMS_ServiceScope_FD5, data=SendCANR_HVCMS_ServiceScope_FD5.SendCANR_HVCMS_ServiceScope_FD5
        DRESendCANR_OBCMOutVoltSyncTgtFD15: start-on-event=SendCANR_OBCMOutVoltSyncTgtFD15, data=SendCANR_OBCMOutVoltSyncTgtFD15.SendCANR_OBCMOutVoltSyncTgtFD15
        DRESendCANR_VDCM_BattBulkSOC_FD5: start-on-event=SendCANR_VDCM_BattBulkSOC_FD5, data=SendCANR_VDCM_BattBulkSOC_FD5.SendCANR_VDCM_BattBulkSOC_FD5
        DRESendCANR_VDCM_CntrctAuthIDFD5: start-on-event=SendCANR_VDCM_CntrctAuthIDFD5, data=SendCANR_VDCM_CntrctAuthIDFD5.SendCANR_VDCM_CntrctAuthIDFD5
        DRESendCANR_VDCM_GenChallenge_FD5: start-on-event=SendCANR_VDCM_GenChallenge_FD5, data=SendCANR_VDCM_GenChallenge_FD5.SendCANR_VDCM_GenChallenge_FD5
        DRESendCANR_VDCMOBCDchaCurrLimFD5: start-on-event=SendCANR_VDCMOBCDchaCurrLimFD5, data=SendCANR_VDCMOBCDchaCurrLimFD5.SendCANR_VDCMOBCDchaCurrLimFD5
        DRESendCANR_VDCMTypeCNegotnStsFD5: start-on-event=SendCANR_VDCMTypeCNegotnStsFD5, data=SendCANR_VDCMTypeCNegotnStsFD5.SendCANR_VDCMTypeCNegotnStsFD5
        DRESendCANR_ClrLgsDiagInfo_FD5: start-on-event=SendCANR_ClrLgsDiagInfo_FD5, data=SendCANR_ClrLgsDiagInfo_FD5.SendCANR_ClrLgsDiagInfo_FD5
        DRESendCANR_T4_Sensor_Temp_FD5: start-on-event=SendCANR_T4_Sensor_Temp_FD5, data=SendCANR_T4_Sensor_Temp_FD5.SendCANR_T4_Sensor_Temp_FD5
        DRESendCANR_T7_CoolantTmpVldty_FD5: start-on-event=SendCANR_T7_CoolantTmpVldty_FD5, data=SendCANR_T7_CoolantTmpVldty_FD5.SendCANR_T7_CoolantTmpVldty_FD5
        DRESendCANR_T7_Sensor_Temp_FD5: start-on-event=SendCANR_T7_Sensor_Temp_FD5, data=SendCANR_T7_Sensor_Temp_FD5.SendCANR_T7_Sensor_Temp_FD5
        DRESendCANR_VIN_DATA_FD5: start-on-event=SendCANR_VIN_DATA_FD5, data=SendCANR_VIN_DATA_FD5.SendCANR_VIN_DATA_FD5
        DRESendCANR_VIN_MSG_FD5: start-on-event=SendCANR_VIN_MSG_FD5, data=SendCANR_VIN_MSG_FD5.SendCANR_VIN_MSG_FD5
